VERSION ""

NS_ :

BS_:

BU_: APIM_CISM APIM ESPM DSP FCIMB RACM_RCIM HUD_ADV WCM TRM_ITRM ACM GWM _delete IPC GENERIC TSTR

BO_ 549 IPC_Infotainment: 8 IPC
 SG_ BattTracLoThres_D_Rq2 : 52|3@0+ (1,0) [0|7] "SED"  GWM
 SG_ NavIod_D_Rq : 55|3@0+ (1,0) [0|7] "SED"  GWM,APIM_CISM
 SG_ StrtInGearOk_D_Stat : 17|2@0+ (1,0) [0|3] "SED"  GWM
 SG_ WwaActv_B_Stat : 46|1@0+ (1,0) [0|1] "SED"  APIM,APIM_CISM,GWM,ACM
 SG_ Veh_V2_Dsply : 39|9@0+ (1,0) [0|511] "unitless"  APIM,APIM_CISM,GWM,HUD_ADV
 SG_ IPC_MyKeyVolLimit_St : 9|2@0+ (1,0) [0|3] "SED"  APIM,APIM_CISM,GWM,DSP,ACM
 SG_ HudVertSzMnuOn_B_Rq : 21|1@0+ (1,0) [0|1] "SED"  GWM,HUD_ADV
 SG_ HudVertMnuOn_B_Rq : 11|1@0+ (1,0) [0|1] "SED"  GWM,HUD_ADV
 SG_ HudRotatMnuOn_B_Rq : 22|1@0+ (1,0) [0|1] "SED"  GWM,HUD_ADV
 SG_ HudCntntMnuOn_B_Rq : 20|1@0+ (1,0) [0|1] "SED"  GWM,HUD_ADV
 SG_ HudBrightMnuOn_B_Rq : 1|1@0+ (1,0) [0|1] "SED"  GWM,HUD_ADV
 SG_ HdcOn_B_Rq : 19|1@0+ (1,0) [0|1] "SED"  GWM
 SG_ IPC_Attn_Info_Audio : 4|3@0+ (1,0) [0|7] "SED"  APIM,APIM_CISM,GWM,DSP,ACM
 SG_ BeltminderAudioMute : 6|2@0+ (1,0) [0|3] "SED"  APIM,APIM_CISM,GWM,DSP,ACM
 SG_ Power_Up_Chime_Modules : 23|1@0+ (1,0) [0|1] "SED"  APIM_CISM,GWM,DSP,ACM
 SG_ Chime_Source : 15|2@0+ (1,0) [0|3] "SED"  APIM_CISM,GWM,DSP,ACM
 SG_ CCOI_PolicyClient_St2 : 45|4@0+ (1,0) [0|15] "SED"  GWM
 SG_ FactoryReset_Rq2 : 18|1@0+ (1,0) [0|1] "SED"  GWM
 SG_ IPC_New_Attn_Event : 0|1@0+ (1,0) [0|1] "SED"  APIM,APIM_CISM,GWM,DSP,ACM
 SG_ MetricActv_B_Dsply : 7|1@0+ (1,0) [0|1] "SED"  HUD_ADV,GWM,GENERIC

BO_ 765 Mc_Send_Signals_2: 8 IPC
 SG_ BalrSwtch_D_Stat : 57|2@0+ (1,0) [0|3] "SED"  GWM
 SG_ BalrMde_D_Rq : 59|2@0+ (1,0) [0|3] "SED"  GWM
 SG_ RstrnOnPsngr_D_RqMnu : 63|4@0+ (1,0) [0|15] "SED"  GWM
 SG_ WaitToStartLamp_D_Falt : 50|2@0+ (1,0) [0|3] "SED"  GWM
 SG_ EsaOn_B_Rq : 15|1@0+ (1,0) [0|1] "SED"  GWM
 SG_ BttOn_B_Rq : 26|1@0+ (1,0) [0|1] "SED"  GWM
 SG_ Btt_L_Actl : 39|7@0+ (0.1,0) [0|12.5] "meter"  GWM
 SG_ RearDiffLck_D_RqArb : 25|2@0+ (1,0) [0|3] "SED"  GWM
 SG_ AwdMde_D_RqArb : 47|3@0+ (1,0) [0|7] "SED"  GWM
 SG_ SelDrvMdeTxtReset_B_Rq : 40|1@0+ (1,0) [0|1] "SED"  GWM
 SG_ AutoTowAllw_D_RqMnu : 52|2@0+ (1,0) [0|3] "SED"  GWM
 SG_ DrvInputRequired_B_Rq : 32|1@0+ (1,0) [0|1] "SED"  GWM
 SG_ SelDrvMdeDsply_B_Avail : 41|1@0+ (1,0) [0|1] "SED"  GWM
 SG_ EngExhMdeQuiet_D_Rq : 17|2@0+ (1,0) [0|3] "SED"  GWM
 SG_ AirSusp_D_RqDrv : 31|2@0+ (1,0) [0|3] "SED"  GWM
 SG_ Mc_VehUntTrpCoUsrSel_St : 23|1@0+ (1,0) [0|1] "SED"  APIM,APIM_CISM,HUD_ADV,GWM
 SG_ Mc_VehUnitTempUsrSel_St : 22|1@0+ (1,0) [0|1] "SED"  APIM,APIM_CISM,HUD_ADV,RACM_RCIM,GWM
 SG_ Mc_VehDayNightUsrSel_St : 14|3@0+ (1,0) [0|7] "SED"  APIM,APIM_CISM,GWM,ACM
 SG_ Mc_VehTimeFrmtUsrSel_St : 1|2@0+ (1,0) [0|3] "SED"  APIM,APIM_CISM,GWM,HUD_ADV,RACM_RCIM
 SG_ Mc_VehThemeUsrSel_St : 11|4@0+ (1,0) [0|15] "SED"  APIM,APIM_CISM,GWM,GENERIC
 SG_ Mc_VehLangUsrSel_St : 7|6@0+ (1,0) [0|63] "SED"  APIM,APIM_CISM,HUD_ADV,ACM,GWM
 SG_ AwdRnge_D_ActlIpc : 29|3@0+ (1,0) [0|7] "SED"  GWM
 SG_ AwdDrvMde_D_Rq : 44|3@0+ (1,0) [0|7] "SED"  GWM
 SG_ EngExhMdeQuiet_D2_Rq : 55|3@0+ (1,0) [0|7] "SED"  GWM
 SG_ BrkLineLck_D_Rq : 19|2@0+ (1,0) [0|3] "SED"  GWM
 SG_ EdmSailMde_B_RqDrv : 48|1@0+ (1,0) [0|1] "SED"  GWM
 SG_ Running_Board_Cmd : 21|2@0+ (1,0) [0|3] "SED"  GWM

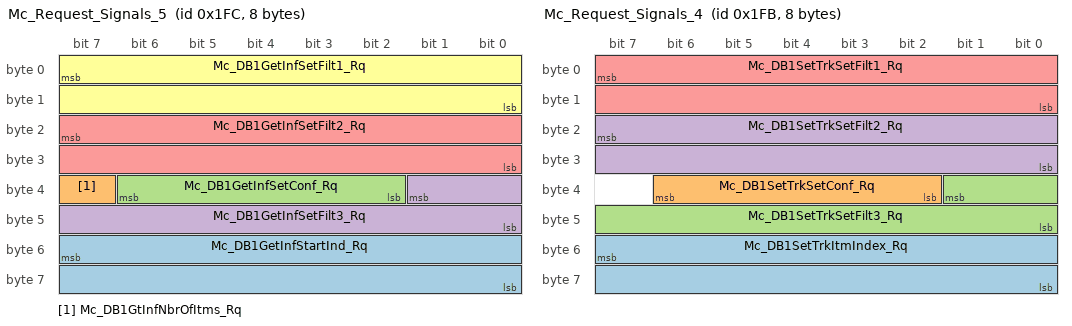
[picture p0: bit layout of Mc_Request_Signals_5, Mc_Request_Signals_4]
BO_ 508 Mc_Request_Signals_5: 8 IPC
 SG_ Mc_DB1GetInfStartInd_Rq : 55|16@0+ (1,0) [0|65535] "unitless"  APIM_CISM,ACM,GWM
 SG_ Mc_DB1GtInfNbrOfItms_Rq : 39|1@0+ (1,0) [0|1] "SED"  APIM_CISM,ACM,GWM
 SG_ Mc_DB1GetInfSetConf_Rq : 38|5@0+ (1,0) [0|31] "SED"  APIM_CISM,ACM,GWM
 SG_ Mc_DB1GetInfSetFilt3_Rq : 33|10@0+ (1,0) [0|1023] "unitless"  APIM_CISM,ACM,GWM
 SG_ Mc_DB1GetInfSetFilt2_Rq : 23|16@0+ (1,0) [0|65535] "unitless"  APIM_CISM,ACM,GWM
 SG_ Mc_DB1GetInfSetFilt1_Rq : 7|16@0+ (1,0) [0|65535] "unitless"  APIM_CISM,ACM,GWM

BO_ 507 Mc_Request_Signals_4: 8 IPC
 SG_ Mc_DB1SetTrkItmIndex_Rq : 55|16@0+ (1,0) [0|65535] "unitless"  APIM_CISM,ACM,GWM
 SG_ Mc_DB1SetTrkSetConf_Rq : 38|5@0+ (1,0) [0|31] "SED"  APIM_CISM,ACM,GWM
 SG_ Mc_DB1SetTrkSetFilt3_Rq : 33|10@0+ (1,0) [0|1023] "unitless"  APIM_CISM,ACM,GWM
 SG_ Mc_DB1SetTrkSetFilt2_Rq : 23|16@0+ (1,0) [0|65535] "unitless"  APIM_CISM,ACM,GWM
 SG_ Mc_DB1SetTrkSetFilt1_Rq : 7|16@0+ (1,0) [0|65535] "unitless"  APIM_CISM,ACM,GWM

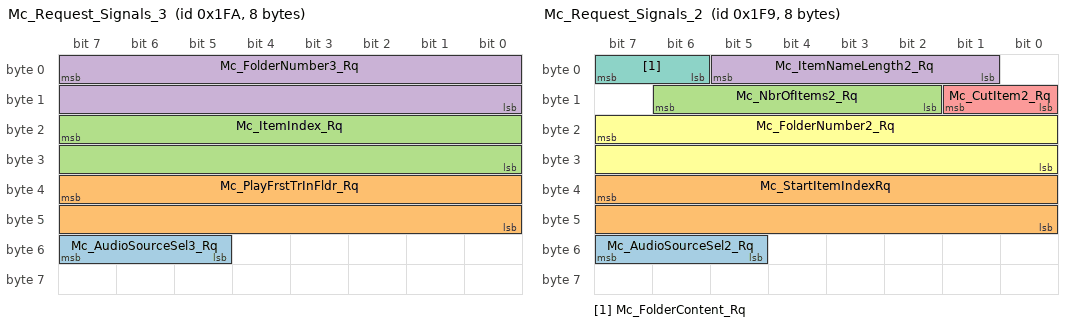
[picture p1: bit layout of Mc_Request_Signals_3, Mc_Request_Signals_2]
BO_ 506 Mc_Request_Signals_3: 8 IPC
 SG_ Mc_AudioSourceSel3_Rq : 55|3@0+ (1,0) [0|7] "SED"  APIM_CISM,ACM,GWM
 SG_ Mc_PlayFrstTrInFldr_Rq : 39|16@0+ (1,0) [0|65535] "unitless"  APIM_CISM,ACM,GWM
 SG_ Mc_ItemIndex_Rq : 23|16@0+ (1,0) [0|65535] "unitless"  APIM_CISM,ACM,GWM
 SG_ Mc_FolderNumber3_Rq : 7|16@0+ (1,0) [0|65535] "unitless"  APIM_CISM,ACM,GWM

BO_ 505 Mc_Request_Signals_2: 8 IPC
 SG_ Mc_AudioSourceSel2_Rq : 55|3@0+ (1,0) [0|7] "SED"  APIM_CISM,ACM,GWM
 SG_ Mc_StartItemIndexRq : 39|16@0+ (1,0) [0|65535] "unitless"  APIM_CISM,ACM,GWM
 SG_ Mc_NbrOfItems2_Rq : 14|5@0+ (1,0) [0|20] "SED"  APIM_CISM,ACM,GWM
 SG_ Mc_ItemNameLength2_Rq : 5|5@0+ (1,0) [0|20] "SED"  APIM_CISM,ACM,GWM
 SG_ Mc_CutItem2_Rq : 9|2@0+ (1,0) [0|3] "SED"  APIM_CISM,ACM,GWM
 SG_ Mc_FolderNumber2_Rq : 23|16@0+ (1,0) [0|65535] "unitless"  APIM_CISM,ACM,GWM
 SG_ Mc_FolderContent_Rq : 7|2@0+ (1,0) [0|3] "SED"  APIM_CISM,ACM,GWM

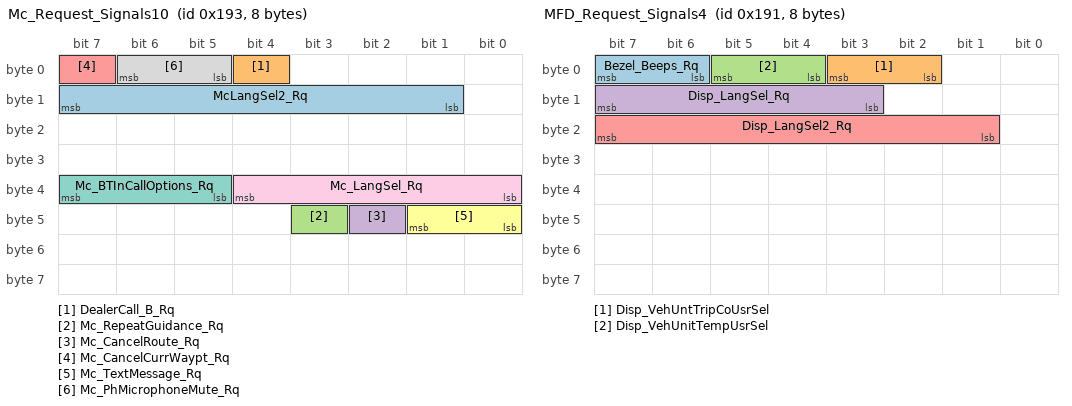
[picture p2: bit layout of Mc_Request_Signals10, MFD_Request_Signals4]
BO_ 403 Mc_Request_Signals10: 8 IPC
 SG_ McLangSel2_Rq : 15|7@0+ (1,0) [0|7] "SED"  APIM,APIM_CISM,GWM
 SG_ DealerCall_B_Rq : 4|1@0+ (1,0) [0|1] "SED"  APIM,APIM_CISM,GWM
 SG_ Mc_RepeatGuidance_Rq : 43|1@0+ (1,0) [0|1] "SED"  APIM,APIM_CISM,GWM
 SG_ Mc_CancelRoute_Rq : 42|1@0+ (1,0) [0|1] "SED"  APIM,APIM_CISM,GWM
 SG_ Mc_CancelCurrWaypt_Rq : 7|1@0+ (1,0) [0|1] "SED"  APIM,APIM_CISM,GWM
 SG_ Mc_TextMessage_Rq : 41|2@0+ (1,0) [0|3] "SED"  APIM,APIM_CISM,GWM
 SG_ Mc_BTInCallOptions_Rq : 39|3@0+ (1,0) [0|7] "SED"  APIM,APIM_CISM,GWM
 SG_ Mc_PhMicrophoneMute_Rq : 6|2@0+ (1,0) [0|3] "SED"  APIM,APIM_CISM,GWM
 SG_ Mc_LangSel_Rq : 36|5@0+ (1,0) [0|31] "SED"  APIM,APIM_CISM,GWM

BO_ 401 MFD_Request_Signals4: 8 APIM
 SG_ Bezel_Beeps_Rq : 7|2@0+ (1,0) [0|3] "SED"  FCIMB,GWM
 SG_ Disp_VehUntTripCoUsrSel : 3|2@0+ (1,0) [0|3] "SED"  GWM,IPC
 SG_ Disp_VehUnitTempUsrSel : 5|2@0+ (1,0) [0|3] "SED"  GWM,IPC
 SG_ Disp_LangSel_Rq : 15|5@0+ (1,0) [0|31] "SED"  GWM,IPC
 SG_ Disp_LangSel2_Rq : 23|7@0+ (1,0) [0|127] "SED"  IPC

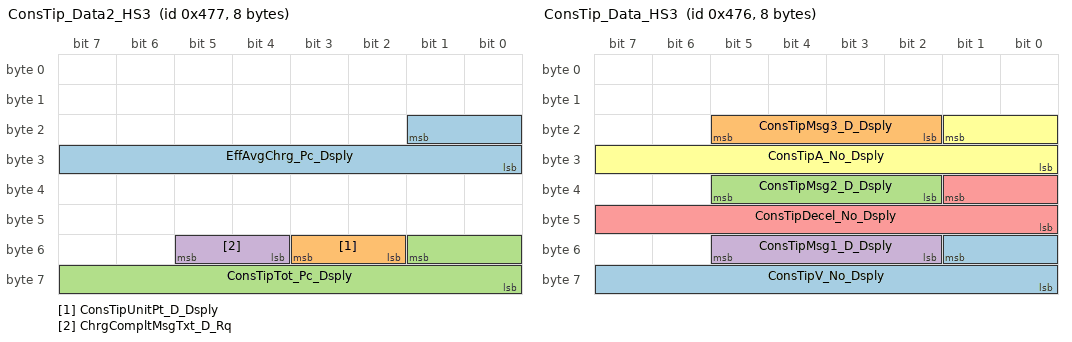
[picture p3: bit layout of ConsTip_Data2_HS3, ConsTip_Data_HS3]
BO_ 1143 ConsTip_Data2_HS3: 8 GWM
 SG_ EffAvgChrg_Pc_Dsply : 17|10@0+ (0.1,0) [0|102.3] "percent"  APIM_CISM,IPC
 SG_ ConsTipUnitPt_D_Dsply : 51|2@0+ (1,0) [0|3] "SED"  APIM,APIM_CISM,IPC
 SG_ ConsTipTot_Pc_Dsply : 49|10@0+ (0.1,0) [0|102.1] "percent"  IPC
 SG_ ChrgCompltMsgTxt_D_Rq : 53|2@0+ (1,0) [0|3] "SED"  APIM,APIM_CISM,IPC

BO_ 1142 ConsTip_Data_HS3: 8 GWM
 SG_ ConsTipV_No_Dsply : 49|10@0+ (0.1,0) [0|102.1] "percent"  APIM,APIM_CISM,IPC
 SG_ ConsTipMsg3_D_Dsply : 21|4@0+ (1,0) [0|15] "SED"  APIM,APIM_CISM,IPC
 SG_ ConsTipMsg2_D_Dsply : 37|4@0+ (1,0) [0|15] "SED"  APIM,APIM_CISM,IPC
 SG_ ConsTipMsg1_D_Dsply : 53|4@0+ (1,0) [0|15] "SED"  APIM,APIM_CISM,IPC
 SG_ ConsTipDecel_No_Dsply : 33|10@0+ (0.1,0) [0|102.1] "percent"  APIM,APIM_CISM,IPC
 SG_ ConsTipA_No_Dsply : 17|10@0+ (0.1,0) [0|102.1] "percent"  APIM,APIM_CISM,IPC

BO_ 973 Traffic_RecogitionData_HS3: 8 GWM
 SG_ PersCtaSplitView_D_Stat : 12|2@0+ (1,0) [0|3] "SED"  APIM,APIM_CISM
 SG_ LaSysOffStat_D_Dsply : 58|2@0+ (1,0) [0|3] "SED"  IPC
 SG_ TsrVl1RstrcMsgTxt2_D_Rq : 51|3@0+ (1,0) [0|7] "SED"  APIM_CISM,HUD_ADV,IPC
 SG_ TsrVl2RstrcMsgTxt2_D_Rq : 63|3@0+ (1,0) [0|7] "SED"  APIM_CISM,HUD_ADV,IPC
 SG_ TsrVl2PrmntMsgTxt_D_Rq : 60|2@0+ (1,0) [0|3] "SED"  APIM_CISM,HUD_ADV,IPC
 SG_ TsrVl1PrmntMsgTxt_D_Rq : 41|2@0+ (1,0) [0|3] "SED"  APIM_CISM,HUD_ADV,IPC
 SG_ TsrOvtkMsgTxt2_D_Rq : 55|4@0+ (1,0) [0|15] "SED"  APIM_CISM,HUD_ADV,IPC
 SG_ WwaWarn_B_Rq : 48|1@0+ (1,0) [0|1] "SED"  APIM_CISM,HUD_ADV,IPC
 SG_ RoadSignRgltry_D_Dsply : 19|2@0+ (1,0) [0|3] "SED"  IPC
 SG_ TsrVlUnitMsgTxt_D_Rq : 43|2@0+ (1,0) [0|3] "SED"  APIM,APIM_CISM,HUD_ADV,IPC
 SG_ TsrVLim2MsgTxt_D_Rq : 39|8@0+ (1,0) [0|255] "SED"  APIM_CISM,HUD_ADV,IPC
 SG_ TsrVLim1MsgTxt_D_Rq : 31|8@0+ (1,0) [0|255] "SED"  APIM_CISM,HUD_ADV,IPC
 SG_ TsrVl2StatMsgTxt_D_Rq : 47|2@0+ (1,0) [0|3] "SED"  APIM_CISM,HUD_ADV,IPC
 SG_ TsrVl2RstrcMsgTxt_D_Rq : 17|2@0+ (1,0) [0|3] "SED"  APIM_CISM,IPC
 SG_ TsrVl1StatMsgTxt_D_Rq : 21|2@0+ (1,0) [0|3] "SED"  APIM_CISM,HUD_ADV,IPC
 SG_ TsrVl1RstrcMsgTxt_D_Rq : 23|2@0+ (1,0) [0|3] "SED"  APIM_CISM,IPC
 SG_ TsrStatMsgTxt_D_Rq : 10|3@0+ (1,0) [0|7] "SED"  APIM_CISM,IPC
 SG_ TsrOvtkStatMsgTxt_D_Rq : 1|2@0+ (1,0) [0|3] "SED"  APIM_CISM,HUD_ADV,IPC
 SG_ TsrOvtkMsgTxt_D_Rq : 15|3@0+ (1,0) [0|7] "SED"  APIM_CISM,HUD_ADV,IPC
 SG_ TsrOswWarnMsgTxt_D_Rq : 3|2@0+ (1,0) [0|3] "SED"  APIM_CISM,HUD_ADV,IPC
 SG_ TsrMsgTxt_D_Rq : 7|4@0+ (1,0) [0|15] "SED"  APIM_CISM,IPC

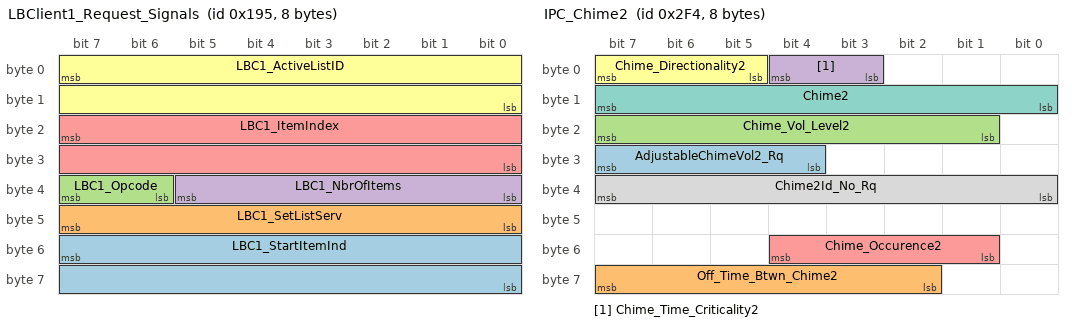
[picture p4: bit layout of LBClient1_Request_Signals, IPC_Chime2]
BO_ 405 LBClient1_Request_Signals: 8 IPC
 SG_ LBC1_StartItemInd : 55|16@0+ (1,0) [0|65535] "unitless"  APIM,APIM_CISM,GWM,ACM
 SG_ LBC1_SetListServ : 47|8@0+ (1,0) [0|255] "unitless"  APIM,APIM_CISM,GWM,ACM
 SG_ LBC1_Opcode : 39|2@0+ (1,0) [0|3] "SED"  APIM,APIM_CISM,GWM,ACM
 SG_ LBC1_NbrOfItems : 37|6@0+ (1,0) [0|63] "unitless"  APIM,APIM_CISM,GWM,ACM
 SG_ LBC1_ItemIndex : 23|16@0+ (1,0) [0|65535] "unitless"  APIM,APIM_CISM,GWM,ACM
 SG_ LBC1_ActiveListID : 7|16@0+ (1,0) [0|65535] "unitless"  APIM,APIM_CISM,GWM,ACM

BO_ 756 IPC_Chime2: 8 IPC
 SG_ AdjustableChimeVol2_Rq : 31|4@0+ (1,0) [0|15] "SED"  APIM_CISM,GWM,ACM,DSP
 SG_ Off_Time_Btwn_Chime2 : 63|6@0+ (1,0) [0|52] "unitless"  APIM_CISM,GWM,DSP,ACM
 SG_ Chime_Vol_Level2 : 23|7@0+ (1,0) [0|127] "unitless"  APIM_CISM,GWM,DSP,ACM
 SG_ Chime_Time_Criticality2 : 4|2@0+ (1,0) [0|3] "SED"  APIM_CISM,GWM,DSP,ACM
 SG_ Chime_Occurence2 : 52|4@0+ (1,0) [0|15] "SED"  APIM_CISM,GWM,DSP,ACM
 SG_ Chime_Directionality2 : 7|3@0+ (1,0) [0|7] "SED"  APIM_CISM,GWM,DSP,ACM
 SG_ Chime2 : 15|8@0+ (1,0) [0|255] "unitless"  APIM_CISM,GWM,DSP,ACM
 SG_ Chime2Id_No_Rq : 39|8@0+ (1,0) [0|255] "SED"  APIM_CISM,DSP,ACM

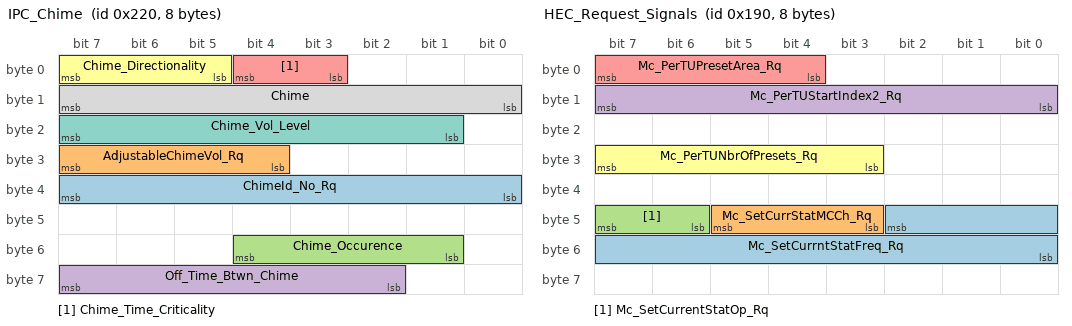
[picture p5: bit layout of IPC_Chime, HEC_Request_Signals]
BO_ 544 IPC_Chime: 8 IPC
 SG_ ChimeId_No_Rq : 39|8@0+ (1,0) [0|255] "SED"  APIM_CISM,GWM,ACM
 SG_ AdjustableChimeVol_Rq : 31|4@0+ (1,0) [0|15] "SED"  APIM_CISM,GWM,ACM,DSP
 SG_ Chime_Occurence : 52|4@0+ (1,0) [0|15] "SED"  APIM_CISM,GWM,DSP,ACM
 SG_ Off_Time_Btwn_Chime : 63|6@0+ (1,0) [0|52] "unitless"  APIM_CISM,GWM,DSP,ACM
 SG_ Chime_Time_Criticality : 4|2@0+ (1,0) [0|3] "SED"  APIM_CISM,GWM,DSP,ACM
 SG_ Chime_Directionality : 7|3@0+ (1,0) [0|7] "SED"  APIM_CISM,GWM,DSP,ACM
 SG_ Chime_Vol_Level : 23|7@0+ (1,0) [0|127] "unitless"  APIM_CISM,GWM,DSP,ACM
 SG_ Chime : 15|8@0+ (1,0) [0|255] "unitless"  APIM_CISM,GWM,DSP,ACM

BO_ 291 HEC_Response_Signals: 8 IPC
 SG_ LangUpdate_Rsp : 7|2@0+ (1,0) [0|3] "SED"  APIM,APIM_CISM,GWM

BO_ 400 HEC_Request_Signals: 8 IPC
 SG_ Mc_SetCurrntStatFreq_Rq : 42|11@0+ (1,0) [0|1557] "unitless"  GWM,APIM_CISM,ACM
 SG_ Mc_SetCurrStatMCCh_Rq : 45|3@0+ (1,0) [0|7] "SED"  GWM,APIM_CISM,ACM
 SG_ Mc_SetCurrentStatOp_Rq : 47|2@0+ (1,0) [0|3] "SED"  GWM,APIM_CISM,ACM
 SG_ Mc_PerTUStartIndex2_Rq : 15|8@0+ (1,0) [0|255] "unitless"  APIM,APIM_CISM,ACM,GWM
 SG_ Mc_PerTUPresetArea_Rq : 7|4@0+ (1,0) [0|15] "SED"  APIM,APIM_CISM,ACM,GWM
 SG_ Mc_PerTUNbrOfPresets_Rq : 31|5@0+ (1,0) [0|31] "SED"  APIM,APIM_CISM,ACM,GWM

BO_ 647 HEC_DispDimm: 8 IPC
 SG_ HEC_BTIncomingCall_Rq : 23|2@0+ (1,0) [0|3] "SED"  APIM,APIM_CISM
 SG_ HEC_BTEndTelService_Rq : 3|2@0+ (1,0) [0|3] "SED"  APIM,APIM_CISM

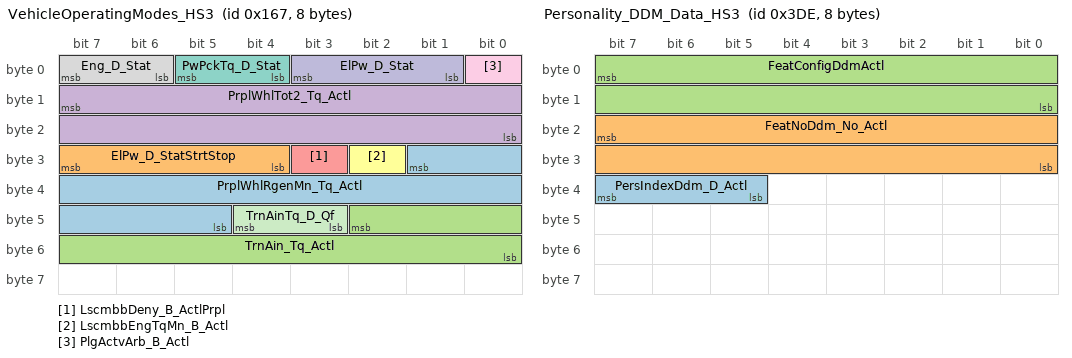
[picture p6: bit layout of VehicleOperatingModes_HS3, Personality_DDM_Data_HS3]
BO_ 359 VehicleOperatingModes_HS3: 8 GWM
 SG_ PrplWhlRgenMn_Tq_Actl : 25|13@0+ (4,-16380) [-16380|16380] "Nm"  GENERIC
 SG_ ElPw_D_StatStrtStop : 31|4@0+ (1,0) [0|15] "SED"  GENERIC
 SG_ TrnAin_Tq_Actl : 42|11@0+ (1,-500) [-500|1547] "Nm"  APIM,APIM_CISM,IPC,ACM
 SG_ PrplWhlTot2_Tq_Actl : 15|16@0+ (4,-131072) [-131072|131060] "Nm"  APIM,APIM_CISM,IPC
 SG_ LscmbbDeny_B_ActlPrpl : 27|1@0+ (1,0) [0|1] "SED"  GENERIC
 SG_ LscmbbEngTqMn_B_Actl : 26|1@0+ (1,0) [0|1] "SED"  GENERIC
 SG_ PwPckTq_D_Stat : 5|2@0+ (1,0) [0|3] "SED"  APIM,APIM_CISM,RACM_RCIM,TRM_ITRM,DSP,ACM,WCM,IPC
 SG_ Eng_D_Stat : 7|2@0+ (1,0) [0|3] "SED"  APIM,APIM_CISM,RACM_RCIM,TRM_ITRM,WCM,DSP,ACM
 SG_ PlgActvArb_B_Actl : 0|1@0+ (1,0) [0|1] "SED"  IPC
 SG_ ElPw_D_Stat : 3|3@0+ (1,0) [0|7] "SED"  APIM,APIM_CISM,RACM_RCIM,TRM_ITRM,DSP,ACM,IPC
 SG_ TrnAinTq_D_Qf : 44|2@0+ (1,0) [0|3] "SED"  APIM_CISM,ACM

BO_ 990 Personality_DDM_Data_HS3: 8 GWM
 SG_ PersIndexDdm_D_Actl : 39|3@0+ (1,0) [0|7] "SED"  APIM,APIM_CISM,IPC
 SG_ FeatNoDdm_No_Actl : 23|16@0+ (1,0) [0|65535] "Number"  APIM,APIM_CISM,IPC
 SG_ FeatConfigDdmActl : 7|16@0+ (1,0) [0|65535] "Undefined"  APIM,APIM_CISM,IPC

BO_ 989 Personality_HCM_Data_HS3: 8 GWM
 SG_ FeatNoHcm_No_Actl : 23|16@0+ (1,0) [0|65535] "Number"  APIM,APIM_CISM,IPC
 SG_ FeatConfigHcmActl : 7|16@0+ (1,0) [0|65535] "Undefined"  APIM,APIM_CISM,IPC

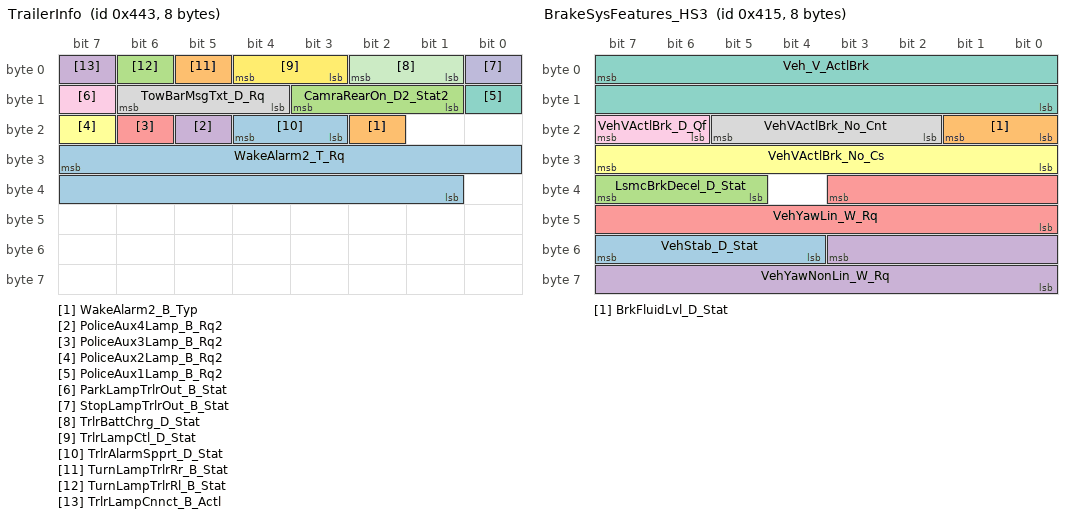
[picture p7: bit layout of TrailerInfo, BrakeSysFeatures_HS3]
BO_ 1091 TrailerInfo: 8 TRM_ITRM
 SG_ WakeAlarm2_T_Rq : 31|15@0+ (1,0) [0|32767] "minute"  GWM
 SG_ WakeAlarm2_B_Typ : 18|1@0+ (1,0) [0|1] "SED"  GWM
 SG_ CamraRearOn_D2_Stat2 : 11|3@0+ (1,0) [0|7] "SED"  APIM,APIM_CISM,GWM
 SG_ PoliceAux4Lamp_B_Rq2 : 21|1@0+ (1,0) [0|1] "SED"  IPC,GWM
 SG_ PoliceAux3Lamp_B_Rq2 : 22|1@0+ (1,0) [0|1] "SED"  IPC,GWM
 SG_ PoliceAux2Lamp_B_Rq2 : 23|1@0+ (1,0) [0|1] "SED"  IPC,GWM
 SG_ PoliceAux1Lamp_B_Rq2 : 8|1@0+ (1,0) [0|1] "SED"  IPC,GWM
 SG_ TowBarMsgTxt_D_Rq : 14|3@0+ (1,0) [0|7] "SED"  IPC,GWM
 SG_ ParkLampTrlrOut_B_Stat : 15|1@0+ (1,0) [0|1] "SED"  IPC,GWM
 SG_ StopLampTrlrOut_B_Stat : 0|1@0+ (1,0) [0|1] "SED"  IPC,GWM
 SG_ TrlrBattChrg_D_Stat : 2|2@0+ (1,0) [0|3] "SED"  IPC,GWM
 SG_ TrlrLampCtl_D_Stat : 4|2@0+ (1,0) [0|3] "SED"  IPC,GWM
 SG_ TrlrAlarmSpprt_D_Stat : 20|2@0+ (1,0) [0|3] "SED"  APIM,APIM_CISM,GWM
 SG_ TurnLampTrlrRr_B_Stat : 5|1@0+ (1,0) [0|1] "SED"  IPC,GWM
 SG_ TurnLampTrlrRl_B_Stat : 6|1@0+ (1,0) [0|1] "SED"  IPC,GWM
 SG_ TrlrLampCnnct_B_Actl : 7|1@0+ (1,0) [0|1] "SED"  APIM,APIM_CISM,IPC,GWM

BO_ 1045 BrakeSysFeatures_HS3: 8 GWM
 SG_ VehStab_D_Stat : 55|4@0+ (1,0) [0|15] "SED" Vector__XXX
 SG_ BrkFluidLvl_D_Stat : 17|2@0+ (1,0) [0|3] "SED" Vector__XXX
 SG_ LsmcBrkDecel_D_Stat : 39|3@0+ (1,0) [0|7] "SED" Vector__XXX
 SG_ VehYawNonLin_W_Rq : 51|12@0+ (0.03663,-75) [-75|74.92659] "deg/s" Vector__XXX
 SG_ VehYawLin_W_Rq : 35|12@0+ (0.03663,-75) [-75|74.92659] "deg/s" Vector__XXX
 SG_ VehVActlBrk_No_Cs : 31|8@0+ (1,0) [0|255] "unitless"  TRM_ITRM
 SG_ Veh_V_ActlBrk : 7|16@0+ (0.01,0) [0|655.35] "kph"  TRM_ITRM
 SG_ VehVActlBrk_No_Cnt : 21|4@0+ (1,0) [0|15] "unitless"  TRM_ITRM
 SG_ VehVActlBrk_D_Qf : 23|2@0+ (1,0) [0|3] "SED"  TRM_ITRM

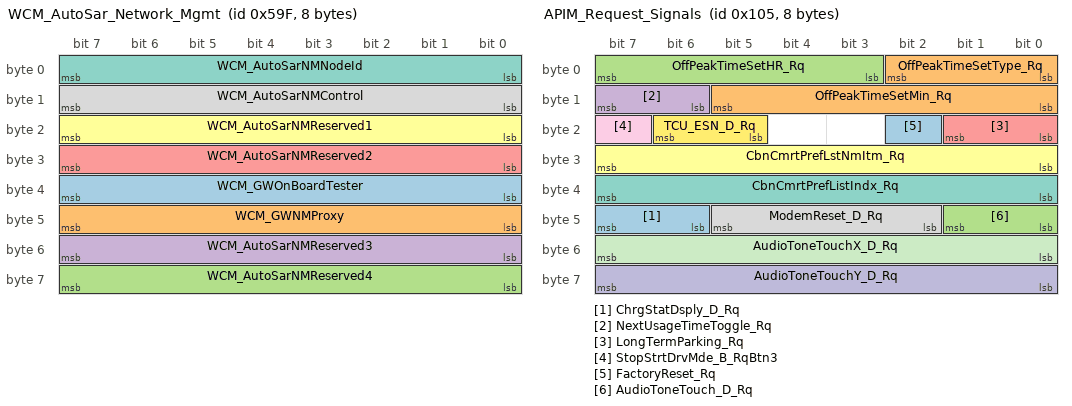
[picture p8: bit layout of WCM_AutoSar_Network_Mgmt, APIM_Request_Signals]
BO_ 1439 WCM_AutoSar_Network_Mgmt: 8 WCM
 SG_ WCM_GWOnBoardTester : 39|8@0+ (1,0) [0|255] "unitless"  IPC,HUD_ADV,GENERIC,ACM
 SG_ WCM_GWNMProxy : 47|8@0+ (1,0) [0|255] "unitless"  IPC,HUD_ADV,GENERIC,ACM
 SG_ WCM_AutoSarNMReserved4 : 63|8@0+ (1,0) [0|255] "unitless"  IPC,HUD_ADV,GENERIC,ACM
 SG_ WCM_AutoSarNMReserved3 : 55|8@0+ (1,0) [0|255] "unitless"  IPC,HUD_ADV,GENERIC,ACM
 SG_ WCM_AutoSarNMReserved2 : 31|8@0+ (1,0) [0|255] "unitless"  IPC,HUD_ADV,GENERIC,ACM
 SG_ WCM_AutoSarNMReserved1 : 23|8@0+ (1,0) [0|255] "unitless"  IPC,HUD_ADV,GENERIC,ACM
 SG_ WCM_AutoSarNMNodeId : 7|8@0+ (1,0) [0|255] "unitless"  IPC,HUD_ADV,GENERIC,ACM
 SG_ WCM_AutoSarNMControl : 15|8@0+ (1,0) [0|255] "unitless"  IPC,HUD_ADV,GENERIC,ACM

BO_ 261 APIM_Request_Signals: 8 ACM
 SG_ ChrgStatDsply_D_Rq : 47|2@0+ (1,0) [0|3] "SED"  GWM
 SG_ OffPeakTimeSetMin_Rq : 13|6@0+ (1,0) [0|63] "unitless"  GWM
 SG_ OffPeakTimeSetHR_Rq : 7|5@0+ (1,0) [0|31] "unitless"  GWM
 SG_ NextUsageTimeToggle_Rq : 15|2@0+ (1,0) [0|3] "SED"  GWM
 SG_ LongTermParking_Rq : 17|2@0+ (1,0) [0|3] "SED"  GWM
 SG_ CbnCmrtPrefLstNmItm_Rq : 31|8@0+ (1,0) [0|255] "unitless"  GWM
 SG_ CbnCmrtPrefListIndx_Rq : 39|8@0+ (1,0) [0|255] "unitless"  GWM
 SG_ ModemReset_D_Rq : 45|4@0+ (1,0) [0|15] "SED"  GWM
 SG_ StopStrtDrvMde_B_RqBtn3 : 23|1@0+ (1,0) [0|1] "SED"  GWM
 SG_ AudioToneTouchY_D_Rq : 63|8@0+ (1,0) [0|255] "SED"  DSP,GWM
 SG_ AudioToneTouchX_D_Rq : 55|8@0+ (1,0) [0|255] "SED"  DSP,GWM
 SG_ TCU_ESN_D_Rq : 22|2@0+ (1,0) [0|3] "SED"  GWM
 SG_ FactoryReset_Rq : 18|1@0+ (1,0) [0|1] "SED"  GWM
 SG_ OffPeakTimeSetType_Rq : 2|3@0+ (1,0) [0|7] "SED"  GWM
 SG_ AudioToneTouch_D_Rq : 41|2@0+ (1,0) [0|3] "SED"  DSP,GWM

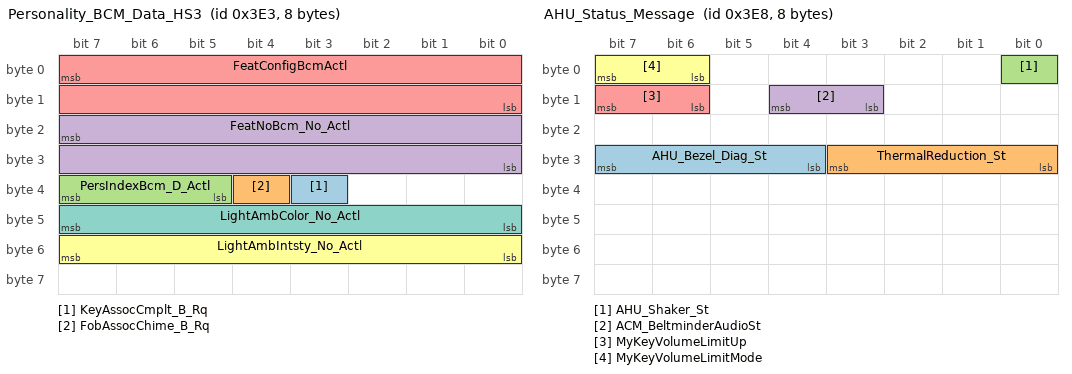
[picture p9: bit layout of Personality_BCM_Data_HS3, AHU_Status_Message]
BO_ 995 Personality_BCM_Data_HS3: 8 GWM
 SG_ KeyAssocCmplt_B_Rq : 35|1@0+ (1,0) [0|1] "SED"  IPC
 SG_ FobAssocChime_B_Rq : 36|1@0+ (1,0) [0|1] "SED"  IPC
 SG_ PersIndexBcm_D_Actl : 39|3@0+ (1,0) [0|7] "SED"  APIM,APIM_CISM,IPC
 SG_ FeatNoBcm_No_Actl : 23|16@0+ (1,0) [0|65535] "Number"  APIM,APIM_CISM,IPC
 SG_ FeatConfigBcmActl : 7|16@0+ (1,0) [0|65535] "Undefined"  APIM,APIM_CISM,IPC
 SG_ LightAmbIntsty_No_Actl : 55|8@0+ (1,0) [0|255] "unitless"  APIM,APIM_CISM
 SG_ LightAmbColor_No_Actl : 47|8@0+ (1,0) [0|255] "Discrete"  APIM,APIM_CISM

BO_ 753 Vehicle_Stat: 8 APIM
 SG_ RollCodeValet : 7|16@0+ (1,0) [0|65535] "unitless"  GWM

BO_ 1000 AHU_Status_Message: 8 ACM
 SG_ AHU_Bezel_Diag_St : 31|4@0+ (1,0) [0|15] "SED"  APIM
 SG_ ThermalReduction_St : 27|4@0+ (1,0) [0|15] "SED"  DSP
 SG_ AHU_Shaker_St : 0|1@0+ (1,0) [0|1] "SED"  APIM,GWM
 SG_ ACM_BeltminderAudioSt : 12|2@0+ (1,0) [0|3] "SED"  APIM,IPC
 SG_ MyKeyVolumeLimitUp : 15|2@0+ (1,0) [0|3] "SED"  APIM
 SG_ MyKeyVolumeLimitMode : 7|2@0+ (1,0) [0|3] "SED"  APIM

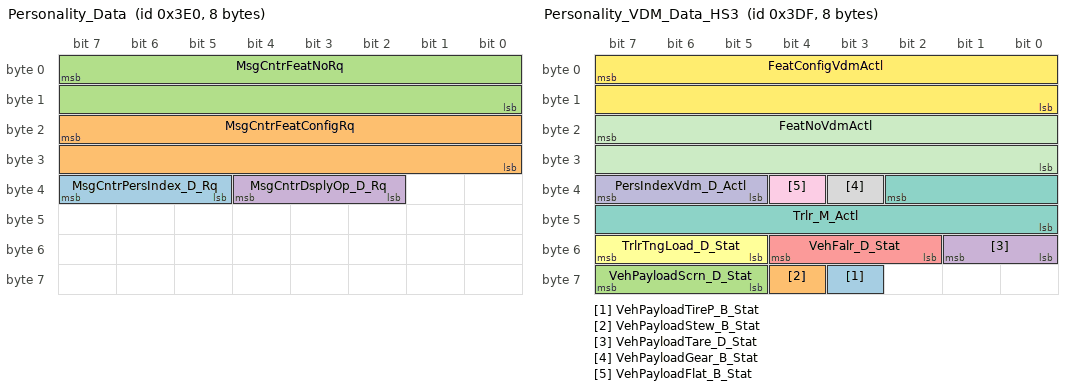
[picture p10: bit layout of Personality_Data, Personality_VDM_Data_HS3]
BO_ 992 Personality_Data: 8 IPC
 SG_ MsgCntrPersIndex_D_Rq : 39|3@0+ (1,0) [0|7] "SED"  HUD_ADV,GWM
 SG_ MsgCntrFeatConfigRq : 23|16@0+ (1,0) [0|65535] "unitless"  HUD_ADV,GWM
 SG_ MsgCntrFeatNoRq : 7|16@0+ (1,0) [0|65535] "Number"  HUD_ADV,GWM
 SG_ MsgCntrDsplyOp_D_Rq : 36|3@0+ (1,0) [0|7] "SED"  HUD_ADV,GWM

BO_ 991 Personality_VDM_Data_HS3: 8 GWM
 SG_ VehPayloadTireP_B_Stat : 59|1@0+ (1,0) [0|1] "SED"  APIM,APIM_CISM
 SG_ VehPayloadStew_B_Stat : 60|1@0+ (1,0) [0|1] "SED"  APIM,APIM_CISM
 SG_ VehPayloadScrn_D_Stat : 63|3@0+ (1,0) [0|7] "SED"  APIM,APIM_CISM
 SG_ VehPayloadTare_D_Stat : 49|2@0+ (1,0) [0|3] "SED"  APIM,APIM_CISM
 SG_ VehFalr_D_Stat : 52|3@0+ (1,0) [0|7] "SED"  APIM,APIM_CISM
 SG_ TrlrTngLoad_D_Stat : 55|3@0+ (1,0) [0|7] "SED" Vector__XXX
 SG_ Trlr_M_Actl : 34|11@0+ (10,0) [0|20450] "kilogram"  APIM,APIM_CISM
 SG_ VehPayloadGear_B_Stat : 35|1@0+ (1,0) [0|1] "SED"  APIM,APIM_CISM
 SG_ VehPayloadFlat_B_Stat : 36|1@0+ (1,0) [0|1] "SED"  APIM,APIM_CISM
 SG_ PersIndexVdm_D_Actl : 39|3@0+ (1,0) [0|7] "SED"  APIM,APIM_CISM,IPC
 SG_ FeatNoVdmActl : 23|16@0+ (1,0) [0|65535] "Number"  APIM,APIM_CISM,IPC
 SG_ FeatConfigVdmActl : 7|16@0+ (1,0) [0|65535] "Undefined"  APIM,APIM_CISM,IPC

BO_ 1004 Personality_BCM2_Data_HS3: 8 GWM
 SG_ TailLghtLoadMde_D_Stat : 60|3@0+ (1,0) [0|7] "SED"  APIM,APIM_CISM
 SG_ PersRecallSrc_D_Actl : 63|3@0+ (1,0) [0|7] "SED" Vector__XXX
 SG_ Pers4Key_D_Stat : 49|2@0+ (1,0) [0|3] "SED"  APIM,APIM_CISM
 SG_ Pers3Key_D_Stat : 41|2@0+ (1,0) [0|3] "SED"  APIM,APIM_CISM
 SG_ Pers2Key_D_Stat : 43|2@0+ (1,0) [0|3] "SED"  APIM,APIM_CISM
 SG_ Pers1Key_D_Stat : 12|2@0+ (1,0) [0|3] "SED"  APIM,APIM_CISM
 SG_ EmPrflKeyAssoc_D_Stat : 55|3@0+ (1,0) [0|7] "SED"  APIM,APIM_CISM
 SG_ VehKeyActv_D_Stat : 47|4@0+ (1,0) [0|15] "SED"  IPC
 SG_ PersSetupRestr_D_Actl : 21|2@0+ (1,0) [0|3] "SED"  APIM,APIM_CISM
 SG_ PersSetupAccessCtrl : 19|1@0+ (1,0) [0|1] "SED"  APIM,APIM_CISM
 SG_ PersSetup_No_Actl : 31|16@0+ (1,0) [0|65535] "Number"  APIM,APIM_CISM
 SG_ PersConflict_D_Actl : 22|1@0+ (1,0) [0|1] "SED"  APIM,APIM_CISM
 SG_ AssocConfirm_D_Actl : 15|3@0+ (1,0) [0|7] "SED"  APIM,APIM_CISM
 SG_ RecallEvent_No_Cnt : 7|8@0+ (1,0) [0|255] "Counts"  APIM,APIM_CISM,DSP,HUD_ADV,IPC,ACM
 SG_ PersNoPos_D_Actl : 18|3@0+ (1,0) [0|7] "SED"  APIM,APIM_CISM,IPC
 SG_ PersNo_D_Actl : 10|3@0+ (1,0) [0|7] "SED"  APIM,APIM_CISM,DSP,ACM,IPC
 SG_ EmPrflNo_D_Stat : 52|3@0+ (1,0) [0|7] "SED"  APIM,APIM_CISM

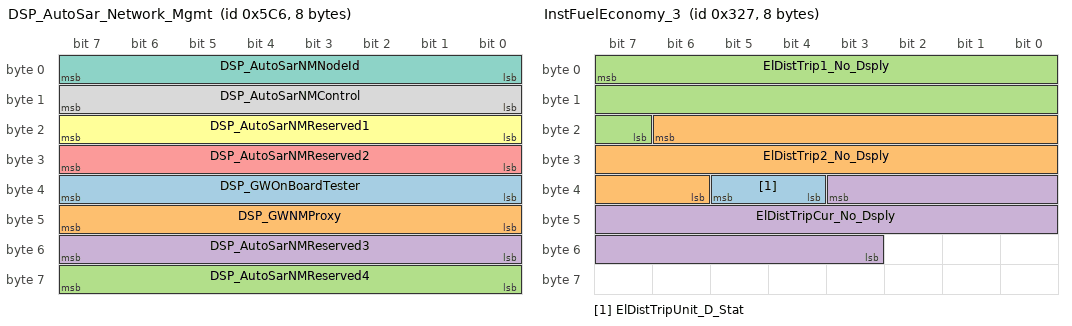
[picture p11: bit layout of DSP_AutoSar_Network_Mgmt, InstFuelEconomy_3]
BO_ 1478 DSP_AutoSar_Network_Mgmt: 8 DSP
 SG_ DSP_GWOnBoardTester : 39|8@0+ (1,0) [0|255] "unitless"  IPC,ACM,HUD_ADV
 SG_ DSP_GWNMProxy : 47|8@0+ (1,0) [0|255] "unitless"  IPC,ACM,HUD_ADV
 SG_ DSP_AutoSarNMReserved4 : 63|8@0+ (1,0) [0|255] "unitless"  IPC,ACM,HUD_ADV
 SG_ DSP_AutoSarNMReserved3 : 55|8@0+ (1,0) [0|255] "unitless"  IPC,ACM,HUD_ADV
 SG_ DSP_AutoSarNMReserved2 : 31|8@0+ (1,0) [0|255] "unitless"  IPC,ACM,HUD_ADV
 SG_ DSP_AutoSarNMReserved1 : 23|8@0+ (1,0) [0|255] "unitless"  IPC,ACM,HUD_ADV
 SG_ DSP_AutoSarNMNodeId : 7|8@0+ (1,0) [0|255] "unitless"  IPC,ACM,HUD_ADV
 SG_ DSP_AutoSarNMControl : 15|8@0+ (1,0) [0|255] "unitless"  IPC,ACM,HUD_ADV

BO_ 813 TimerDisplay_Data2: 8 IPC
 SG_ TimerTripCurnt_T_Dsply : 7|26@0+ (1,0) [0|67108863] "second"  APIM,APIM_CISM

BO_ 807 InstFuelEconomy_3: 8 IPC
 SG_ ElDistTripUnit_D_Stat : 37|2@0+ (1,0) [0|3] "SED"  APIM,APIM_CISM
 SG_ ElDistTrip2_No_Dsply : 22|17@0+ (0.1,0) [0|13107.1] "unitless"  APIM,APIM_CISM
 SG_ ElDistTrip1_No_Dsply : 7|17@0+ (0.1,0) [0|13107.1] "unitless"  APIM,APIM_CISM
 SG_ ElDistTripCur_No_Dsply : 35|17@0+ (0.1,0) [0|13107.1] "unitless"  APIM,APIM_CISM

BO_ 584 AUDIO_RDISP2_WORD_Rx: 8 HUD_ADV
 SG_ AUDIO_RDISP2_WORD_Rx : 7|64@0+ (1,0) [0|1.84467440737096E+019] "unitless"  APIM_CISM,ACM

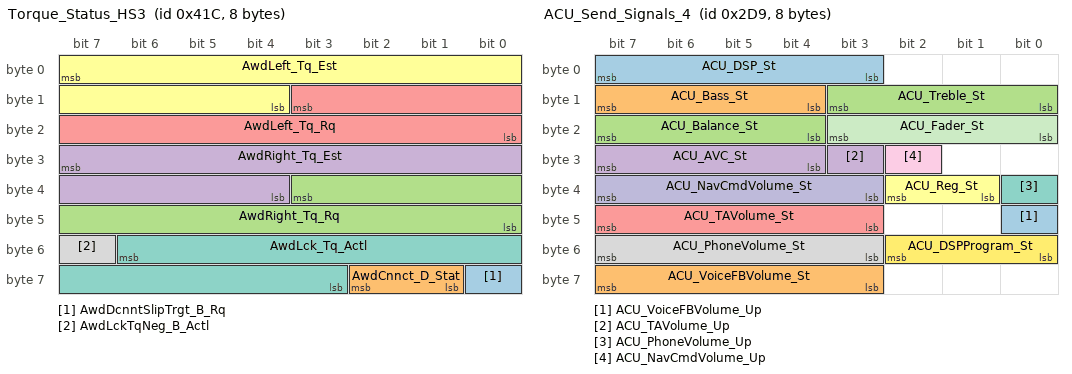
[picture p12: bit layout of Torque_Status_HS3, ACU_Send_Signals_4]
BO_ 1052 Torque_Status_HS3: 8 GWM
 SG_ AwdDcnntSlipTrgt_B_Rq : 56|1@0+ (1,0) [0|1] "SED" Vector__XXX
 SG_ AwdCnnct_D_Stat : 58|2@0+ (1,0) [0|3] "SED" Vector__XXX
 SG_ AwdRight_Tq_Rq : 35|12@0+ (1,0) [0|4093] "Nm" Vector__XXX
 SG_ AwdRight_Tq_Est : 31|12@0+ (1,0) [0|4093] "Nm" Vector__XXX
 SG_ AwdLeft_Tq_Rq : 11|12@0+ (1,0) [0|4093] "Nm" Vector__XXX
 SG_ AwdLeft_Tq_Est : 7|12@0+ (1,0) [0|4093] "Nm" Vector__XXX
 SG_ AwdLck_Tq_Actl : 54|12@0+ (1,0) [0|4093] "Nm"  IPC
 SG_ AwdLckTqNeg_B_Actl : 55|1@0+ (1,0) [0|1] "SED" Vector__XXX

BO_ 754 ACU_Send_Signals_14: 8 ACM
 SG_ ACU_ActChimeTypeDat_St : 5|14@0+ (1,0) [0|16383] "unitless"  DSP
 SG_ ACU_ActChimeType_St : 23|3@0+ (1,0) [0|7] "SED"  DSP

BO_ 729 ACU_Send_Signals_4: 8 APIM
 SG_ ACU_VoiceFBVolume_Up : 40|1@0+ (1,0) [0|1] "SED"  APIM,IPC,GWM
 SG_ ACU_VoiceFBVolume_St : 63|5@0+ (1,0) [0|30] "unitless"  APIM,WCM,IPC,GWM
 SG_ ACU_Treble_St : 11|4@0+ (1,-7) [-7|8] "unitless"  APIM,IPC,GWM
 SG_ ACU_TAVolume_Up : 27|1@0+ (1,0) [0|1] "SED"  APIM,IPC,GWM
 SG_ ACU_TAVolume_St : 47|5@0+ (1,0) [0|30] "SED"  APIM,WCM,IPC,GWM
 SG_ ACU_Reg_St : 34|2@0+ (1,0) [0|3] "SED"  APIM,GWM
 SG_ ACU_PhoneVolume_Up : 32|1@0+ (1,0) [0|1] "SED"  APIM,IPC,GWM
 SG_ ACU_PhoneVolume_St : 55|5@0+ (1,0) [0|30] "SED"  APIM,WCM,IPC,GWM
 SG_ ACU_NavCmdVolume_Up : 26|1@0+ (1,0) [0|1] "SED"  APIM,IPC,GWM
 SG_ ACU_NavCmdVolume_St : 39|5@0+ (1,0) [0|30] "SED"  APIM,WCM,IPC,GWM
 SG_ ACU_Fader_St : 19|4@0+ (1,-7) [-7|8] "unitless"  APIM,IPC,GWM
 SG_ ACU_DSPProgram_St : 50|3@0+ (1,0) [0|7] "SED"  APIM,GWM
 SG_ ACU_DSP_St : 7|5@0+ (1,0) [0|31] "SED"  APIM,GWM
 SG_ ACU_Bass_St : 15|4@0+ (1,-7) [-7|8] "unitless"  APIM
 SG_ ACU_Balance_St : 23|4@0+ (1,-7) [-7|8] "unitless"  APIM
 SG_ ACU_AVC_St : 31|4@0+ (1,0) [0|7] "unitless"  APIM

BO_ 727 ACU_Send_Signals_2: 8 ACM
 SG_ ACU_LoadEjectMode_St : 7|4@0+ (1,0) [0|15] "SED"  APIM,GWM
 SG_ ACU_LoadEjectDisc_St : 2|3@0+ (1,0) [0|7] "SED"  APIM,GWM

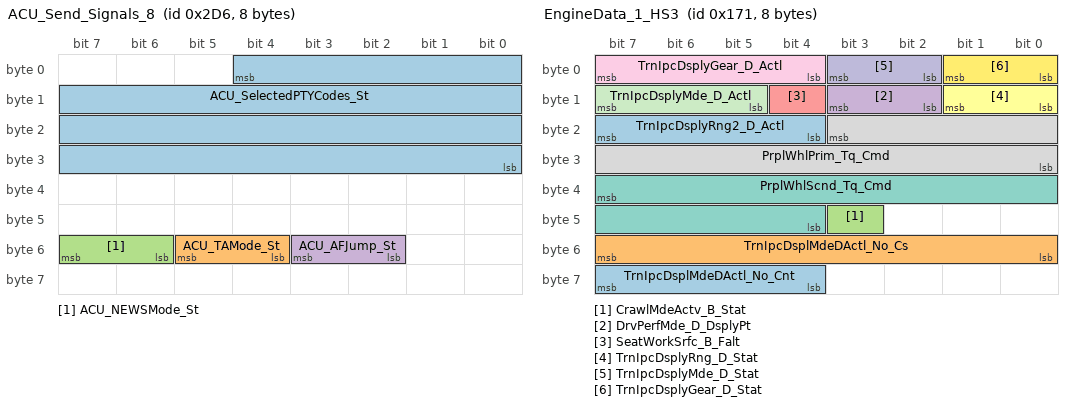
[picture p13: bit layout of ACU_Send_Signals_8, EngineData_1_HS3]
BO_ 726 ACU_Send_Signals_8: 8 APIM
 SG_ ACU_SelectedPTYCodes_St : 4|29@0+ (1,0) [0|536870911] "unitless"  APIM,GWM
 SG_ ACU_TAMode_St : 53|2@0+ (1,0) [0|3] "SED"  APIM,IPC,GWM
 SG_ ACU_NEWSMode_St : 55|2@0+ (1,0) [0|3] "SED"  APIM,IPC,GWM
 SG_ ACU_AFJump_St : 51|2@0+ (1,0) [0|3] "SED"  APIM,GWM

BO_ 369 EngineData_1_HS3: 8 GWM
 SG_ TrnIpcDsplMdeDActl_No_Cnt : 63|4@0+ (1,0) [0|15] "Unitless"  IPC
 SG_ TrnIpcDsplMdeDActl_No_Cs : 55|8@0+ (1,0) [0|255] "Unitless"  IPC
 SG_ CrawlMdeActv_B_Stat : 43|1@0+ (1,0) [0|1] "SED"  IPC
 SG_ DrvPerfMde_D_DsplyPt : 11|2@0+ (1,0) [0|3] "SED"  GENERIC
 SG_ SeatWorkSrfc_B_Falt : 12|1@0+ (1,0) [0|1] "SED"  IPC
 SG_ TrnIpcDsplyRng_D_Stat : 9|2@0+ (1,0) [0|3] "SED"  IPC
 SG_ PrplWhlScnd_Tq_Cmd : 39|12@0+ (8,-16380) [-16380|16380] "Nm"  GENERIC
 SG_ PrplWhlPrim_Tq_Cmd : 19|12@0+ (8,-16380) [-16380|16380] "Nm"  GENERIC
 SG_ TrnIpcDsplyGear_D_Actl : 7|4@0+ (1,0) [0|15] "SED"  APIM,APIM_CISM,HUD_ADV,IPC
 SG_ TrnIpcDsplyMde_D_Stat : 3|2@0+ (1,0) [0|3] "SED"  HUD_ADV,IPC
 SG_ TrnIpcDsplyMde_D_Actl : 15|3@0+ (1,0) [0|7] "SED"  APIM_CISM,HUD_ADV,IPC
 SG_ TrnIpcDsplyGear_D_Stat : 1|2@0+ (1,0) [0|3] "SED"  HUD_ADV,IPC
 SG_ TrnIpcDsplyRng2_D_Actl : 23|4@0+ (1,0) [0|15] "SED"  IPC

BO_ 1832 TesterPhysicalResIPC: 8 IPC
 SG_ TesterPhysicalResIPC : 7|64@0+ (1,0) [0|1.84467E+019] "unitless"  TSTR

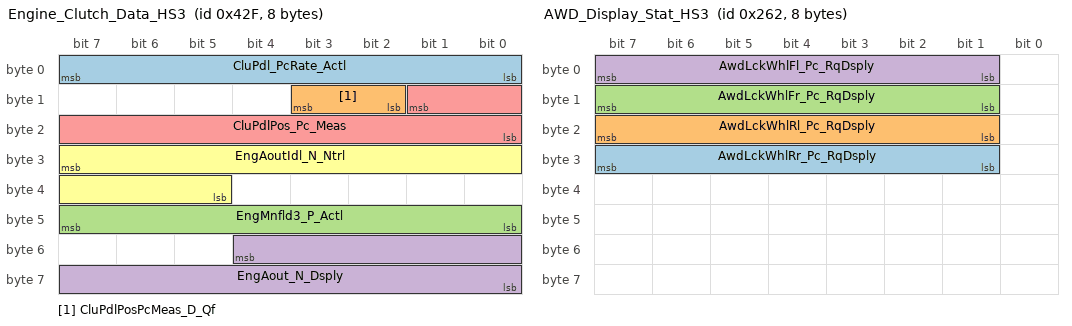
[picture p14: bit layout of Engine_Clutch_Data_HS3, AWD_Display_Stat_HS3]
BO_ 1071 Engine_Clutch_Data_HS3: 8 GWM
 SG_ CluPdl_PcRate_Actl : 7|8@0+ (0.04,-5) [-5|5.2] "%/ms"  IPC
 SG_ CluPdlPosPcMeas_D_Qf : 11|2@0+ (1,0) [0|3] "SED"  IPC
 SG_ EngMnfld3_P_Actl : 47|8@0+ (10,0) [0|2530] "milibar"  GENERIC
 SG_ EngAout_N_Dsply : 52|13@0+ (2,0) [0|16382] "rpm"  IPC
 SG_ CluPdlPos_Pc_Meas : 9|10@0+ (0.1,0) [0|102.3] "%"  IPC
 SG_ EngAoutIdl_N_Ntrl : 31|11@0+ (2,0) [0|4094] "rpm"  GENERIC

BO_ 848 RestraintsData: 8 IPC
 SG_ RILStat : 7|2@0+ (1,0) [0|3] "SED"  GWM

BO_ 610 AWD_Display_Stat_HS3: 8 GWM
 SG_ AwdLckWhlRr_Pc_RqDsply : 31|7@0+ (1,0) [0|127] "percent"  IPC
 SG_ AwdLckWhlRl_Pc_RqDsply : 23|7@0+ (1,0) [0|127] "percent"  IPC
 SG_ AwdLckWhlFr_Pc_RqDsply : 15|7@0+ (1,0) [0|127] "percent"  IPC
 SG_ AwdLckWhlFl_Pc_RqDsply : 7|7@0+ (1,0) [0|127] "percent"  IPC

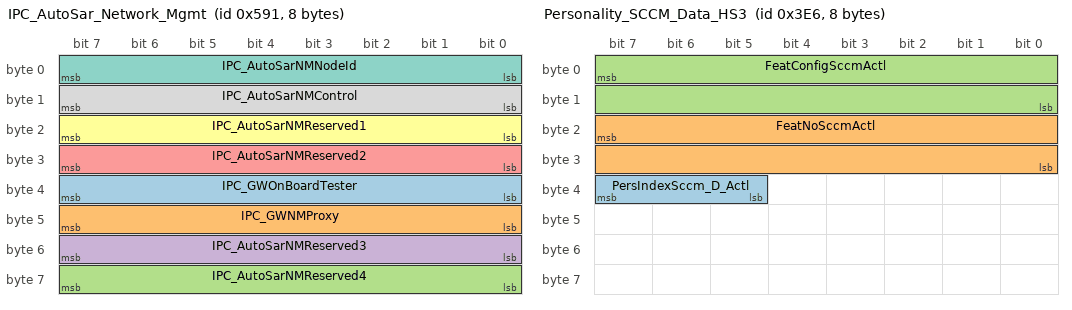
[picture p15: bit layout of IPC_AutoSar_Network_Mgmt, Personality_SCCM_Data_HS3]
BO_ 1425 IPC_AutoSar_Network_Mgmt: 8 IPC
 SG_ IPC_GWOnBoardTester : 39|8@0+ (1,0) [0|255] "unitless"  ACM,HUD_ADV,GENERIC,GWM
 SG_ IPC_GWNMProxy : 47|8@0+ (1,0) [0|255] "unitless"  ACM,HUD_ADV,GENERIC,GWM
 SG_ IPC_AutoSarNMReserved4 : 63|8@0+ (1,0) [0|255] "unitless"  ACM,HUD_ADV,GENERIC,GWM
 SG_ IPC_AutoSarNMReserved3 : 55|8@0+ (1,0) [0|255] "unitless"  ACM,HUD_ADV,GENERIC,GWM
 SG_ IPC_AutoSarNMReserved2 : 31|8@0+ (1,0) [0|255] "unitless"  ACM,HUD_ADV,GENERIC,GWM
 SG_ IPC_AutoSarNMReserved1 : 23|8@0+ (1,0) [0|255] "unitless"  ACM,HUD_ADV,GENERIC,GWM
 SG_ IPC_AutoSarNMNodeId : 7|8@0+ (1,0) [0|255] "unitless"  ACM,HUD_ADV,GENERIC,GWM
 SG_ IPC_AutoSarNMControl : 15|8@0+ (1,0) [0|255] "unitless"  ACM,HUD_ADV,GENERIC,GWM

BO_ 998 Personality_SCCM_Data_HS3: 8 GWM
 SG_ PersIndexSccm_D_Actl : 39|3@0+ (1,0) [0|7] "SED"  APIM,APIM_CISM,IPC
 SG_ FeatNoSccmActl : 23|16@0+ (1,0) [0|65535] "Number"  APIM,APIM_CISM,IPC
 SG_ FeatConfigSccmActl : 7|16@0+ (1,0) [0|65535] "Undefined"  APIM,APIM_CISM,IPC

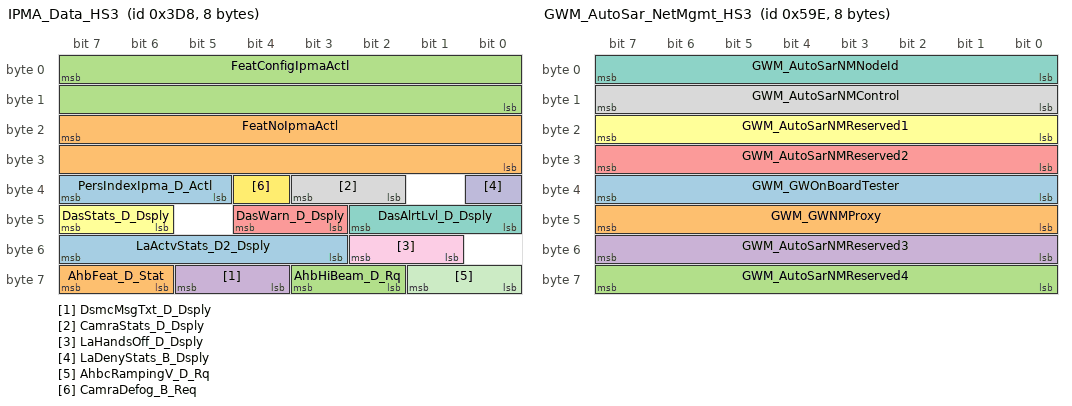
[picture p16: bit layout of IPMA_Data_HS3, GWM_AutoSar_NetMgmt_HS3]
BO_ 984 IPMA_Data_HS3: 8 GWM
 SG_ LaActvStats_D2_Dsply : 55|5@0+ (1,0) [0|31] "SED"  APIM,IPC,APIM_CISM
 SG_ AhbFeat_D_Stat : 63|2@0+ (1,0) [0|3] "SED"  IPC
 SG_ AhbHiBeam_D_Rq : 59|2@0+ (1,0) [0|3] "SED"  GENERIC
 SG_ DsmcMsgTxt_D_Dsply : 61|2@0+ (1,0) [0|3] "SED"  IPC
 SG_ DasWarn_D_Dsply : 44|2@0+ (1,0) [0|3] "SED"  IPC
 SG_ DasStats_D_Dsply : 47|2@0+ (1,0) [0|3] "SED"  IPC
 SG_ DasAlrtLvl_D_Dsply : 42|3@0+ (1,0) [0|7] "SED"  IPC
 SG_ CamraStats_D_Dsply : 35|2@0+ (1,0) [0|3] "SED"  IPC
 SG_ LaHandsOff_D_Dsply : 50|2@0+ (1,0) [0|3] "SED"  APIM,APIM_CISM,HUD_ADV,IPC
 SG_ LaDenyStats_B_Dsply : 32|1@0+ (1,0) [0|1] "SED"  IPC
 SG_ AhbcRampingV_D_Rq : 57|2@0+ (1,0) [0|3] "SED"  GENERIC
 SG_ CamraDefog_B_Req : 36|1@0+ (1,0) [0|1] "SED"  IPC
 SG_ PersIndexIpma_D_Actl : 39|3@0+ (1,0) [0|7] "SED"  APIM,APIM_CISM,HUD_ADV,IPC
 SG_ FeatNoIpmaActl : 23|16@0+ (1,0) [0|65535] "Number"  APIM,APIM_CISM,HUD_ADV,IPC
 SG_ FeatConfigIpmaActl : 7|16@0+ (1,0) [0|65535] "Undefined"  APIM,APIM_CISM,HUD_ADV,IPC

BO_ 1072 Cluster_Info1: 8 IPC
 SG_ PtDrvMde_D_Rq : 61|4@0+ (1,0) [0|15] "SED"  GWM
 SG_ DrvSlipCtlMde_D_Rq : 33|2@0+ (1,0) [0|3] "SED"  GWM
 SG_ EngIdlShutDown_B_RqDrv : 3|1@0+ (1,0) [0|1] "SED"  GWM
 SG_ DrvPerfMde_D_Rq : 49|2@0+ (1,0) [0|3] "SED"  GWM
 SG_ HsaMde_D_Rq : 54|2@0+ (1,0) [0|3] "SED"  GWM
 SG_ StopStrtDrvMde_D_RqMnu : 47|2@0+ (1,0) [0|3] "SED"  GWM
 SG_ NtrlTowMdeEnbl_B_RqDrv : 1|1@0+ (1,0) [0|1] "SED"  GWM
 SG_ LscmbbStat_B_Actl : 2|1@0+ (1,0) [0|1] "SED"  GWM
 SG_ BulbChkActv_B_Stat : 55|1@0+ (1,0) [0|1] "SED"  GWM
 SG_ ParkDetect_Stat : 52|1@0+ (1,0) [0|1] "SED"  HUD_ADV,GWM
 SG_ ReducedGuard_D_Rq : 51|2@0+ (1,0) [0|3] "SED"  GWM
 SG_ FrostWarn_D_Stat : 45|2@0+ (1,0) [0|3] "SED"  GWM
 SG_ TrlrBrkMde_D_Rq : 57|1@0+ (1,0) [0|1] "SED"  TRM_ITRM,GWM
 SG_ TRLR_SWAY_CONFIG_CMD : 56|1@0+ (1,0) [0|1] "SED"  GWM
 SG_ TRAILER_BRAKE_CONFIG : 37|1@0+ (1,0) [0|1] "SED"  TRM_ITRM,GWM
 SG_ Power_Liftgate_Mode_Cmd : 39|1@0+ (1,0) [0|1] "SED"  GWM
 SG_ AccEnbl_B_RqDrv : 35|1@0+ (1,0) [0|1] "SED"  HUD_ADV,GWM
 SG_ HaDsplyCpblty_B_Stat : 42|1@0+ (1,0) [0|1] "SED"  GWM
 SG_ OdometerMasterValue : 15|24@0+ (1,0) [0|16777214] "km"  APIM,APIM_CISM,GWM
 SG_ EngOilLife_B_RqReset : 43|1@0+ (1,0) [0|1] "SED"  GWM
 SG_ MetricActvTe_B_Actl : 38|1@0+ (1,0) [0|1] "SED"  GWM
 SG_ AccDeny_B_RqIpc : 7|1@0+ (1,0) [0|1] "SED"  HUD_ADV,GWM
 SG_ ePRNDL_MODE : 0|1@0+ (1,0) [0|1] "SED"  GWM
 SG_ PrkLckCtlEnbl_D_RqIpc : 63|2@0+ (1,0) [0|3] "SED"  GWM
 SG_ DrvSlipCtlMde_B_Rq2 : 34|1@0+ (1,0) [0|1] "SED"  GWM
 SG_ Fda_B_Stat : 36|1@0+ (1,0) [0|1] "SED"  GWM
 SG_ MetricActv_B_Actl : 6|1@0+ (1,0) [0|1] "SED"  APIM,APIM_CISM,HUD_ADV,GWM
 SG_ KeyTypeChngMykey_D_Rq : 41|2@0+ (1,0) [0|3] "SED"  GWM
 SG_ ManRgen_D_Rq : 5|2@0+ (1,0) [0|3] "SED"  GWM

BO_ 395 HeadUpDisplayReq: 8 IPC
 SG_ SelDrvMdeCnfm_D_Stat : 35|2@0+ (1,0) [0|3] "SED"  GWM
 SG_ HudShifPoint_N_Rq : 29|6@0+ (100,2000) [2000|8300] "rpm"  GWM
 SG_ HudMde_D_Rq : 38|3@0+ (1,0) [0|7] "SED"  GWM
 SG_ HudLedMde_D_Rq : 31|2@0+ (1,0) [0|3] "SED"  GWM
 SG_ HudLedIntns_Pc_Rq : 22|7@0+ (1,0) [0|127] "percent"  GWM
 SG_ HudLed9On_B_Rq : 15|1@0+ (1,0) [0|1] "SED"  GWM
 SG_ HudLed8On_B_Rq : 0|1@0+ (1,0) [0|1] "SED"  GWM
 SG_ HudLed7On_B_Rq : 1|1@0+ (1,0) [0|1] "SED"  GWM
 SG_ HudLed6On_B_Rq : 2|1@0+ (1,0) [0|1] "SED"  GWM
 SG_ HudLed5On_B_Rq : 3|1@0+ (1,0) [0|1] "SED"  GWM
 SG_ HudLed4On_B_Rq : 4|1@0+ (1,0) [0|1] "SED"  GWM
 SG_ HudLed3On_B_Rq : 5|1@0+ (1,0) [0|1] "SED"  GWM
 SG_ HudLed2On_B_Rq : 6|1@0+ (1,0) [0|1] "SED"  GWM
 SG_ HudLed1On_B_Rq : 7|1@0+ (1,0) [0|1] "SED"  GWM
 SG_ HudLed18On_B_Rq : 39|1@0+ (1,0) [0|1] "SED"  GWM
 SG_ HudLed17On_B_Rq : 23|1@0+ (1,0) [0|1] "SED"  GWM
 SG_ HudLed16On_B_Rq : 8|1@0+ (1,0) [0|1] "SED"  GWM
 SG_ HudLed15On_B_Rq : 9|1@0+ (1,0) [0|1] "SED"  GWM
 SG_ HudLed14On_B_Rq : 10|1@0+ (1,0) [0|1] "SED"  GWM
 SG_ HudLed13On_B_Rq : 11|1@0+ (1,0) [0|1] "SED"  GWM
 SG_ HudLed12On_B_Rq : 12|1@0+ (1,0) [0|1] "SED"  GWM
 SG_ HudLed11On_B_Rq : 13|1@0+ (1,0) [0|1] "SED"  GWM
 SG_ HudLed10On_B_Rq : 14|1@0+ (1,0) [0|1] "SED"  GWM

BO_ 1438 GWM_AutoSar_NetMgmt_HS3: 8 GWM
 SG_ GWM_GWOnBoardTester : 39|8@0+ (1,0) [0|255] "unitless"  APIM,APIM_CISM,DSP,TRM_ITRM,RACM_RCIM,WCM,IPC,ACM
 SG_ GWM_GWNMProxy : 47|8@0+ (1,0) [0|255] "unitless"  APIM,APIM_CISM,DSP,TRM_ITRM,RACM_RCIM,WCM,IPC,ACM
 SG_ GWM_AutoSarNMReserved4 : 63|8@0+ (1,0) [0|255] "unitless"  APIM,APIM_CISM,DSP,TRM_ITRM,RACM_RCIM,WCM,IPC,ACM
 SG_ GWM_AutoSarNMReserved3 : 55|8@0+ (1,0) [0|255] "unitless"  APIM,APIM_CISM,DSP,TRM_ITRM,RACM_RCIM,WCM,IPC,ACM
 SG_ GWM_AutoSarNMReserved2 : 31|8@0+ (1,0) [0|255] "unitless"  APIM,APIM_CISM,DSP,TRM_ITRM,RACM_RCIM,WCM,IPC,ACM
 SG_ GWM_AutoSarNMReserved1 : 23|8@0+ (1,0) [0|255] "unitless"  APIM,APIM_CISM,DSP,TRM_ITRM,RACM_RCIM,WCM,IPC,ACM
 SG_ GWM_AutoSarNMNodeId : 7|8@0+ (1,0) [0|255] "unitless"  APIM,APIM_CISM,DSP,TRM_ITRM,RACM_RCIM,WCM,IPC,ACM
 SG_ GWM_AutoSarNMControl : 15|8@0+ (1,0) [0|255] "unitless"  APIM,APIM_CISM,DSP,TRM_ITRM,RACM_RCIM,WCM,IPC,ACM

BO_ 76 RCMStatusMessage2_HS3: 8 GWM
 SG_ AirbagDrv_D_Actv : 63|2@0+ (1,0) [0|3] "SED" Vector__XXX
 SG_ RstrnImpact_No_Cs : 55|8@0+ (1,0) [0|255] "unitless" Vector__XXX
 SG_ RstrnPsngrOn_D_Stat : 39|4@0+ (1,0) [0|15] "SED"  APIM_CISM,IPC
 SG_ FirstRowBuckle_No_Cs : 47|8@0+ (1,0) [0|255] "unitless"  GENERIC
 SG_ RCMStatusMsg2_No_Cnt : 35|4@0+ (1,0) [0|15] "unitless"  GENERIC
 SG_ PsngrFmidDetct_D_Actl : 26|2@0+ (1,0) [0|3] "SED"  APIM,APIM_CISM,IPC
 SG_ FirstRowBuckleMid : 28|2@0+ (1,0) [0|3] "SED"  APIM,APIM_CISM,IPC
 SG_ ThirdRowBucklePsngr : 17|2@0+ (1,0) [0|3] "SED"  APIM,APIM_CISM,IPC
 SG_ ThirdRowBuckleMid : 19|2@0+ (1,0) [0|3] "SED"  APIM,APIM_CISM,IPC
 SG_ ThirdRowBuckleDriver : 21|2@0+ (1,0) [0|3] "SED"  APIM,APIM_CISM,IPC
 SG_ SecondRowBucklePsngr : 23|2@0+ (1,0) [0|3] "SED"  APIM,APIM_CISM,IPC
 SG_ SecondRowBuckleMid : 9|2@0+ (1,0) [0|3] "SED"  APIM,APIM_CISM,IPC
 SG_ SecondRowBuckleDriver : 11|2@0+ (1,0) [0|3] "SED"  APIM,APIM_CISM,IPC
 SG_ FirstRowBuckleDriver : 15|2@0+ (1,0) [0|3] "SED"  APIM,APIM_CISM,IPC
 SG_ RILReq : 7|2@0+ (1,0) [0|3] "SED"  APIM_CISM,IPC
 SG_ FirstRowBucklePsngr : 13|2@0+ (1,0) [0|3] "SED"  APIM,APIM_CISM,IPC
 SG_ RstrnImpactEvntStatus : 3|3@0+ (1,0) [0|7] "SED"  APIM,APIM_CISM,HUD_ADV
 SG_ PsngrFrntDetct_D_Actl : 5|2@0+ (1,0) [0|3] "SED"  APIM,APIM_CISM,IPC
 SG_ PassRstrnInd_Req : 31|2@0+ (1,0) [0|3] "SED"  FCIMB,GENERIC
 SG_ EDRTriggerEvntSync : 29|1@0+ (1,0) [0|1] "SED"  APIM,APIM_CISM,IPC

BO_ 1034 GGCC_Config_Mgmt_ID_1_HS3: 8 GWM
 SG_ VehicleGGCCData : 7|64@0+ (1,0) [0|1.84467E+019] "mixed"  APIM,APIM_CISM,TRM_ITRM,HUD_ADV,ACM,IPC

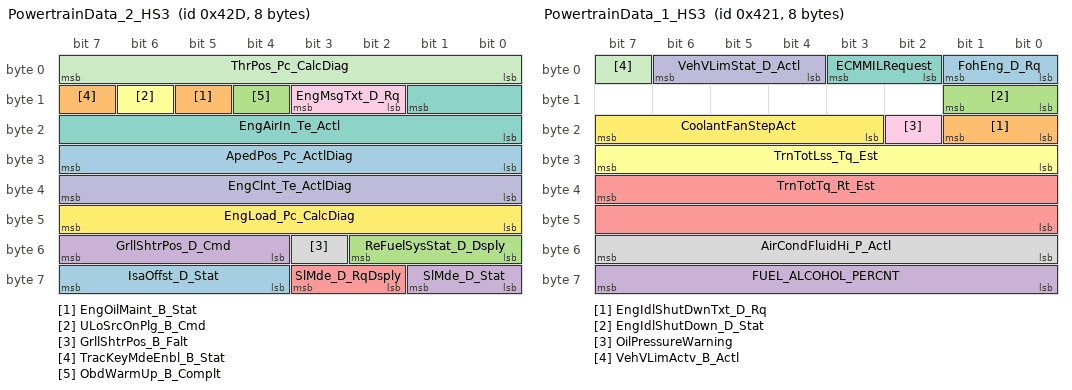
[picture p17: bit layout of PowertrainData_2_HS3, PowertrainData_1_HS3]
BO_ 1069 PowertrainData_2_HS3: 8 GWM
 SG_ IsaOffst_D_Stat : 63|4@0+ (1,0) [0|15] "SED"  IPC
 SG_ EngOilMaint_B_Stat : 13|1@0+ (1,0) [0|1] "SED"  GENERIC
 SG_ ReFuelSysStat_D_Dsply : 50|3@0+ (1,0) [0|7] "SED"  APIM_CISM,IPC
 SG_ SlMde_D_Stat : 57|2@0+ (1,0) [0|3] "SED"  HUD_ADV,IPC
 SG_ SlMde_D_RqDsply : 59|2@0+ (1,0) [0|3] "SED"  APIM,APIM_CISM,HUD_ADV,IPC
 SG_ ULoSrcOnPlg_B_Cmd : 14|1@0+ (1,0) [0|1] "SED"  IPC
 SG_ EngAirIn_Te_Actl : 9|10@0+ (0.25,-128) [-128|127.25] "degC"  IPC
 SG_ GrllShtrPos_B_Falt : 51|1@0+ (1,0) [0|1] "SED"  IPC
 SG_ EngMsgTxt_D_Rq : 11|2@0+ (1,0) [0|3] "SED"  IPC
 SG_ EngClnt_Te_ActlDiag : 39|8@0+ (1,-40) [-40|215] "degC"  IPC
 SG_ ThrPos_Pc_CalcDiag : 7|8@0+ (0.392157,0) [0|100.000035] "%"  IPC
 SG_ EngLoad_Pc_CalcDiag : 47|8@0+ (0.392157,0) [0|100.000035] "%"  IPC
 SG_ ApedPos_Pc_ActlDiag : 31|8@0+ (0.392157,0) [0|100.000035] "%"  IPC
 SG_ TracKeyMdeEnbl_B_Stat : 15|1@0+ (1,0) [0|1] "SED"  IPC
 SG_ ObdWarmUp_B_Complt : 12|1@0+ (1,0) [0|1] "SED" Vector__XXX
 SG_ GrllShtrPos_D_Cmd : 55|4@0+ (1,0) [0|15] "SED"  IPC

BO_ 1057 PowertrainData_1_HS3: 8 GWM
 SG_ FohEng_D_Rq : 1|2@0+ (1,0) [0|3] "SED"  IPC
 SG_ EngIdlShutDwnTxt_D_Rq : 17|2@0+ (1,0) [0|3] "SED"  IPC
 SG_ EngIdlShutDown_D_Stat : 9|2@0+ (1,0) [0|3] "SED"  IPC
 SG_ FUEL_ALCOHOL_PERCNT : 63|8@0+ (0.393700787,0) [0|99.999899898] "percent"  IPC
 SG_ TrnTotTq_Rt_Est : 39|16@0+ (0.001,0) [0|65.533] "unitless"  IPC
 SG_ TrnTotLss_Tq_Est : 31|8@0+ (0.5,0) [0|126.5] "Nm"  IPC
 SG_ ECMMILRequest : 3|2@0+ (1,0) [0|3] "SED"  IPC
 SG_ AirCondFluidHi_P_Actl : 55|8@0+ (0.125,0) [0|31.625] "bar"  IPC
 SG_ OilPressureWarning : 18|1@0+ (1,0) [0|1] "SED"  IPC
 SG_ VehVLimStat_D_Actl : 6|3@0+ (1,0) [0|7] "SED"  IPC
 SG_ VehVLimActv_B_Actl : 7|1@0+ (1,0) [0|1] "SED"  IPC
 SG_ CoolantFanStepAct : 23|5@0+ (1,0) [0|31] "Steps"  IPC

BO_TX_BU_ 401 : APIM_CISM,APIM;
BO_TX_BU_ 261 : APIM,APIM_CISM,ACM;
BO_TX_BU_ 753 : APIM_CISM,APIM;
BO_TX_BU_ 1000 : APIM_CISM,APIM,ACM;
BO_TX_BU_ 754 : APIM_CISM,ACM;
BO_TX_BU_ 729 : APIM_CISM,ACM,APIM;
BO_TX_BU_ 726 : APIM_CISM,ACM,APIM;
CM_ BO_ 549 "Method IPC _Infotainment";
CM_ SG_ 549 BeltminderAudioMute "Object.MyKey.BeltMinderAudioMute.St";
CM_ SG_ 549 Power_Up_Chime_Modules "Object.AlertMethod.IPC _Infotainment";
CM_ SG_ 549 Chime_Source "Object.AlertMethod.IPC_infotainment";
CM_ SG_ 765 Mc_VehUntTrpCoUsrSel_St "Object.VehicleSettings.Disp_Miles_Kilometers.Rq";
CM_ SG_ 765 Mc_VehUnitTempUsrSel_St "Object.VehicleSettings.Disp_Temperature.Rq";
CM_ SG_ 765 Mc_VehDayNightUsrSel_St "Object.BodyInterface.Settings.VehicleDayNightUserSelection
Object.BodyInterface.Status.AMDayNightSensitivity";
CM_ SG_ 765 Mc_VehTimeFrmtUsrSel_St "Object.BodyInterface.Settings.VehicleTimeFormatUserSelection";
CM_ SG_ 765 Mc_VehThemeUsrSel_St "Object.BodyInterface.Settings.VehicleThemeUserSelection";
CM_ SG_ 765 Mc_VehLangUsrSel_St "Object.BodyInterface.Settings.VehicleLanguageUserSelection
Object Vehicle Settings.Disp_LangSel
";
CM_ SG_ 508 Mc_DB1GetInfStartInd_Rq "Object Media Player iPod.GetMDBInfo.MDBStartItemInd
";
CM_ SG_ 508 Mc_DB1GtInfNbrOfItms_Rq "Object Media Player iPod.GetMDBInfo.MDBNbrOfItems
";
CM_ SG_ 508 Mc_DB1GetInfSetConf_Rq "Object Media Player iPod.GetMDBInfo.MDBSetFilterConf
";
CM_ SG_ 508 Mc_DB1GetInfSetFilt3_Rq "Object Media Player iPod.GetMDBInfo.MDBSetFilter3
";
CM_ SG_ 508 Mc_DB1GetInfSetFilt2_Rq "Object Media Player iPod.GetMDBInfo.MDBSetFilter2
";
CM_ SG_ 508 Mc_DB1GetInfSetFilt1_Rq "Object Media Player iPod.GetMDBInfo.MDBSetFilter1 ";
CM_ SG_ 507 Mc_DB1SetTrkItmIndex_Rq "Object Media Player iPod.MDBSetTrack.MDBItemIndex
";
CM_ SG_ 507 Mc_DB1SetTrkSetConf_Rq "Object Media Player iPod.MDBSetTrack.MDBSetFilterConf";
CM_ SG_ 507 Mc_DB1SetTrkSetFilt3_Rq "Object Media Player iPod.MDBSetTrack.MDBSetFilter3";
CM_ SG_ 507 Mc_DB1SetTrkSetFilt2_Rq "Object Media Player iPod.MDBSetTrack.MDBSetFilter2";
CM_ SG_ 507 Mc_DB1SetTrkSetFilt1_Rq "Object Media Player iPod.MDBSetTrack.MDBSetFilter1";
CM_ SG_ 506 Mc_AudioSourceSel3_Rq "Object Media Player BTAudio.GetDetailedMPInfo.AudioSource
Object Media Player BTAudio.PlayFirstTrackInFolder.AudioSource
Object Media Player USB.GetDetailedMPInfo.AudioSource
Object Media Player USB.PlayFirstTrackInFolder.AudioSource";
CM_ SG_ 506 Mc_PlayFrstTrInFldr_Rq "Object Media Player BTAudio.PlayFirstTrackInFolder.FolderNumber
Object Media Player USB.PlayFirstTrackinFolder.FolderNumber

$FFFF: Inactive";
CM_ SG_ 506 Mc_ItemIndex_Rq "Object Media Player BTAudio.GetDetailedMPInfo.ItemIndex
Object Media Player USB.GetDetailedMPInfo.ItemIndex";
CM_ SG_ 506 Mc_FolderNumber3_Rq "Object Media Player BTAudio.GetDetailedMPInfo.FolderNumber
Object Media Player USB.GetDetailedMPInfo.FolderNumber";
CM_ SG_ 505 Mc_AudioSourceSel2_Rq "Object Media Player BTAudio.GetMPInfo.AudioSouce
Object Media Player USB.GetMPInfo.AudioSouce
Object Media Player SDCard.GetMPInfo.AudioSouce";
CM_ SG_ 505 Mc_StartItemIndexRq "Object Media Player BTAudio.GetMPInfo.StartingItemIndex
Object Media Player USB.GetMPInfo.StartingItemIndex
Object Media Player SDCard.GetMPInfo.StartingItemIndex

$FFFF: Inactive";
CM_ SG_ 505 Mc_NbrOfItems2_Rq "Object Media Player BTAudio.GetMPInfo.NbrOfItems
Object Media Player USB.GetMPInfo.NbrOfItems
Object Media Player SDCard.GetMPInfo.NbrOfItems";
CM_ SG_ 505 Mc_ItemNameLength2_Rq "Object Media Player BTAudio.GetMPInfo.ItemNameLength
Object Media Player USB.GetMPInfo.ItemNameLength
Object Media Player SDCard.GetMPInfo.ItemNameLength";
CM_ SG_ 505 Mc_CutItem2_Rq "Object Media Player BTAudio.GetMPInfo.CutItemName
Object Media Player USB.GetMPInfo.CutItemName
Object Media Player SDCard.GetMPInfo.CutItemName";
CM_ SG_ 505 Mc_FolderNumber2_Rq "Object Media Player BTAudio.GetMPInfo.FolderNumber 
Object Media Player USB.GetMPInfo.FolderNumber
Object Media Player SDCard.GetMPInfo.FolderNumber

$FFFF: Inactive";
CM_ SG_ 505 Mc_FolderContent_Rq "Object Media Player USB.GetMPInfo.FolderContent
Object Media Player SDCard.GetMPInfo.FolderContent

Note: Value table entries were truncated from:
$0: RequestContentFromParameterFolderNumber
$1: RequestContentFromParentFolderOfParameterFolderNumber";
CM_ SG_ 403 Mc_RepeatGuidance_Rq "Object.NavigationRepeater.Guidance_Repeat.Rq.RepeatGuidance";
CM_ SG_ 403 Mc_CancelRoute_Rq "Object.NavigationRepater.CancelRoute.Rq.CancelRoute";
CM_ SG_ 403 Mc_CancelCurrWaypt_Rq "Object.NavigationRepeater.CancelCurrentWayPoint.Rq.Cancelwaypoint";
CM_ SG_ 403 Mc_TextMessage_Rq "Object. BTPhoneClient.TextMessage.Rq";
CM_ SG_ 403 Mc_BTInCallOptions_Rq "Object.BTPhoneClient.BTInCallOptions.Rq.SingleParam";
CM_ SG_ 403 Mc_PhMicrophoneMute_Rq "Object Blueetoth Phone.PhMicrophoneMute";
CM_ SG_ 403 Mc_LangSel_Rq "Object.VehicleSettings.Disp_LangSel.Rq.Language";
CM_ BO_ 401 "APIM Tx";
CM_ SG_ 401 Bezel_Beeps_Rq "Vehicle Settings";
CM_ SG_ 401 Disp_VehUntTripCoUsrSel "Obect.VehicleSettings.Disp_Miles_Kilometers.Rq.Mode";
CM_ SG_ 401 Disp_VehUnitTempUsrSel "Obect.VehicleSettings.Disp_Temperature.Rq.Mode";
CM_ SG_ 401 Disp_LangSel_Rq "Object.VehicleSettings.Disp_LangSel.Rq.Language";
CM_ SG_ 401 Disp_LangSel2_Rq "Reference GSDB for encoding: 009522/B;2-ZZ_LangSel";
CM_ SG_ 405 LBC1_StartItemInd "Object. ListBrowser.ItemInf.Rq.StartItemInd
0x0000:Inactive
0x0001:1
0xFFFE:65634
0xFFFF:Reserved";
CM_ SG_ 405 LBC1_SetListServ "Object. ListBrowser.ItemInf.Rq.SetListServ
0x00:Inactive
0x01:ServerID_1
0xFF:ALL";
CM_ SG_ 405 LBC1_Opcode "Object. ListBrowser.ItemInf.Rq.Opcode";
CM_ SG_ 405 LBC1_NbrOfItems "Object. ListBrowser.ItemInf.Rq.NbrOfItems
0x00:Inactive
0x01:1Item
0x3F:63Items";
CM_ SG_ 405 LBC1_ItemIndex "Object. ListBrowser.ItemInf.Rq.ItemIndex
0x0000:BrowseActiveListID
0x0001:EntryIndex_1
0xFFFF:ParentOfActiveListID";
CM_ SG_ 405 LBC1_ActiveListID "Object. ListBrowser.ItemInf.Rq.ActiveListID
0x0000:Root
0xFFFF:Reserved";
CM_ BO_ 756 "IPC_Chime2";
CM_ SG_ 756 Off_Time_Btwn_Chime2 "Object.AlertMethod.IPC_Chime
0x0 Inactive
0x1 Continuously (repeat continuously) 
0x2 5 msec
0x3 10 msec
0x4 15 msec
0x5 20 msec
0x6 40 msec
0x7 60 msec (increment is 20 msec steps until 800 msec)
cont....Refer SPSS for rest of encodings";
CM_ SG_ 756 Chime_Vol_Level2 "Object.AlertMethod. IPC_Chime
0x0 Inactive (no change to stored chime volume - 100% of stored chime volume)
0x1 99% (of stored chime volume)
....
0x63 1% (of stored chime volume)
0x64 Reserved";
CM_ SG_ 756 Chime_Time_Criticality2 "Object.AlertMethod. IPC_Chime";
CM_ SG_ 756 Chime_Occurence2 "Object.AlertMethod. IPC_Chime";
CM_ SG_ 756 Chime_Directionality2 "Object.AlertMethod. IPC_Chime";
CM_ SG_ 756 Chime2 "Object.AlertMethod. IPC_Chime
0x0 No_Chime  (note: if >No Chime< is selected then ignore other signals in this message)
0x1 Chime_1
0x2 Chime_2
0x3 Chime_3
cont.
0x3F Chime_63

";
CM_ BO_ 544 "Method IPC_Chime";
CM_ SG_ 544 Chime_Occurence "Object.AlertMethod. IPC_Chime";
CM_ SG_ 544 Off_Time_Btwn_Chime "Object.AlertMethod.IPC_Chime
0x0 Inactive
0x1 Continuously (repeat continuously) 
0x2 5 msec
0x3 10 msec
0x4 15 msec
0x5 20 msec
0x6 40 msec
0x7 60 msec (increment is 20 msec steps until 800 msec)
cont....Refer SPSS for rest of the encodings.
";
CM_ SG_ 544 Chime_Time_Criticality "Object.AlertMethod. IPC_Chime";
CM_ SG_ 544 Chime_Directionality "Object.AlertMethod. IPC_Chime";
CM_ SG_ 544 Chime_Vol_Level "Object.AlertMethod. IPC_Chime
0x0 Inactive (no change to stored chime volume - 100% of stored chime volume)
0x1 99% (of stored chime volume)
....
0x63 1% (of stored chime volume)
0x64 Reserved";
CM_ SG_ 544 Chime "Object.AlertMethod. IPC_Chime
0x0 No_Chime  (note: if >No Chime< is selected then ignore other signals in this message)
0x1 Chime_1
0x2 Chime_2
0x3 Chime_3
cont.
0x3F Chime_63
";
CM_ SG_ 291 LangUpdate_Rsp "Object. LanguageUpdate.Rsp";
CM_ SG_ 400 Mc_SetCurrntStatFreq_Rq "Object Tuner.SetCurrentStat.Request.Frequency

AM: Freq = 153+ Offset kHz.
Offset 0..1557

FM: Freq = 76+ Offset*0.05 MHz. Offset 0..640
Selected tuned band determine frequency (kHz or MHz).";
CM_ SG_ 400 Mc_SetCurrStatMCCh_Rq "Object Tuner.SetCurrentStation.MCChannel";
CM_ SG_ 400 Mc_SetCurrentStatOp_Rq "Object Tuner.SetCurrentStat.Request.Operation";
CM_ SG_ 400 Mc_PerTUStartIndex2_Rq "Object Personalization. DAB.GetTUPresetInfo.StartIndex2

$1-$FF: Preset 1 to 255";
CM_ SG_ 400 Mc_PerTUPresetArea_Rq "Object Personalization.DAB.GetTUPresetInfo.PresetArea

$5: Get AMAST (MW) Preset Data
$6: Get AM (LW) Preset Data";
CM_ SG_ 400 Mc_PerTUNbrOfPresets_Rq "Object Personalization. DAB.GetTUPresetInfo.NumberOfPresets

$1-$1E: Preset 1 to 30";
CM_ SG_ 647 HEC_BTIncomingCall_Rq "Object Bluetooth Phone.BTIncomingCall";
CM_ SG_ 647 HEC_BTEndTelService_Rq "Object Bluetooth Phone.BTEndTelService";
CM_ SG_ 359 TrnAin_Tq_Actl "Signal not transmitted on HEV variances.";
CM_ SG_ 359 PlgActvArb_B_Actl "Only supported on PHEV programs.  PlgActvArb_B_Actl HPCM will Tx on Powersplit PHEV’s,  On MHT PHEVs the PCM_HEV will Tx and HPCM will Rx. 
";
CM_ SG_ 359 TrnAinTq_D_Qf "Signal not transmitted on HEV variances.";
CM_ SG_ 1091 PoliceAux4Lamp_B_Rq2 "Signal not transmitted on programs that do not have AWD.";
CM_ SG_ 1091 PoliceAux3Lamp_B_Rq2 "Signal not transmitted on programs that do not have AWD.";
CM_ SG_ 1091 PoliceAux2Lamp_B_Rq2 "Signal not transmitted on programs that do not have AWD.";
CM_ SG_ 1091 PoliceAux1Lamp_B_Rq2 "Signal not transmitted on programs that do not have AWD.";
CM_ SG_ 261 OffPeakTimeSetType_Rq "Object:OffPeakTimeSet_Rq";
CM_ BO_ 753 "APIM Tx";
CM_ SG_ 1000 AHU_Bezel_Diag_St "Object:BezelDiagnostics.AHU_Bezel_Diag.St";
CM_ SG_ 1000 AHU_Shaker_St "Object:AudioSettings.AHU_Shaker ";
CM_ SG_ 1000 ACM_BeltminderAudioSt "Method: BeltminderAudioIsMuted";
CM_ SG_ 1000 MyKeyVolumeLimitUp "Method MykeyvolumeIsLimited:VolumeUpdate";
CM_ SG_ 1000 MyKeyVolumeLimitMode "Method MykeyvolumeIsLimited: Mode";
CM_ SG_ 584 AUDIO_RDISP2_WORD_Rx "MM ISO 15765-2 Message Catalogue RDISP2 - AUDIO";
CM_ SG_ 754 ACU_ActChimeTypeDat_St "Object BodyInterface.StdChimeIF.ActiveChime.TypeData.St

0x00: NoChime

ChimeType==Sine: 
Range: 0x01-0x3FF (1Hz - 16383Hz)

ChimeType==Sample: 
Range: 0x01-0x40  (Sample 1 - Sample 63)
Range: 0x41-0x3FFF (Reserved)";
CM_ SG_ 754 ACU_ActChimeType_St "Object BodyInterface.StdChimeIF.ActiveChime.Type.St";
CM_ SG_ 729 ACU_VoiceFBVolume_Up "Object Audio.VoiceFBVolume_UP
Object.AHU_VR_Vol_Updated
Indicate user value recalls if the value is set to lower/upper border ";
CM_ SG_ 729 ACU_VoiceFBVolume_St "Object Audio.VoiceFBVolume
Method AHU_VR_Vol_Level_St()

Refer method table in SPSS for details
0x0 No Volume
0x1 Vol_Step1
0x2 Vol_Step2
0x3 Vol_Step3
Cont.
0x1E Vol_Step30";
CM_ SG_ 729 ACU_Treble_St "Object Audio.Treble

Treble.St



Level -7..0..7


Method: AHU_Treble";
CM_ SG_ 729 ACU_TAVolume_Up "Object Audio.TAVolume_UP
Indicate user value recalls if the value is set to lower/upper border 
Method AHU_TA_Vol_Updated ";
CM_ SG_ 729 ACU_TAVolume_St "Object Audio.TAVolume
Method AHU_TA_Vol_Level.St 

Refer method table in SPSS for details
0x0 No Volume
0x1 Vol_Step1
0x2 Vol_Step2
0x3 Vol_Step3
Cont.
0x1E Vol_Step30";
CM_ SG_ 729 ACU_Reg_St "Object Tuner.REG";
CM_ SG_ 729 ACU_PhoneVolume_Up "Object Audio.PhoneVolume_UP

Object.VolumeControl.AHU_Phone_Vol_Updated";
CM_ SG_ 729 ACU_PhoneVolume_St "Object Audio.PhoneVolume
AHU_Phone_Vol_Level.St
0x0 No Volume
0x1 Vol_Step1
0x2 Vol_Step2
0x3 Vol_Step3
Cont.
0x1E Vol_Step30";
CM_ SG_ 729 ACU_NavCmdVolume_Up "Object Audio.NavCmdVolume_UP. AHU_Prompt_Vol_Updated. ";
CM_ SG_ 729 ACU_NavCmdVolume_St "Object Audio.NavCmdVolume. AHU_Prompt_Vol_Level.St()

Refer method table in SPSS for details
0x0 No Volume
0x1 Vol_Step1
0x2 Vol_Step2
0x3 Vol_Step3
Cont.
0x1E Vol_Step30";
CM_ SG_ 729 ACU_Fader_St "Object Audio.Fader



Fade.St

Level -7..0..7


Method: AHU_Fade";
CM_ SG_ 729 ACU_DSPProgram_St "Object Audio.DSPProgram
";
CM_ SG_ 729 ACU_DSP_St "Object. Audio.DSP
Object: AudioSettings.AHU_Occupancy_Mode.St";
CM_ SG_ 729 ACU_Bass_St "Object Audio.Bass



Bass.St

Level -7..0..7


Method: AHU_Bass";
CM_ SG_ 729 ACU_Balance_St "Object Audio.Balance

Balance.St



Level -7..0..7


Method: AHU_Balance";
CM_ SG_ 729 ACU_AVC_St "Object Audio.AVC
Off, Level 1 .. Level 7

Method: AHU_Speed_Comp_Vol.St";
CM_ SG_ 727 ACU_LoadEjectMode_St "Object Indash CD Changer.LoadEject(Action)";
CM_ SG_ 727 ACU_LoadEjectDisc_St "Object Indash CD Changer.LoadEject(Disc Number)";
CM_ SG_ 726 ACU_SelectedPTYCodes_St "Object Tuner.SelectedPTYCodes

Bit 0: 0: invalid, 1: valid
Bit 1: 0: PTY code 2 not selected; 1: PTY code 2 selected
...
Bit 28: 0: PTY code 29 not selected; 1: PTY code 29 selected";
CM_ SG_ 726 ACU_TAMode_St "Object Tuner.TAMode";
CM_ SG_ 726 ACU_NEWSMode_St "Object Tuner.NEWSMode";
CM_ SG_ 726 ACU_AFJump_St "Object Tuner.AFJump.St";
CM_ SG_ 369 TrnIpcDsplMdeDActl_No_Cnt "Applies to Drag Mode on S550 Only.";
CM_ SG_ 369 TrnIpcDsplMdeDActl_No_Cs "Applies to Drag Mode on S550 Only.";
CM_ SG_ 1071 CluPdl_PcRate_Actl "Signal not transmitted on HEV variants.";
CM_ SG_ 1071 CluPdlPosPcMeas_D_Qf "Signal not transmitted on HEV variants.";
CM_ SG_ 1071 CluPdlPos_Pc_Meas "Signal not transmitted on HEV variants.";
CM_ SG_ 1071 EngAoutIdl_N_Ntrl "Signal not transmitted on HEV variants and diesel.";
CM_ SG_ 1072 MetricActv_B_Actl "0 =Inactive(English), 1=Active(Metric)";
CM_ SG_ 1034 VehicleGGCCData "RCMGenSigTimeout=6000";
CM_ SG_ 1069 SlMde_D_Stat "IPC and HUD_ADV Receve from HS3 FGW 0x42D, not HS3 0x38A, MSG DCR 506.";
CM_ SG_ 1069 SlMde_D_RqDsply "IPC and HUD_ADV Receve from HS3 FGW 0x42D, not HS3 0x38A, MSG DCR 506.";
CM_ SG_ 1069 EngMsgTxt_D_Rq "Signal not transmitted on diesel variants.";
CM_ SG_ 1069 EngClnt_Te_ActlDiag "Signal not transmitted on gas variants.";
CM_ SG_ 1069 EngLoad_Pc_CalcDiag "Signal not transmitted on gas variants.";
CM_ SG_ 1069 ApedPos_Pc_ActlDiag "Signal not transmitted on gas variants.";
CM_ SG_ 1069 ObdWarmUp_B_Complt "Signal not transmitted on gas and diesel variants.";
CM_ SG_ 1057 FohEng_D_Rq "Signal not transmitted on vehicles that do not have the fuel operated heater feature.";
CM_ SG_ 1057 EngIdlShutDown_D_Stat "Signal not transmitted on diesel variants.";
CM_ SG_ 1057 FUEL_ALCOHOL_PERCNT "signal not transmitted on diesel and HEV variants.";
CM_ SG_ 1057 TrnTotTq_Rt_Est "Signal not transmitted on gas and HEV variants.";
CM_ SG_ 1057 TrnTotLss_Tq_Est "Signal not transmitted on gas and HEV variants.";
CM_ SG_ 1057 VehVLimStat_D_Actl "Signal not transmitted on gas and HEV variants.";
CM_ SG_ 1057 VehVLimActv_B_Actl "Signal not transmitted on gas and HEV variants.";
BA_DEF_ BO_  "FrameRouting" STRING ;
BA_DEF_ BO_  "NetworkInitialization" ENUM  "No","Yes";
BA_DEF_ BO_  "GenMsgStartDelayTime" INT 0 10000;
BA_DEF_ BO_  "GenMsgNrOfRepetition" INT 0 100;
BA_DEF_ BO_  "GenMsgDelayTime" INT 0 1000;
BA_DEF_ BO_  "GenMsgCycleTime" INT 0 100000;
BA_DEF_ BO_  "GenMsgSendType" ENUM  "FixedPeriodic","Event","EnabledPeriodic","NotUsed","NotUsed","EventPeriodic","NotUsed","NotUsed","NoMsgSendType";
BA_DEF_ SG_  "U_V710_MY2023_Tx" ENUM  "No","Yes";
BA_DEF_ SG_  "U_P708_MY2023_Tx" ENUM  "No","Yes";
BA_DEF_ SG_  "U_V713AV_MY2022_Tx" ENUM  "No","Yes";
BA_DEF_ SG_  "U_V713N_MY2022_Tx" ENUM  "No","Yes";
BA_DEF_ SG_  "ECGUsedTxSignal" ENUM  "No","Yes";
BA_DEF_ SG_  "U_V710_MY2023_Rx" ENUM  "No","Yes";
BA_DEF_ SG_  "U_P708_MY2023_Rx" ENUM  "No","Yes";
BA_DEF_ SG_  "U_V713AV_MY2022_Rx" ENUM  "No","Yes";
BA_DEF_ SG_  "U_V713N_MY2022_Rx" ENUM  "No","Yes";
BA_DEF_ SG_  "ECGUsedRxSignal" ENUM  "No","Yes";
BA_DEF_ SG_  "UsedOnPgmDBC" ENUM  "No","Yes";
BA_DEF_ SG_  "ContentDependant" ENUM  "No","Yes";
BA_DEF_ SG_  "GenSigStartValue" HEX 0 268435455;
BA_DEF_ SG_  "MetaData" ENUM  "No","Yes";
BA_DEF_ SG_  "WakeupSignal" ENUM  "No","Yes";
BA_DEF_ SG_  "GenSigInactiveValue" INT 0 100000;
BA_DEF_ SG_  "GenSigSendType" ENUM  "Cyclic","OnWrite","vector_leerstring","OnChange","vector_leerstring","IfActive","vector_leerstring","NoSigSendType";
BA_DEF_ BO_  "TpTxIndex" INT 0 536870911;
BA_DEF_ BO_  "OvtpPushApplication" ENUM  "FALSE","TRUE";
BA_DEF_ BO_  "SCP_FreshnessValueLength" INT 0 512;
BA_DEF_ BO_  "SCP_DataId" INT 0 17663;
BA_DEF_ BO_  "SCP_FreshnessValueTxLength" INT 0 512;
BA_DEF_ BO_  "SCP_AuthInfoTxLength" INT 0 512;
BA_DEF_ BO_  "SC_Message" ENUM  "No","Yes";
BA_DEF_ BO_  "GenMsgRoutingTimeoutTime" INT 0 5000;
BA_DEF_ BO_  "MessageGateway" ENUM  "No","Yes";
BA_DEF_ BO_  "NmAsrMessage" ENUM  "No","Yes";
BA_DEF_ BO_  "DiagState" ENUM  "No","Yes";
BA_DEF_ BO_  "DiagRequest" ENUM  "No","Yes";
BA_DEF_ BO_  "DiagResponse" ENUM  "No","Yes";
BA_DEF_ BO_  "GenMsgILSupport" ENUM  "No","Yes";
BA_DEF_DEF_  "FrameRouting" "";
BA_DEF_DEF_  "NetworkInitialization" "Yes";
BA_DEF_DEF_  "GenMsgStartDelayTime" 0;
BA_DEF_DEF_  "GenMsgNrOfRepetition" 1;
BA_DEF_DEF_  "GenMsgDelayTime" 20;
BA_DEF_DEF_  "GenMsgCycleTime" 0;
BA_DEF_DEF_  "GenMsgSendType" "NoMsgSendType";
BA_DEF_DEF_  "U_V710_MY2023_Tx" "No";
BA_DEF_DEF_  "U_P708_MY2023_Tx" "No";
BA_DEF_DEF_  "U_V713AV_MY2022_Tx" "No";
BA_DEF_DEF_  "U_V713N_MY2022_Tx" "No";
BA_DEF_DEF_  "ECGUsedTxSignal" "No";
BA_DEF_DEF_  "U_V710_MY2023_Rx" "No";
BA_DEF_DEF_  "U_P708_MY2023_Rx" "No";
BA_DEF_DEF_  "U_V713AV_MY2022_Rx" "No";
BA_DEF_DEF_  "U_V713N_MY2022_Rx" "No";
BA_DEF_DEF_  "ECGUsedRxSignal" "No";
BA_DEF_DEF_  "UsedOnPgmDBC" "Yes";
BA_DEF_DEF_  "ContentDependant" "No";
BA_DEF_DEF_  "GenSigStartValue" 0;
BA_DEF_DEF_  "MetaData" "No";
BA_DEF_DEF_  "WakeupSignal" "No";
BA_DEF_DEF_  "GenSigInactiveValue" 0;
BA_DEF_DEF_  "GenSigSendType" "NoSigSendType";
BA_DEF_DEF_  "TpTxIndex" 0;
BA_DEF_DEF_  "OvtpPushApplication" "FALSE";
BA_DEF_DEF_  "SCP_FreshnessValueLength" 64;
BA_DEF_DEF_  "SCP_DataId" 0;
BA_DEF_DEF_  "SCP_FreshnessValueTxLength" 11;
BA_DEF_DEF_  "SCP_AuthInfoTxLength" 53;
BA_DEF_DEF_  "SC_Message" "No";
BA_DEF_DEF_  "GenMsgRoutingTimeoutTime" 0;
BA_DEF_DEF_  "MessageGateway" "No";
BA_DEF_DEF_  "NmAsrMessage" "No";
BA_DEF_DEF_  "DiagState" "No";
BA_DEF_DEF_  "DiagRequest" "No";
BA_DEF_DEF_  "DiagResponse" "No";
BA_DEF_DEF_  "GenMsgILSupport" "Yes";
BA_ "GenMsgCycleTime" BO_ 549 1000;
BA_ "GenMsgSendType" BO_ 549 5;
BA_ "GenMsgCycleTime" BO_ 765 1000;
BA_ "GenMsgSendType" BO_ 765 5;
BA_ "NetworkInitialization" BO_ 508 0;
BA_ "GenMsgSendType" BO_ 508 1;
BA_ "NetworkInitialization" BO_ 507 0;
BA_ "GenMsgSendType" BO_ 507 1;
BA_ "NetworkInitialization" BO_ 506 0;
BA_ "GenMsgSendType" BO_ 506 1;
BA_ "NetworkInitialization" BO_ 505 0;
BA_ "GenMsgSendType" BO_ 505 1;
BA_ "NetworkInitialization" BO_ 403 0;
BA_ "GenMsgSendType" BO_ 403 1;
BA_ "GenMsgSendType" BO_ 401 1;
BA_ "FrameRouting" BO_ 1143 "FD1_CAN,0x477;";
BA_ "FrameRouting" BO_ 1142 "FD1_CAN,0x476;";
BA_ "FrameRouting" BO_ 973 "FD1_CAN,0x3CD;FD3_CAN,0x3CD";
BA_ "NetworkInitialization" BO_ 405 0;
BA_ "GenMsgSendType" BO_ 405 1;
BA_ "GenMsgCycleTime" BO_ 756 1000;
BA_ "GenMsgSendType" BO_ 756 5;
BA_ "GenMsgCycleTime" BO_ 544 1000;
BA_ "GenMsgSendType" BO_ 544 5;
BA_ "NetworkInitialization" BO_ 291 0;
BA_ "GenMsgSendType" BO_ 291 1;
BA_ "NetworkInitialization" BO_ 400 0;
BA_ "GenMsgSendType" BO_ 400 1;
BA_ "GenMsgCycleTime" BO_ 647 200;
BA_ "GenMsgSendType" BO_ 647 5;
BA_ "FrameRouting" BO_ 359 "FD1_CAN,0x167;";
BA_ "GenMsgDelayTime" BO_ 359 0;
BA_ "FrameRouting" BO_ 990 "FD3_CAN,0x3DE;";
BA_ "FrameRouting" BO_ 989 "FD1_CAN,0x3DD;FD3_CAN,0x3DD";
BA_ "GenMsgCycleTime" BO_ 1091 1000;
BA_ "GenMsgSendType" BO_ 1091 5;
BA_ "FrameRouting" BO_ 1045 "FD1_CAN,0x415;";
BA_ "NetworkInitialization" BO_ 1439 0;
BA_ "GenMsgCycleTime" BO_ 1439 1000;
BA_ "GenMsgSendType" BO_ 1439 0;
BA_ "NmAsrMessage" BO_ 1439 1;
BA_ "GenMsgILSupport" BO_ 1439 0;
BA_ "GenMsgSendType" BO_ 261 1;
BA_ "FrameRouting" BO_ 995 "FD1_CAN,0x3E3;";
BA_ "GenMsgCycleTime" BO_ 753 1000;
BA_ "GenMsgSendType" BO_ 753 5;
BA_ "GenMsgCycleTime" BO_ 1000 1000;
BA_ "GenMsgSendType" BO_ 1000 5;
BA_ "GenMsgCycleTime" BO_ 992 1000;
BA_ "GenMsgSendType" BO_ 992 5;
BA_ "FrameRouting" BO_ 991 "FD1_CAN,0x3DF;HS2_CAN,0x3DF";
BA_ "FrameRouting" BO_ 1004 "FD1_CAN,0x3EB;";
BA_ "NetworkInitialization" BO_ 1478 0;
BA_ "GenMsgCycleTime" BO_ 1478 1000;
BA_ "GenMsgSendType" BO_ 1478 0;
BA_ "NmAsrMessage" BO_ 1478 1;
BA_ "GenMsgILSupport" BO_ 1478 0;
BA_ "GenMsgCycleTime" BO_ 813 1000;
BA_ "GenMsgSendType" BO_ 813 5;
BA_ "GenMsgCycleTime" BO_ 807 1000;
BA_ "GenMsgSendType" BO_ 807 5;
BA_ "TpTxIndex" BO_ 584 41;
BA_ "FrameRouting" BO_ 1052 "FD1_CAN,0x41C;";
BA_ "GenMsgCycleTime" BO_ 754 1000;
BA_ "GenMsgSendType" BO_ 754 5;
BA_ "GenMsgCycleTime" BO_ 729 1000;
BA_ "GenMsgSendType" BO_ 729 5;
BA_ "GenMsgCycleTime" BO_ 727 1000;
BA_ "GenMsgSendType" BO_ 727 5;
BA_ "GenMsgCycleTime" BO_ 726 1000;
BA_ "GenMsgSendType" BO_ 726 5;
BA_ "FrameRouting" BO_ 369 "FD1_CAN,0x171;";
BA_ "GenMsgDelayTime" BO_ 369 15;
BA_ "NetworkInitialization" BO_ 1832 0;
BA_ "GenMsgDelayTime" BO_ 1832 0;
BA_ "GenMsgSendType" BO_ 1832 1;
BA_ "DiagResponse" BO_ 1832 1;
BA_ "GenMsgILSupport" BO_ 1832 0;
BA_ "GenMsgCycleTime" BO_ 1071 50;
BA_ "GenMsgSendType" BO_ 1071 0;
BA_ "GenMsgRoutingTimeoutTime" BO_ 1071 90;
BA_ "GenMsgCycleTime" BO_ 848 1000;
BA_ "GenMsgSendType" BO_ 848 0;
BA_ "FrameRouting" BO_ 610 "FD1_CAN,0x262;";
BA_ "NetworkInitialization" BO_ 1425 0;
BA_ "GenMsgCycleTime" BO_ 1425 1000;
BA_ "GenMsgSendType" BO_ 1425 0;
BA_ "NmAsrMessage" BO_ 1425 1;
BA_ "GenMsgILSupport" BO_ 1425 0;
BA_ "FrameRouting" BO_ 998 "FD3_CAN,0x3E6;";
BA_ "FrameRouting" BO_ 984 "FD1_CAN,0x3D8;FD3_CAN,0x3D8";
BA_ "GenMsgCycleTime" BO_ 1072 100;
BA_ "GenMsgSendType" BO_ 1072 5;
BA_ "GenMsgCycleTime" BO_ 395 1000;
BA_ "GenMsgSendType" BO_ 395 5;
BA_ "NetworkInitialization" BO_ 1438 0;
BA_ "GenMsgCycleTime" BO_ 1438 1000;
BA_ "GenMsgSendType" BO_ 1438 0;
BA_ "NmAsrMessage" BO_ 1438 1;
BA_ "GenMsgILSupport" BO_ 1438 0;
BA_ "FrameRouting" BO_ 76 "HS2_CAN,0x4C;";
BA_ "GenMsgDelayTime" BO_ 76 10;
BA_ "FrameRouting" BO_ 1034 "FD1_CAN,0x40A;";
BA_ "FrameRouting" BO_ 1069 "FD1_CAN,0x42D;";
BA_ "FrameRouting" BO_ 1057 "FD1_CAN,0x421;";
BA_ "U_V710_MY2023_Tx" SG_ 549 BattTracLoThres_D_Rq2 1;
BA_ "GenSigSendType" SG_ 549 BattTracLoThres_D_Rq2 3;
BA_ "U_P708_MY2023_Tx" SG_ 549 NavIod_D_Rq 1;
BA_ "GenSigSendType" SG_ 549 NavIod_D_Rq 3;
BA_ "U_P708_MY2023_Tx" SG_ 549 StrtInGearOk_D_Stat 1;
BA_ "GenSigSendType" SG_ 549 StrtInGearOk_D_Stat 3;
BA_ "U_V710_MY2023_Tx" SG_ 549 WwaActv_B_Stat 1;
BA_ "U_V713AV_MY2022_Tx" SG_ 549 WwaActv_B_Stat 1;
BA_ "U_V713N_MY2022_Tx" SG_ 549 WwaActv_B_Stat 1;
BA_ "U_V710_MY2023_Rx" SG_ 549 WwaActv_B_Stat 1;
BA_ "U_P708_MY2023_Rx" SG_ 549 WwaActv_B_Stat 1;
BA_ "U_V713AV_MY2022_Rx" SG_ 549 WwaActv_B_Stat 1;
BA_ "U_V713N_MY2022_Rx" SG_ 549 WwaActv_B_Stat 1;
BA_ "GenSigSendType" SG_ 549 WwaActv_B_Stat 3;
BA_ "U_V710_MY2023_Tx" SG_ 549 Veh_V2_Dsply 1;
BA_ "U_P708_MY2023_Tx" SG_ 549 Veh_V2_Dsply 1;
BA_ "U_V713AV_MY2022_Tx" SG_ 549 Veh_V2_Dsply 1;
BA_ "U_V713N_MY2022_Tx" SG_ 549 Veh_V2_Dsply 1;
BA_ "U_P708_MY2023_Rx" SG_ 549 Veh_V2_Dsply 1;
BA_ "GenSigSendType" SG_ 549 Veh_V2_Dsply 3;
BA_ "U_V710_MY2023_Tx" SG_ 549 IPC_MyKeyVolLimit_St 1;
BA_ "U_P708_MY2023_Tx" SG_ 549 IPC_MyKeyVolLimit_St 1;
BA_ "U_V713AV_MY2022_Tx" SG_ 549 IPC_MyKeyVolLimit_St 1;
BA_ "U_V713N_MY2022_Tx" SG_ 549 IPC_MyKeyVolLimit_St 1;
BA_ "U_V710_MY2023_Rx" SG_ 549 IPC_MyKeyVolLimit_St 1;
BA_ "U_P708_MY2023_Rx" SG_ 549 IPC_MyKeyVolLimit_St 1;
BA_ "U_V713AV_MY2022_Rx" SG_ 549 IPC_MyKeyVolLimit_St 1;
BA_ "U_V713N_MY2022_Rx" SG_ 549 IPC_MyKeyVolLimit_St 1;
BA_ "GenSigSendType" SG_ 549 IPC_MyKeyVolLimit_St 3;
BA_ "U_V710_MY2023_Tx" SG_ 549 HudVertSzMnuOn_B_Rq 1;
BA_ "U_V713AV_MY2022_Tx" SG_ 549 HudVertSzMnuOn_B_Rq 1;
BA_ "U_V713N_MY2022_Tx" SG_ 549 HudVertSzMnuOn_B_Rq 1;
BA_ "U_P708_MY2023_Rx" SG_ 549 HudVertSzMnuOn_B_Rq 1;
BA_ "GenSigSendType" SG_ 549 HudVertSzMnuOn_B_Rq 3;
BA_ "U_V710_MY2023_Tx" SG_ 549 HudVertMnuOn_B_Rq 1;
BA_ "U_V713AV_MY2022_Tx" SG_ 549 HudVertMnuOn_B_Rq 1;
BA_ "U_V713N_MY2022_Tx" SG_ 549 HudVertMnuOn_B_Rq 1;
BA_ "U_P708_MY2023_Rx" SG_ 549 HudVertMnuOn_B_Rq 1;
BA_ "GenSigSendType" SG_ 549 HudVertMnuOn_B_Rq 3;
BA_ "U_V713AV_MY2022_Tx" SG_ 549 HudRotatMnuOn_B_Rq 1;
BA_ "U_V713N_MY2022_Tx" SG_ 549 HudRotatMnuOn_B_Rq 1;
BA_ "U_P708_MY2023_Rx" SG_ 549 HudRotatMnuOn_B_Rq 1;
BA_ "GenSigSendType" SG_ 549 HudRotatMnuOn_B_Rq 3;
BA_ "U_V710_MY2023_Tx" SG_ 549 HudCntntMnuOn_B_Rq 1;
BA_ "U_V713AV_MY2022_Tx" SG_ 549 HudCntntMnuOn_B_Rq 1;
BA_ "U_V713N_MY2022_Tx" SG_ 549 HudCntntMnuOn_B_Rq 1;
BA_ "U_P708_MY2023_Rx" SG_ 549 HudCntntMnuOn_B_Rq 1;
BA_ "GenSigSendType" SG_ 549 HudCntntMnuOn_B_Rq 3;
BA_ "U_V710_MY2023_Tx" SG_ 549 HudBrightMnuOn_B_Rq 1;
BA_ "U_V713AV_MY2022_Tx" SG_ 549 HudBrightMnuOn_B_Rq 1;
BA_ "U_V713N_MY2022_Tx" SG_ 549 HudBrightMnuOn_B_Rq 1;
BA_ "U_P708_MY2023_Rx" SG_ 549 HudBrightMnuOn_B_Rq 1;
BA_ "GenSigSendType" SG_ 549 HudBrightMnuOn_B_Rq 3;
BA_ "U_P708_MY2023_Tx" SG_ 549 HdcOn_B_Rq 1;
BA_ "U_V713AV_MY2022_Tx" SG_ 549 HdcOn_B_Rq 1;
BA_ "U_V713N_MY2022_Tx" SG_ 549 HdcOn_B_Rq 1;
BA_ "GenSigSendType" SG_ 549 HdcOn_B_Rq 3;
BA_ "U_V710_MY2023_Tx" SG_ 549 IPC_Attn_Info_Audio 1;
BA_ "U_P708_MY2023_Tx" SG_ 549 IPC_Attn_Info_Audio 1;
BA_ "U_V713AV_MY2022_Tx" SG_ 549 IPC_Attn_Info_Audio 1;
BA_ "U_V713N_MY2022_Tx" SG_ 549 IPC_Attn_Info_Audio 1;
BA_ "U_V710_MY2023_Rx" SG_ 549 IPC_Attn_Info_Audio 1;
BA_ "U_P708_MY2023_Rx" SG_ 549 IPC_Attn_Info_Audio 1;
BA_ "U_V713AV_MY2022_Rx" SG_ 549 IPC_Attn_Info_Audio 1;
BA_ "U_V713N_MY2022_Rx" SG_ 549 IPC_Attn_Info_Audio 1;
BA_ "GenSigSendType" SG_ 549 IPC_Attn_Info_Audio 3;
BA_ "U_V710_MY2023_Tx" SG_ 549 BeltminderAudioMute 1;
BA_ "U_P708_MY2023_Tx" SG_ 549 BeltminderAudioMute 1;
BA_ "U_V713AV_MY2022_Tx" SG_ 549 BeltminderAudioMute 1;
BA_ "U_V713N_MY2022_Tx" SG_ 549 BeltminderAudioMute 1;
BA_ "U_V710_MY2023_Rx" SG_ 549 BeltminderAudioMute 1;
BA_ "U_P708_MY2023_Rx" SG_ 549 BeltminderAudioMute 1;
BA_ "U_V713AV_MY2022_Rx" SG_ 549 BeltminderAudioMute 1;
BA_ "U_V713N_MY2022_Rx" SG_ 549 BeltminderAudioMute 1;
BA_ "GenSigSendType" SG_ 549 BeltminderAudioMute 3;
BA_ "U_V710_MY2023_Tx" SG_ 549 Power_Up_Chime_Modules 1;
BA_ "U_P708_MY2023_Tx" SG_ 549 Power_Up_Chime_Modules 1;
BA_ "U_V713AV_MY2022_Tx" SG_ 549 Power_Up_Chime_Modules 1;
BA_ "U_V713N_MY2022_Tx" SG_ 549 Power_Up_Chime_Modules 1;
BA_ "ECGUsedRxSignal" SG_ 549 Power_Up_Chime_Modules 1;
BA_ "U_V710_MY2023_Rx" SG_ 549 Power_Up_Chime_Modules 1;
BA_ "U_P708_MY2023_Rx" SG_ 549 Power_Up_Chime_Modules 1;
BA_ "U_V713AV_MY2022_Rx" SG_ 549 Power_Up_Chime_Modules 1;
BA_ "U_V713N_MY2022_Rx" SG_ 549 Power_Up_Chime_Modules 1;
BA_ "GenSigSendType" SG_ 549 Power_Up_Chime_Modules 3;
BA_ "WakeupSignal" SG_ 549 Power_Up_Chime_Modules 1;
BA_ "U_V710_MY2023_Tx" SG_ 549 Chime_Source 1;
BA_ "U_P708_MY2023_Tx" SG_ 549 Chime_Source 1;
BA_ "U_V713AV_MY2022_Tx" SG_ 549 Chime_Source 1;
BA_ "U_V713N_MY2022_Tx" SG_ 549 Chime_Source 1;
BA_ "ECGUsedRxSignal" SG_ 549 Chime_Source 1;
BA_ "U_V710_MY2023_Rx" SG_ 549 Chime_Source 1;
BA_ "U_P708_MY2023_Rx" SG_ 549 Chime_Source 1;
BA_ "U_V713AV_MY2022_Rx" SG_ 549 Chime_Source 1;
BA_ "U_V713N_MY2022_Rx" SG_ 549 Chime_Source 1;
BA_ "GenSigSendType" SG_ 549 Chime_Source 3;
BA_ "U_P708_MY2023_Tx" SG_ 549 CCOI_PolicyClient_St2 1;
BA_ "U_V710_MY2023_Rx" SG_ 549 CCOI_PolicyClient_St2 1;
BA_ "ECGUsedRxSignal" SG_ 549 CCOI_PolicyClient_St2 1;
BA_ "GenSigSendType" SG_ 549 CCOI_PolicyClient_St2 3;
BA_ "U_P708_MY2023_Tx" SG_ 549 FactoryReset_Rq2 1;
BA_ "U_V710_MY2023_Rx" SG_ 549 FactoryReset_Rq2 1;
BA_ "ECGUsedRxSignal" SG_ 549 FactoryReset_Rq2 1;
BA_ "GenSigSendType" SG_ 549 FactoryReset_Rq2 3;
BA_ "U_V710_MY2023_Tx" SG_ 549 IPC_New_Attn_Event 1;
BA_ "U_P708_MY2023_Tx" SG_ 549 IPC_New_Attn_Event 1;
BA_ "U_V713AV_MY2022_Tx" SG_ 549 IPC_New_Attn_Event 1;
BA_ "U_V713N_MY2022_Tx" SG_ 549 IPC_New_Attn_Event 1;
BA_ "U_V710_MY2023_Rx" SG_ 549 IPC_New_Attn_Event 1;
BA_ "U_P708_MY2023_Rx" SG_ 549 IPC_New_Attn_Event 1;
BA_ "U_V713AV_MY2022_Rx" SG_ 549 IPC_New_Attn_Event 1;
BA_ "U_V713N_MY2022_Rx" SG_ 549 IPC_New_Attn_Event 1;
BA_ "GenSigSendType" SG_ 549 IPC_New_Attn_Event 3;
BA_ "U_V710_MY2023_Tx" SG_ 549 MetricActv_B_Dsply 1;
BA_ "U_P708_MY2023_Tx" SG_ 549 MetricActv_B_Dsply 1;
BA_ "U_V713AV_MY2022_Tx" SG_ 549 MetricActv_B_Dsply 1;
BA_ "U_V713N_MY2022_Tx" SG_ 549 MetricActv_B_Dsply 1;
BA_ "U_P708_MY2023_Rx" SG_ 549 MetricActv_B_Dsply 1;
BA_ "GenSigSendType" SG_ 549 MetricActv_B_Dsply 3;
BA_ "U_P708_MY2023_Tx" SG_ 765 BalrSwtch_D_Stat 1;
BA_ "U_V713AV_MY2022_Tx" SG_ 765 BalrSwtch_D_Stat 1;
BA_ "U_V713N_MY2022_Tx" SG_ 765 BalrSwtch_D_Stat 1;
BA_ "GenSigSendType" SG_ 765 BalrSwtch_D_Stat 3;
BA_ "GenSigStartValue" SG_ 765 BalrSwtch_D_Stat 1;
BA_ "U_P708_MY2023_Tx" SG_ 765 BalrMde_D_Rq 1;
BA_ "U_V713AV_MY2022_Tx" SG_ 765 BalrMde_D_Rq 1;
BA_ "U_V713N_MY2022_Tx" SG_ 765 BalrMde_D_Rq 1;
BA_ "GenSigSendType" SG_ 765 BalrMde_D_Rq 3;
BA_ "U_V710_MY2023_Tx" SG_ 765 RstrnOnPsngr_D_RqMnu 1;
BA_ "U_V713AV_MY2022_Tx" SG_ 765 RstrnOnPsngr_D_RqMnu 1;
BA_ "U_V713N_MY2022_Tx" SG_ 765 RstrnOnPsngr_D_RqMnu 1;
BA_ "GenSigSendType" SG_ 765 RstrnOnPsngr_D_RqMnu 3;
BA_ "U_V710_MY2023_Tx" SG_ 765 WaitToStartLamp_D_Falt 1;
BA_ "U_P708_MY2023_Tx" SG_ 765 WaitToStartLamp_D_Falt 1;
BA_ "U_V713AV_MY2022_Tx" SG_ 765 WaitToStartLamp_D_Falt 1;
BA_ "U_V713N_MY2022_Tx" SG_ 765 WaitToStartLamp_D_Falt 1;
BA_ "GenSigSendType" SG_ 765 WaitToStartLamp_D_Falt 3;
BA_ "GenSigStartValue" SG_ 765 WaitToStartLamp_D_Falt 1;
BA_ "U_V710_MY2023_Tx" SG_ 765 EsaOn_B_Rq 1;
BA_ "U_P708_MY2023_Tx" SG_ 765 EsaOn_B_Rq 1;
BA_ "U_V713AV_MY2022_Tx" SG_ 765 EsaOn_B_Rq 1;
BA_ "U_V713N_MY2022_Tx" SG_ 765 EsaOn_B_Rq 1;
BA_ "GenSigSendType" SG_ 765 EsaOn_B_Rq 3;
BA_ "GenSigStartValue" SG_ 765 EsaOn_B_Rq 1;
BA_ "U_V710_MY2023_Tx" SG_ 765 BttOn_B_Rq 1;
BA_ "U_P708_MY2023_Tx" SG_ 765 BttOn_B_Rq 1;
BA_ "U_V713AV_MY2022_Tx" SG_ 765 BttOn_B_Rq 1;
BA_ "U_V713N_MY2022_Tx" SG_ 765 BttOn_B_Rq 1;
BA_ "GenSigSendType" SG_ 765 BttOn_B_Rq 3;
BA_ "U_V710_MY2023_Tx" SG_ 765 Btt_L_Actl 1;
BA_ "U_P708_MY2023_Tx" SG_ 765 Btt_L_Actl 1;
BA_ "U_V713AV_MY2022_Tx" SG_ 765 Btt_L_Actl 1;
BA_ "U_V713N_MY2022_Tx" SG_ 765 Btt_L_Actl 1;
BA_ "GenSigStartValue" SG_ 765 Btt_L_Actl 126;
BA_ "U_V713AV_MY2022_Tx" SG_ 765 RearDiffLck_D_RqArb 1;
BA_ "U_V713N_MY2022_Tx" SG_ 765 RearDiffLck_D_RqArb 1;
BA_ "GenSigSendType" SG_ 765 RearDiffLck_D_RqArb 3;
BA_ "GenSigStartValue" SG_ 765 RearDiffLck_D_RqArb 3;
BA_ "U_V713AV_MY2022_Tx" SG_ 765 AwdMde_D_RqArb 1;
BA_ "U_V713N_MY2022_Tx" SG_ 765 AwdMde_D_RqArb 1;
BA_ "GenSigSendType" SG_ 765 AwdMde_D_RqArb 3;
BA_ "GenSigStartValue" SG_ 765 AwdMde_D_RqArb 5;
BA_ "U_V710_MY2023_Tx" SG_ 765 SelDrvMdeTxtReset_B_Rq 1;
BA_ "U_P708_MY2023_Tx" SG_ 765 SelDrvMdeTxtReset_B_Rq 1;
BA_ "U_V713AV_MY2022_Tx" SG_ 765 SelDrvMdeTxtReset_B_Rq 1;
BA_ "U_V713N_MY2022_Tx" SG_ 765 SelDrvMdeTxtReset_B_Rq 1;
BA_ "GenSigSendType" SG_ 765 SelDrvMdeTxtReset_B_Rq 3;
BA_ "U_V713AV_MY2022_Tx" SG_ 765 AutoTowAllw_D_RqMnu 1;
BA_ "U_V713N_MY2022_Tx" SG_ 765 AutoTowAllw_D_RqMnu 1;
BA_ "GenSigSendType" SG_ 765 AutoTowAllw_D_RqMnu 3;
BA_ "U_V710_MY2023_Tx" SG_ 765 DrvInputRequired_B_Rq 1;
BA_ "U_P708_MY2023_Tx" SG_ 765 DrvInputRequired_B_Rq 1;
BA_ "U_V713AV_MY2022_Tx" SG_ 765 DrvInputRequired_B_Rq 1;
BA_ "U_V713N_MY2022_Tx" SG_ 765 DrvInputRequired_B_Rq 1;
BA_ "GenSigSendType" SG_ 765 DrvInputRequired_B_Rq 3;
BA_ "WakeupSignal" SG_ 765 DrvInputRequired_B_Rq 1;
BA_ "U_V710_MY2023_Tx" SG_ 765 SelDrvMdeDsply_B_Avail 1;
BA_ "U_P708_MY2023_Tx" SG_ 765 SelDrvMdeDsply_B_Avail 1;
BA_ "U_V713AV_MY2022_Tx" SG_ 765 SelDrvMdeDsply_B_Avail 1;
BA_ "U_V713N_MY2022_Tx" SG_ 765 SelDrvMdeDsply_B_Avail 1;
BA_ "GenSigSendType" SG_ 765 SelDrvMdeDsply_B_Avail 3;
BA_ "U_V713AV_MY2022_Tx" SG_ 765 EngExhMdeQuiet_D_Rq 1;
BA_ "U_V713N_MY2022_Tx" SG_ 765 EngExhMdeQuiet_D_Rq 1;
BA_ "GenSigSendType" SG_ 765 EngExhMdeQuiet_D_Rq 3;
BA_ "GenSigStartValue" SG_ 765 EngExhMdeQuiet_D_Rq 2;
BA_ "U_V713AV_MY2022_Tx" SG_ 765 AirSusp_D_RqDrv 1;
BA_ "U_V713N_MY2022_Tx" SG_ 765 AirSusp_D_RqDrv 1;
BA_ "GenSigSendType" SG_ 765 AirSusp_D_RqDrv 3;
BA_ "U_V710_MY2023_Tx" SG_ 765 Mc_VehUntTrpCoUsrSel_St 1;
BA_ "U_P708_MY2023_Tx" SG_ 765 Mc_VehUntTrpCoUsrSel_St 1;
BA_ "U_V713AV_MY2022_Tx" SG_ 765 Mc_VehUntTrpCoUsrSel_St 1;
BA_ "U_V713N_MY2022_Tx" SG_ 765 Mc_VehUntTrpCoUsrSel_St 1;
BA_ "U_V710_MY2023_Rx" SG_ 765 Mc_VehUntTrpCoUsrSel_St 1;
BA_ "U_V713AV_MY2022_Rx" SG_ 765 Mc_VehUntTrpCoUsrSel_St 1;
BA_ "U_V713N_MY2022_Rx" SG_ 765 Mc_VehUntTrpCoUsrSel_St 1;
BA_ "ECGUsedRxSignal" SG_ 765 Mc_VehUntTrpCoUsrSel_St 1;
BA_ "U_P708_MY2023_Rx" SG_ 765 Mc_VehUntTrpCoUsrSel_St 1;
BA_ "GenSigSendType" SG_ 765 Mc_VehUntTrpCoUsrSel_St 3;
BA_ "U_V710_MY2023_Tx" SG_ 765 Mc_VehUnitTempUsrSel_St 1;
BA_ "U_P708_MY2023_Tx" SG_ 765 Mc_VehUnitTempUsrSel_St 1;
BA_ "U_V713AV_MY2022_Tx" SG_ 765 Mc_VehUnitTempUsrSel_St 1;
BA_ "U_V713N_MY2022_Tx" SG_ 765 Mc_VehUnitTempUsrSel_St 1;
BA_ "U_P708_MY2023_Rx" SG_ 765 Mc_VehUnitTempUsrSel_St 1;
BA_ "GenSigSendType" SG_ 765 Mc_VehUnitTempUsrSel_St 3;
BA_ "U_V713AV_MY2022_Tx" SG_ 765 Mc_VehDayNightUsrSel_St 1;
BA_ "U_V713N_MY2022_Tx" SG_ 765 Mc_VehDayNightUsrSel_St 1;
BA_ "U_V710_MY2023_Rx" SG_ 765 Mc_VehDayNightUsrSel_St 1;
BA_ "U_P708_MY2023_Rx" SG_ 765 Mc_VehDayNightUsrSel_St 1;
BA_ "U_V713AV_MY2022_Rx" SG_ 765 Mc_VehDayNightUsrSel_St 1;
BA_ "U_V713N_MY2022_Rx" SG_ 765 Mc_VehDayNightUsrSel_St 1;
BA_ "GenSigSendType" SG_ 765 Mc_VehDayNightUsrSel_St 3;
BA_ "U_V710_MY2023_Tx" SG_ 765 Mc_VehTimeFrmtUsrSel_St 1;
BA_ "U_P708_MY2023_Tx" SG_ 765 Mc_VehTimeFrmtUsrSel_St 1;
BA_ "U_V713AV_MY2022_Tx" SG_ 765 Mc_VehTimeFrmtUsrSel_St 1;
BA_ "U_V713N_MY2022_Tx" SG_ 765 Mc_VehTimeFrmtUsrSel_St 1;
BA_ "U_P708_MY2023_Rx" SG_ 765 Mc_VehTimeFrmtUsrSel_St 1;
BA_ "GenSigSendType" SG_ 765 Mc_VehTimeFrmtUsrSel_St 3;
BA_ "U_V713AV_MY2022_Tx" SG_ 765 Mc_VehThemeUsrSel_St 1;
BA_ "U_V713N_MY2022_Tx" SG_ 765 Mc_VehThemeUsrSel_St 1;
BA_ "GenSigSendType" SG_ 765 Mc_VehThemeUsrSel_St 3;
BA_ "U_V710_MY2023_Tx" SG_ 765 Mc_VehLangUsrSel_St 1;
BA_ "U_P708_MY2023_Tx" SG_ 765 Mc_VehLangUsrSel_St 1;
BA_ "U_V713AV_MY2022_Tx" SG_ 765 Mc_VehLangUsrSel_St 1;
BA_ "U_V713N_MY2022_Tx" SG_ 765 Mc_VehLangUsrSel_St 1;
BA_ "U_V710_MY2023_Rx" SG_ 765 Mc_VehLangUsrSel_St 1;
BA_ "U_P708_MY2023_Rx" SG_ 765 Mc_VehLangUsrSel_St 1;
BA_ "U_V713AV_MY2022_Rx" SG_ 765 Mc_VehLangUsrSel_St 1;
BA_ "U_V713N_MY2022_Rx" SG_ 765 Mc_VehLangUsrSel_St 1;
BA_ "GenSigSendType" SG_ 765 Mc_VehLangUsrSel_St 3;
BA_ "U_V710_MY2023_Tx" SG_ 765 AwdRnge_D_ActlIpc 1;
BA_ "U_P708_MY2023_Tx" SG_ 765 AwdRnge_D_ActlIpc 1;
BA_ "U_V713AV_MY2022_Tx" SG_ 765 AwdRnge_D_ActlIpc 1;
BA_ "U_V713N_MY2022_Tx" SG_ 765 AwdRnge_D_ActlIpc 1;
BA_ "GenSigSendType" SG_ 765 AwdRnge_D_ActlIpc 3;
BA_ "GenSigStartValue" SG_ 765 AwdRnge_D_ActlIpc 7;
BA_ "U_V713AV_MY2022_Tx" SG_ 765 AwdDrvMde_D_Rq 1;
BA_ "U_V713N_MY2022_Tx" SG_ 765 AwdDrvMde_D_Rq 1;
BA_ "GenSigSendType" SG_ 765 AwdDrvMde_D_Rq 3;
BA_ "U_V713AV_MY2022_Tx" SG_ 765 EngExhMdeQuiet_D2_Rq 1;
BA_ "U_V713N_MY2022_Tx" SG_ 765 EngExhMdeQuiet_D2_Rq 1;
BA_ "GenSigSendType" SG_ 765 EngExhMdeQuiet_D2_Rq 3;
BA_ "U_V713AV_MY2022_Tx" SG_ 765 BrkLineLck_D_Rq 1;
BA_ "U_V713N_MY2022_Tx" SG_ 765 BrkLineLck_D_Rq 1;
BA_ "GenSigSendType" SG_ 765 BrkLineLck_D_Rq 3;
BA_ "U_V710_MY2023_Tx" SG_ 765 EdmSailMde_B_RqDrv 1;
BA_ "U_P708_MY2023_Tx" SG_ 765 EdmSailMde_B_RqDrv 1;
BA_ "U_V713AV_MY2022_Tx" SG_ 765 EdmSailMde_B_RqDrv 1;
BA_ "U_V713N_MY2022_Tx" SG_ 765 EdmSailMde_B_RqDrv 1;
BA_ "GenSigSendType" SG_ 765 EdmSailMde_B_RqDrv 3;
BA_ "U_V710_MY2023_Tx" SG_ 765 Running_Board_Cmd 1;
BA_ "U_P708_MY2023_Tx" SG_ 765 Running_Board_Cmd 1;
BA_ "GenSigSendType" SG_ 765 Running_Board_Cmd 3;
BA_ "U_V710_MY2023_Rx" SG_ 508 Mc_DB1GetInfStartInd_Rq 1;
BA_ "U_P708_MY2023_Rx" SG_ 508 Mc_DB1GetInfStartInd_Rq 1;
BA_ "U_V713AV_MY2022_Rx" SG_ 508 Mc_DB1GetInfStartInd_Rq 1;
BA_ "U_V713N_MY2022_Rx" SG_ 508 Mc_DB1GetInfStartInd_Rq 1;
BA_ "GenSigSendType" SG_ 508 Mc_DB1GetInfStartInd_Rq 1;
BA_ "U_V710_MY2023_Rx" SG_ 508 Mc_DB1GtInfNbrOfItms_Rq 1;
BA_ "U_P708_MY2023_Rx" SG_ 508 Mc_DB1GtInfNbrOfItms_Rq 1;
BA_ "U_V713AV_MY2022_Rx" SG_ 508 Mc_DB1GtInfNbrOfItms_Rq 1;
BA_ "U_V713N_MY2022_Rx" SG_ 508 Mc_DB1GtInfNbrOfItms_Rq 1;
BA_ "U_V710_MY2023_Rx" SG_ 508 Mc_DB1GetInfSetConf_Rq 1;
BA_ "U_P708_MY2023_Rx" SG_ 508 Mc_DB1GetInfSetConf_Rq 1;
BA_ "U_V713AV_MY2022_Rx" SG_ 508 Mc_DB1GetInfSetConf_Rq 1;
BA_ "U_V713N_MY2022_Rx" SG_ 508 Mc_DB1GetInfSetConf_Rq 1;
BA_ "U_V710_MY2023_Rx" SG_ 508 Mc_DB1GetInfSetFilt3_Rq 1;
BA_ "U_P708_MY2023_Rx" SG_ 508 Mc_DB1GetInfSetFilt3_Rq 1;
BA_ "U_V713AV_MY2022_Rx" SG_ 508 Mc_DB1GetInfSetFilt3_Rq 1;
BA_ "U_V713N_MY2022_Rx" SG_ 508 Mc_DB1GetInfSetFilt3_Rq 1;
BA_ "U_V710_MY2023_Rx" SG_ 508 Mc_DB1GetInfSetFilt2_Rq 1;
BA_ "U_P708_MY2023_Rx" SG_ 508 Mc_DB1GetInfSetFilt2_Rq 1;
BA_ "U_V713AV_MY2022_Rx" SG_ 508 Mc_DB1GetInfSetFilt2_Rq 1;
BA_ "U_V713N_MY2022_Rx" SG_ 508 Mc_DB1GetInfSetFilt2_Rq 1;
BA_ "U_V710_MY2023_Rx" SG_ 508 Mc_DB1GetInfSetFilt1_Rq 1;
BA_ "U_P708_MY2023_Rx" SG_ 508 Mc_DB1GetInfSetFilt1_Rq 1;
BA_ "U_V713AV_MY2022_Rx" SG_ 508 Mc_DB1GetInfSetFilt1_Rq 1;
BA_ "U_V713N_MY2022_Rx" SG_ 508 Mc_DB1GetInfSetFilt1_Rq 1;
BA_ "U_V710_MY2023_Rx" SG_ 507 Mc_DB1SetTrkItmIndex_Rq 1;
BA_ "U_P708_MY2023_Rx" SG_ 507 Mc_DB1SetTrkItmIndex_Rq 1;
BA_ "U_V713AV_MY2022_Rx" SG_ 507 Mc_DB1SetTrkItmIndex_Rq 1;
BA_ "U_V713N_MY2022_Rx" SG_ 507 Mc_DB1SetTrkItmIndex_Rq 1;
BA_ "GenSigSendType" SG_ 507 Mc_DB1SetTrkItmIndex_Rq 1;
BA_ "U_V710_MY2023_Rx" SG_ 507 Mc_DB1SetTrkSetConf_Rq 1;
BA_ "U_P708_MY2023_Rx" SG_ 507 Mc_DB1SetTrkSetConf_Rq 1;
BA_ "U_V713AV_MY2022_Rx" SG_ 507 Mc_DB1SetTrkSetConf_Rq 1;
BA_ "U_V713N_MY2022_Rx" SG_ 507 Mc_DB1SetTrkSetConf_Rq 1;
BA_ "U_V710_MY2023_Rx" SG_ 507 Mc_DB1SetTrkSetFilt3_Rq 1;
BA_ "U_P708_MY2023_Rx" SG_ 507 Mc_DB1SetTrkSetFilt3_Rq 1;
BA_ "U_V713AV_MY2022_Rx" SG_ 507 Mc_DB1SetTrkSetFilt3_Rq 1;
BA_ "U_V713N_MY2022_Rx" SG_ 507 Mc_DB1SetTrkSetFilt3_Rq 1;
BA_ "U_V710_MY2023_Rx" SG_ 507 Mc_DB1SetTrkSetFilt2_Rq 1;
BA_ "U_P708_MY2023_Rx" SG_ 507 Mc_DB1SetTrkSetFilt2_Rq 1;
BA_ "U_V713AV_MY2022_Rx" SG_ 507 Mc_DB1SetTrkSetFilt2_Rq 1;
BA_ "U_V713N_MY2022_Rx" SG_ 507 Mc_DB1SetTrkSetFilt2_Rq 1;
BA_ "U_V710_MY2023_Rx" SG_ 507 Mc_DB1SetTrkSetFilt1_Rq 1;
BA_ "U_P708_MY2023_Rx" SG_ 507 Mc_DB1SetTrkSetFilt1_Rq 1;
BA_ "U_V713AV_MY2022_Rx" SG_ 507 Mc_DB1SetTrkSetFilt1_Rq 1;
BA_ "U_V713N_MY2022_Rx" SG_ 507 Mc_DB1SetTrkSetFilt1_Rq 1;
BA_ "U_V710_MY2023_Rx" SG_ 506 Mc_AudioSourceSel3_Rq 1;
BA_ "U_P708_MY2023_Rx" SG_ 506 Mc_AudioSourceSel3_Rq 1;
BA_ "U_V713AV_MY2022_Rx" SG_ 506 Mc_AudioSourceSel3_Rq 1;
BA_ "U_V713N_MY2022_Rx" SG_ 506 Mc_AudioSourceSel3_Rq 1;
BA_ "GenSigSendType" SG_ 506 Mc_AudioSourceSel3_Rq 3;
BA_ "U_V710_MY2023_Rx" SG_ 506 Mc_PlayFrstTrInFldr_Rq 1;
BA_ "U_P708_MY2023_Rx" SG_ 506 Mc_PlayFrstTrInFldr_Rq 1;
BA_ "U_V713AV_MY2022_Rx" SG_ 506 Mc_PlayFrstTrInFldr_Rq 1;
BA_ "U_V713N_MY2022_Rx" SG_ 506 Mc_PlayFrstTrInFldr_Rq 1;
BA_ "U_V710_MY2023_Rx" SG_ 506 Mc_ItemIndex_Rq 1;
BA_ "U_P708_MY2023_Rx" SG_ 506 Mc_ItemIndex_Rq 1;
BA_ "U_V713AV_MY2022_Rx" SG_ 506 Mc_ItemIndex_Rq 1;
BA_ "U_V713N_MY2022_Rx" SG_ 506 Mc_ItemIndex_Rq 1;
BA_ "U_V710_MY2023_Rx" SG_ 506 Mc_FolderNumber3_Rq 1;
BA_ "U_P708_MY2023_Rx" SG_ 506 Mc_FolderNumber3_Rq 1;
BA_ "U_V713AV_MY2022_Rx" SG_ 506 Mc_FolderNumber3_Rq 1;
BA_ "U_V713N_MY2022_Rx" SG_ 506 Mc_FolderNumber3_Rq 1;
BA_ "U_V710_MY2023_Rx" SG_ 505 Mc_AudioSourceSel2_Rq 1;
BA_ "U_P708_MY2023_Rx" SG_ 505 Mc_AudioSourceSel2_Rq 1;
BA_ "U_V713AV_MY2022_Rx" SG_ 505 Mc_AudioSourceSel2_Rq 1;
BA_ "U_V713N_MY2022_Rx" SG_ 505 Mc_AudioSourceSel2_Rq 1;
BA_ "GenSigSendType" SG_ 505 Mc_AudioSourceSel2_Rq 3;
BA_ "U_V710_MY2023_Rx" SG_ 505 Mc_StartItemIndexRq 1;
BA_ "U_P708_MY2023_Rx" SG_ 505 Mc_StartItemIndexRq 1;
BA_ "U_V713AV_MY2022_Rx" SG_ 505 Mc_StartItemIndexRq 1;
BA_ "U_V713N_MY2022_Rx" SG_ 505 Mc_StartItemIndexRq 1;
BA_ "U_V710_MY2023_Rx" SG_ 505 Mc_NbrOfItems2_Rq 1;
BA_ "U_P708_MY2023_Rx" SG_ 505 Mc_NbrOfItems2_Rq 1;
BA_ "U_V713AV_MY2022_Rx" SG_ 505 Mc_NbrOfItems2_Rq 1;
BA_ "U_V713N_MY2022_Rx" SG_ 505 Mc_NbrOfItems2_Rq 1;
BA_ "U_V710_MY2023_Rx" SG_ 505 Mc_ItemNameLength2_Rq 1;
BA_ "U_P708_MY2023_Rx" SG_ 505 Mc_ItemNameLength2_Rq 1;
BA_ "U_V713AV_MY2022_Rx" SG_ 505 Mc_ItemNameLength2_Rq 1;
BA_ "U_V713N_MY2022_Rx" SG_ 505 Mc_ItemNameLength2_Rq 1;
BA_ "U_V710_MY2023_Rx" SG_ 505 Mc_CutItem2_Rq 1;
BA_ "U_P708_MY2023_Rx" SG_ 505 Mc_CutItem2_Rq 1;
BA_ "U_V713AV_MY2022_Rx" SG_ 505 Mc_CutItem2_Rq 1;
BA_ "U_V713N_MY2022_Rx" SG_ 505 Mc_CutItem2_Rq 1;
BA_ "U_V710_MY2023_Rx" SG_ 505 Mc_FolderNumber2_Rq 1;
BA_ "U_P708_MY2023_Rx" SG_ 505 Mc_FolderNumber2_Rq 1;
BA_ "U_V713AV_MY2022_Rx" SG_ 505 Mc_FolderNumber2_Rq 1;
BA_ "U_V713N_MY2022_Rx" SG_ 505 Mc_FolderNumber2_Rq 1;
BA_ "U_V710_MY2023_Rx" SG_ 505 Mc_FolderContent_Rq 1;
BA_ "U_P708_MY2023_Rx" SG_ 505 Mc_FolderContent_Rq 1;
BA_ "U_V713AV_MY2022_Rx" SG_ 505 Mc_FolderContent_Rq 1;
BA_ "U_V713N_MY2022_Rx" SG_ 505 Mc_FolderContent_Rq 1;
BA_ "U_V710_MY2023_Tx" SG_ 403 McLangSel2_Rq 1;
BA_ "U_P708_MY2023_Tx" SG_ 403 McLangSel2_Rq 1;
BA_ "U_V713AV_MY2022_Tx" SG_ 403 McLangSel2_Rq 1;
BA_ "U_V713N_MY2022_Tx" SG_ 403 McLangSel2_Rq 1;
BA_ "GenSigSendType" SG_ 403 McLangSel2_Rq 3;
BA_ "U_P708_MY2023_Tx" SG_ 403 DealerCall_B_Rq 1;
BA_ "U_V713AV_MY2022_Tx" SG_ 403 DealerCall_B_Rq 1;
BA_ "U_V713N_MY2022_Tx" SG_ 403 DealerCall_B_Rq 1;
BA_ "GenSigSendType" SG_ 403 DealerCall_B_Rq 3;
BA_ "U_V710_MY2023_Tx" SG_ 403 Mc_RepeatGuidance_Rq 1;
BA_ "U_V713AV_MY2022_Tx" SG_ 403 Mc_RepeatGuidance_Rq 1;
BA_ "U_V713N_MY2022_Tx" SG_ 403 Mc_RepeatGuidance_Rq 1;
BA_ "GenSigSendType" SG_ 403 Mc_RepeatGuidance_Rq 3;
BA_ "U_V710_MY2023_Tx" SG_ 403 Mc_CancelRoute_Rq 1;
BA_ "U_V713AV_MY2022_Tx" SG_ 403 Mc_CancelRoute_Rq 1;
BA_ "U_V713N_MY2022_Tx" SG_ 403 Mc_CancelRoute_Rq 1;
BA_ "GenSigSendType" SG_ 403 Mc_CancelRoute_Rq 3;
BA_ "U_V710_MY2023_Tx" SG_ 403 Mc_CancelCurrWaypt_Rq 1;
BA_ "U_P708_MY2023_Tx" SG_ 403 Mc_CancelCurrWaypt_Rq 1;
BA_ "U_V713AV_MY2022_Tx" SG_ 403 Mc_CancelCurrWaypt_Rq 1;
BA_ "U_V713N_MY2022_Tx" SG_ 403 Mc_CancelCurrWaypt_Rq 1;
BA_ "GenSigSendType" SG_ 403 Mc_CancelCurrWaypt_Rq 3;
BA_ "U_V710_MY2023_Tx" SG_ 403 Mc_TextMessage_Rq 1;
BA_ "U_V713AV_MY2022_Tx" SG_ 403 Mc_TextMessage_Rq 1;
BA_ "U_V713N_MY2022_Tx" SG_ 403 Mc_TextMessage_Rq 1;
BA_ "GenSigSendType" SG_ 403 Mc_TextMessage_Rq 3;
BA_ "U_V710_MY2023_Tx" SG_ 403 Mc_BTInCallOptions_Rq 1;
BA_ "U_P708_MY2023_Tx" SG_ 403 Mc_BTInCallOptions_Rq 1;
BA_ "U_V713AV_MY2022_Tx" SG_ 403 Mc_BTInCallOptions_Rq 1;
BA_ "U_V713N_MY2022_Tx" SG_ 403 Mc_BTInCallOptions_Rq 1;
BA_ "GenSigSendType" SG_ 403 Mc_BTInCallOptions_Rq 3;
BA_ "U_V710_MY2023_Tx" SG_ 403 Mc_PhMicrophoneMute_Rq 1;
BA_ "U_P708_MY2023_Tx" SG_ 403 Mc_PhMicrophoneMute_Rq 1;
BA_ "U_V713AV_MY2022_Tx" SG_ 403 Mc_PhMicrophoneMute_Rq 1;
BA_ "U_V713N_MY2022_Tx" SG_ 403 Mc_PhMicrophoneMute_Rq 1;
BA_ "GenSigSendType" SG_ 403 Mc_PhMicrophoneMute_Rq 3;
BA_ "U_V710_MY2023_Tx" SG_ 403 Mc_LangSel_Rq 1;
BA_ "U_P708_MY2023_Tx" SG_ 403 Mc_LangSel_Rq 1;
BA_ "U_V713AV_MY2022_Tx" SG_ 403 Mc_LangSel_Rq 1;
BA_ "U_V713N_MY2022_Tx" SG_ 403 Mc_LangSel_Rq 1;
BA_ "GenSigSendType" SG_ 403 Mc_LangSel_Rq 3;
BA_ "GenSigSendType" SG_ 401 Bezel_Beeps_Rq 3;
BA_ "WakeupSignal" SG_ 401 Bezel_Beeps_Rq 1;
BA_ "U_V710_MY2023_Rx" SG_ 401 Disp_VehUntTripCoUsrSel 1;
BA_ "U_P708_MY2023_Rx" SG_ 401 Disp_VehUntTripCoUsrSel 1;
BA_ "U_V713AV_MY2022_Rx" SG_ 401 Disp_VehUntTripCoUsrSel 1;
BA_ "U_V713N_MY2022_Rx" SG_ 401 Disp_VehUntTripCoUsrSel 1;
BA_ "GenSigSendType" SG_ 401 Disp_VehUntTripCoUsrSel 3;
BA_ "GenSigStartValue" SG_ 401 Disp_VehUntTripCoUsrSel 3;
BA_ "U_V710_MY2023_Rx" SG_ 401 Disp_VehUnitTempUsrSel 1;
BA_ "U_P708_MY2023_Rx" SG_ 401 Disp_VehUnitTempUsrSel 1;
BA_ "U_V713AV_MY2022_Rx" SG_ 401 Disp_VehUnitTempUsrSel 1;
BA_ "U_V713N_MY2022_Rx" SG_ 401 Disp_VehUnitTempUsrSel 1;
BA_ "GenSigSendType" SG_ 401 Disp_VehUnitTempUsrSel 3;
BA_ "GenSigStartValue" SG_ 401 Disp_VehUnitTempUsrSel 3;
BA_ "U_V710_MY2023_Rx" SG_ 401 Disp_LangSel_Rq 1;
BA_ "U_P708_MY2023_Rx" SG_ 401 Disp_LangSel_Rq 1;
BA_ "U_V713AV_MY2022_Rx" SG_ 401 Disp_LangSel_Rq 1;
BA_ "U_V713N_MY2022_Rx" SG_ 401 Disp_LangSel_Rq 1;
BA_ "GenSigSendType" SG_ 401 Disp_LangSel_Rq 3;
BA_ "U_V710_MY2023_Rx" SG_ 401 Disp_LangSel2_Rq 1;
BA_ "U_P708_MY2023_Rx" SG_ 401 Disp_LangSel2_Rq 1;
BA_ "U_V713AV_MY2022_Rx" SG_ 401 Disp_LangSel2_Rq 1;
BA_ "U_V713N_MY2022_Rx" SG_ 401 Disp_LangSel2_Rq 1;
BA_ "GenSigSendType" SG_ 401 Disp_LangSel2_Rq 3;
BA_ "U_V713AV_MY2022_Rx" SG_ 1143 EffAvgChrg_Pc_Dsply 1;
BA_ "U_V713N_MY2022_Rx" SG_ 1143 EffAvgChrg_Pc_Dsply 1;
BA_ "GenSigStartValue" SG_ 1143 ConsTipTot_Pc_Dsply 1022;
BA_ "U_V710_MY2023_Rx" SG_ 973 LaSysOffStat_D_Dsply 1;
BA_ "U_P708_MY2023_Rx" SG_ 973 LaSysOffStat_D_Dsply 1;
BA_ "U_V713AV_MY2022_Rx" SG_ 973 LaSysOffStat_D_Dsply 1;
BA_ "U_V713N_MY2022_Rx" SG_ 973 LaSysOffStat_D_Dsply 1;
BA_ "U_V710_MY2023_Rx" SG_ 973 TsrVl1RstrcMsgTxt2_D_Rq 1;
BA_ "U_P708_MY2023_Rx" SG_ 973 TsrVl1RstrcMsgTxt2_D_Rq 1;
BA_ "U_V713AV_MY2022_Rx" SG_ 973 TsrVl1RstrcMsgTxt2_D_Rq 1;
BA_ "U_V713N_MY2022_Rx" SG_ 973 TsrVl1RstrcMsgTxt2_D_Rq 1;
BA_ "GenSigStartValue" SG_ 973 TsrVl1RstrcMsgTxt2_D_Rq 1;
BA_ "U_V710_MY2023_Rx" SG_ 973 TsrVl2RstrcMsgTxt2_D_Rq 1;
BA_ "U_P708_MY2023_Rx" SG_ 973 TsrVl2RstrcMsgTxt2_D_Rq 1;
BA_ "U_V713AV_MY2022_Rx" SG_ 973 TsrVl2RstrcMsgTxt2_D_Rq 1;
BA_ "U_V713N_MY2022_Rx" SG_ 973 TsrVl2RstrcMsgTxt2_D_Rq 1;
BA_ "GenSigStartValue" SG_ 973 TsrVl2RstrcMsgTxt2_D_Rq 1;
BA_ "U_V710_MY2023_Rx" SG_ 973 TsrVl2PrmntMsgTxt_D_Rq 1;
BA_ "U_P708_MY2023_Rx" SG_ 973 TsrVl2PrmntMsgTxt_D_Rq 1;
BA_ "U_V713AV_MY2022_Rx" SG_ 973 TsrVl2PrmntMsgTxt_D_Rq 1;
BA_ "U_V713N_MY2022_Rx" SG_ 973 TsrVl2PrmntMsgTxt_D_Rq 1;
BA_ "U_V710_MY2023_Rx" SG_ 973 TsrVl1PrmntMsgTxt_D_Rq 1;
BA_ "U_P708_MY2023_Rx" SG_ 973 TsrVl1PrmntMsgTxt_D_Rq 1;
BA_ "U_V713AV_MY2022_Rx" SG_ 973 TsrVl1PrmntMsgTxt_D_Rq 1;
BA_ "U_V713N_MY2022_Rx" SG_ 973 TsrVl1PrmntMsgTxt_D_Rq 1;
BA_ "U_V710_MY2023_Rx" SG_ 973 TsrOvtkMsgTxt2_D_Rq 1;
BA_ "U_P708_MY2023_Rx" SG_ 973 TsrOvtkMsgTxt2_D_Rq 1;
BA_ "U_V713AV_MY2022_Rx" SG_ 973 TsrOvtkMsgTxt2_D_Rq 1;
BA_ "U_V713N_MY2022_Rx" SG_ 973 TsrOvtkMsgTxt2_D_Rq 1;
BA_ "U_P708_MY2023_Rx" SG_ 973 WwaWarn_B_Rq 1;
BA_ "U_V710_MY2023_Rx" SG_ 973 WwaWarn_B_Rq 1;
BA_ "U_V713AV_MY2022_Rx" SG_ 973 WwaWarn_B_Rq 1;
BA_ "U_V713N_MY2022_Rx" SG_ 973 WwaWarn_B_Rq 1;
BA_ "U_V710_MY2023_Rx" SG_ 973 TsrVlUnitMsgTxt_D_Rq 1;
BA_ "U_P708_MY2023_Rx" SG_ 973 TsrVlUnitMsgTxt_D_Rq 1;
BA_ "U_V713AV_MY2022_Rx" SG_ 973 TsrVlUnitMsgTxt_D_Rq 1;
BA_ "U_V713N_MY2022_Rx" SG_ 973 TsrVlUnitMsgTxt_D_Rq 1;
BA_ "GenSigStartValue" SG_ 973 TsrVlUnitMsgTxt_D_Rq 2;
BA_ "U_V710_MY2023_Rx" SG_ 973 TsrVLim2MsgTxt_D_Rq 1;
BA_ "U_P708_MY2023_Rx" SG_ 973 TsrVLim2MsgTxt_D_Rq 1;
BA_ "U_V713AV_MY2022_Rx" SG_ 973 TsrVLim2MsgTxt_D_Rq 1;
BA_ "U_V713N_MY2022_Rx" SG_ 973 TsrVLim2MsgTxt_D_Rq 1;
BA_ "GenSigStartValue" SG_ 973 TsrVLim2MsgTxt_D_Rq 255;
BA_ "U_V710_MY2023_Rx" SG_ 973 TsrVLim1MsgTxt_D_Rq 1;
BA_ "U_P708_MY2023_Rx" SG_ 973 TsrVLim1MsgTxt_D_Rq 1;
BA_ "U_V713AV_MY2022_Rx" SG_ 973 TsrVLim1MsgTxt_D_Rq 1;
BA_ "U_V713N_MY2022_Rx" SG_ 973 TsrVLim1MsgTxt_D_Rq 1;
BA_ "GenSigStartValue" SG_ 973 TsrVLim1MsgTxt_D_Rq 255;
BA_ "U_V710_MY2023_Rx" SG_ 973 TsrVl2StatMsgTxt_D_Rq 1;
BA_ "U_P708_MY2023_Rx" SG_ 973 TsrVl2StatMsgTxt_D_Rq 1;
BA_ "U_V713AV_MY2022_Rx" SG_ 973 TsrVl2StatMsgTxt_D_Rq 1;
BA_ "U_V713N_MY2022_Rx" SG_ 973 TsrVl2StatMsgTxt_D_Rq 1;
BA_ "U_V713AV_MY2022_Rx" SG_ 973 TsrVl2RstrcMsgTxt_D_Rq 1;
BA_ "U_V713N_MY2022_Rx" SG_ 973 TsrVl2RstrcMsgTxt_D_Rq 1;
BA_ "U_V710_MY2023_Rx" SG_ 973 TsrVl1StatMsgTxt_D_Rq 1;
BA_ "U_P708_MY2023_Rx" SG_ 973 TsrVl1StatMsgTxt_D_Rq 1;
BA_ "U_V713AV_MY2022_Rx" SG_ 973 TsrVl1StatMsgTxt_D_Rq 1;
BA_ "U_V713N_MY2022_Rx" SG_ 973 TsrVl1StatMsgTxt_D_Rq 1;
BA_ "U_V713AV_MY2022_Rx" SG_ 973 TsrVl1RstrcMsgTxt_D_Rq 1;
BA_ "U_V713N_MY2022_Rx" SG_ 973 TsrVl1RstrcMsgTxt_D_Rq 1;
BA_ "U_V713AV_MY2022_Rx" SG_ 973 TsrStatMsgTxt_D_Rq 1;
BA_ "U_V713N_MY2022_Rx" SG_ 973 TsrStatMsgTxt_D_Rq 1;
BA_ "U_V710_MY2023_Rx" SG_ 973 TsrOvtkStatMsgTxt_D_Rq 1;
BA_ "U_P708_MY2023_Rx" SG_ 973 TsrOvtkStatMsgTxt_D_Rq 1;
BA_ "U_V713AV_MY2022_Rx" SG_ 973 TsrOvtkStatMsgTxt_D_Rq 1;
BA_ "U_V713N_MY2022_Rx" SG_ 973 TsrOvtkStatMsgTxt_D_Rq 1;
BA_ "U_V710_MY2023_Rx" SG_ 973 TsrOvtkMsgTxt_D_Rq 1;
BA_ "U_P708_MY2023_Rx" SG_ 973 TsrOvtkMsgTxt_D_Rq 1;
BA_ "U_V713AV_MY2022_Rx" SG_ 973 TsrOvtkMsgTxt_D_Rq 1;
BA_ "U_V713N_MY2022_Rx" SG_ 973 TsrOvtkMsgTxt_D_Rq 1;
BA_ "GenSigStartValue" SG_ 973 TsrOvtkMsgTxt_D_Rq 1;
BA_ "U_V710_MY2023_Rx" SG_ 973 TsrOswWarnMsgTxt_D_Rq 1;
BA_ "U_P708_MY2023_Rx" SG_ 973 TsrOswWarnMsgTxt_D_Rq 1;
BA_ "U_V713AV_MY2022_Rx" SG_ 973 TsrOswWarnMsgTxt_D_Rq 1;
BA_ "U_V713N_MY2022_Rx" SG_ 973 TsrOswWarnMsgTxt_D_Rq 1;
BA_ "GenSigStartValue" SG_ 973 TsrOswWarnMsgTxt_D_Rq 1;
BA_ "U_P708_MY2023_Rx" SG_ 973 TsrMsgTxt_D_Rq 1;
BA_ "U_V713AV_MY2022_Rx" SG_ 973 TsrMsgTxt_D_Rq 1;
BA_ "U_V713N_MY2022_Rx" SG_ 973 TsrMsgTxt_D_Rq 1;
BA_ "GenSigStartValue" SG_ 973 TsrMsgTxt_D_Rq 1;
BA_ "U_V710_MY2023_Tx" SG_ 405 LBC1_StartItemInd 1;
BA_ "U_P708_MY2023_Tx" SG_ 405 LBC1_StartItemInd 1;
BA_ "U_V713AV_MY2022_Tx" SG_ 405 LBC1_StartItemInd 1;
BA_ "U_V713N_MY2022_Tx" SG_ 405 LBC1_StartItemInd 1;
BA_ "U_V710_MY2023_Rx" SG_ 405 LBC1_StartItemInd 1;
BA_ "U_P708_MY2023_Rx" SG_ 405 LBC1_StartItemInd 1;
BA_ "U_V713AV_MY2022_Rx" SG_ 405 LBC1_StartItemInd 1;
BA_ "U_V713N_MY2022_Rx" SG_ 405 LBC1_StartItemInd 1;
BA_ "GenSigSendType" SG_ 405 LBC1_StartItemInd 3;
BA_ "U_V710_MY2023_Tx" SG_ 405 LBC1_SetListServ 1;
BA_ "U_P708_MY2023_Tx" SG_ 405 LBC1_SetListServ 1;
BA_ "U_V713AV_MY2022_Tx" SG_ 405 LBC1_SetListServ 1;
BA_ "U_V713N_MY2022_Tx" SG_ 405 LBC1_SetListServ 1;
BA_ "U_V710_MY2023_Rx" SG_ 405 LBC1_SetListServ 1;
BA_ "U_P708_MY2023_Rx" SG_ 405 LBC1_SetListServ 1;
BA_ "U_V713AV_MY2022_Rx" SG_ 405 LBC1_SetListServ 1;
BA_ "U_V713N_MY2022_Rx" SG_ 405 LBC1_SetListServ 1;
BA_ "GenSigSendType" SG_ 405 LBC1_SetListServ 3;
BA_ "U_V710_MY2023_Tx" SG_ 405 LBC1_Opcode 1;
BA_ "U_P708_MY2023_Tx" SG_ 405 LBC1_Opcode 1;
BA_ "U_V713AV_MY2022_Tx" SG_ 405 LBC1_Opcode 1;
BA_ "U_V713N_MY2022_Tx" SG_ 405 LBC1_Opcode 1;
BA_ "U_V710_MY2023_Rx" SG_ 405 LBC1_Opcode 1;
BA_ "U_P708_MY2023_Rx" SG_ 405 LBC1_Opcode 1;
BA_ "U_V713AV_MY2022_Rx" SG_ 405 LBC1_Opcode 1;
BA_ "U_V713N_MY2022_Rx" SG_ 405 LBC1_Opcode 1;
BA_ "GenSigSendType" SG_ 405 LBC1_Opcode 3;
BA_ "U_V710_MY2023_Tx" SG_ 405 LBC1_NbrOfItems 1;
BA_ "U_P708_MY2023_Tx" SG_ 405 LBC1_NbrOfItems 1;
BA_ "U_V713AV_MY2022_Tx" SG_ 405 LBC1_NbrOfItems 1;
BA_ "U_V713N_MY2022_Tx" SG_ 405 LBC1_NbrOfItems 1;
BA_ "U_V710_MY2023_Rx" SG_ 405 LBC1_NbrOfItems 1;
BA_ "U_P708_MY2023_Rx" SG_ 405 LBC1_NbrOfItems 1;
BA_ "U_V713AV_MY2022_Rx" SG_ 405 LBC1_NbrOfItems 1;
BA_ "U_V713N_MY2022_Rx" SG_ 405 LBC1_NbrOfItems 1;
BA_ "GenSigSendType" SG_ 405 LBC1_NbrOfItems 3;
BA_ "U_V710_MY2023_Tx" SG_ 405 LBC1_ItemIndex 1;
BA_ "U_P708_MY2023_Tx" SG_ 405 LBC1_ItemIndex 1;
BA_ "U_V713AV_MY2022_Tx" SG_ 405 LBC1_ItemIndex 1;
BA_ "U_V713N_MY2022_Tx" SG_ 405 LBC1_ItemIndex 1;
BA_ "U_V710_MY2023_Rx" SG_ 405 LBC1_ItemIndex 1;
BA_ "U_P708_MY2023_Rx" SG_ 405 LBC1_ItemIndex 1;
BA_ "U_V713AV_MY2022_Rx" SG_ 405 LBC1_ItemIndex 1;
BA_ "U_V713N_MY2022_Rx" SG_ 405 LBC1_ItemIndex 1;
BA_ "GenSigSendType" SG_ 405 LBC1_ItemIndex 3;
BA_ "U_V710_MY2023_Tx" SG_ 405 LBC1_ActiveListID 1;
BA_ "U_P708_MY2023_Tx" SG_ 405 LBC1_ActiveListID 1;
BA_ "U_V713AV_MY2022_Tx" SG_ 405 LBC1_ActiveListID 1;
BA_ "U_V713N_MY2022_Tx" SG_ 405 LBC1_ActiveListID 1;
BA_ "U_V710_MY2023_Rx" SG_ 405 LBC1_ActiveListID 1;
BA_ "U_P708_MY2023_Rx" SG_ 405 LBC1_ActiveListID 1;
BA_ "U_V713AV_MY2022_Rx" SG_ 405 LBC1_ActiveListID 1;
BA_ "U_V713N_MY2022_Rx" SG_ 405 LBC1_ActiveListID 1;
BA_ "GenSigSendType" SG_ 405 LBC1_ActiveListID 3;
BA_ "U_V710_MY2023_Tx" SG_ 756 AdjustableChimeVol2_Rq 1;
BA_ "U_P708_MY2023_Tx" SG_ 756 AdjustableChimeVol2_Rq 1;
BA_ "U_V713AV_MY2022_Tx" SG_ 756 AdjustableChimeVol2_Rq 1;
BA_ "U_V713N_MY2022_Tx" SG_ 756 AdjustableChimeVol2_Rq 1;
BA_ "ECGUsedRxSignal" SG_ 756 AdjustableChimeVol2_Rq 1;
BA_ "U_V710_MY2023_Rx" SG_ 756 AdjustableChimeVol2_Rq 1;
BA_ "U_P708_MY2023_Rx" SG_ 756 AdjustableChimeVol2_Rq 1;
BA_ "U_V713AV_MY2022_Rx" SG_ 756 AdjustableChimeVol2_Rq 1;
BA_ "U_V713N_MY2022_Rx" SG_ 756 AdjustableChimeVol2_Rq 1;
BA_ "GenSigSendType" SG_ 756 AdjustableChimeVol2_Rq 3;
BA_ "U_V710_MY2023_Tx" SG_ 756 Off_Time_Btwn_Chime2 1;
BA_ "U_P708_MY2023_Tx" SG_ 756 Off_Time_Btwn_Chime2 1;
BA_ "U_V713AV_MY2022_Tx" SG_ 756 Off_Time_Btwn_Chime2 1;
BA_ "U_V713N_MY2022_Tx" SG_ 756 Off_Time_Btwn_Chime2 1;
BA_ "U_V710_MY2023_Rx" SG_ 756 Off_Time_Btwn_Chime2 1;
BA_ "U_P708_MY2023_Rx" SG_ 756 Off_Time_Btwn_Chime2 1;
BA_ "U_V713AV_MY2022_Rx" SG_ 756 Off_Time_Btwn_Chime2 1;
BA_ "U_V713N_MY2022_Rx" SG_ 756 Off_Time_Btwn_Chime2 1;
BA_ "U_V710_MY2023_Tx" SG_ 756 Chime_Vol_Level2 1;
BA_ "U_P708_MY2023_Tx" SG_ 756 Chime_Vol_Level2 1;
BA_ "U_V713AV_MY2022_Tx" SG_ 756 Chime_Vol_Level2 1;
BA_ "U_V713N_MY2022_Tx" SG_ 756 Chime_Vol_Level2 1;
BA_ "U_V710_MY2023_Rx" SG_ 756 Chime_Vol_Level2 1;
BA_ "U_P708_MY2023_Rx" SG_ 756 Chime_Vol_Level2 1;
BA_ "U_V713AV_MY2022_Rx" SG_ 756 Chime_Vol_Level2 1;
BA_ "U_V713N_MY2022_Rx" SG_ 756 Chime_Vol_Level2 1;
BA_ "U_V710_MY2023_Tx" SG_ 756 Chime_Time_Criticality2 1;
BA_ "U_P708_MY2023_Tx" SG_ 756 Chime_Time_Criticality2 1;
BA_ "U_V713AV_MY2022_Tx" SG_ 756 Chime_Time_Criticality2 1;
BA_ "U_V713N_MY2022_Tx" SG_ 756 Chime_Time_Criticality2 1;
BA_ "ECGUsedRxSignal" SG_ 756 Chime_Time_Criticality2 1;
BA_ "U_V710_MY2023_Rx" SG_ 756 Chime_Time_Criticality2 1;
BA_ "U_P708_MY2023_Rx" SG_ 756 Chime_Time_Criticality2 1;
BA_ "U_V713AV_MY2022_Rx" SG_ 756 Chime_Time_Criticality2 1;
BA_ "U_V713N_MY2022_Rx" SG_ 756 Chime_Time_Criticality2 1;
BA_ "GenSigSendType" SG_ 756 Chime_Time_Criticality2 3;
BA_ "U_V710_MY2023_Tx" SG_ 756 Chime_Occurence2 1;
BA_ "U_P708_MY2023_Tx" SG_ 756 Chime_Occurence2 1;
BA_ "U_V713AV_MY2022_Tx" SG_ 756 Chime_Occurence2 1;
BA_ "U_V713N_MY2022_Tx" SG_ 756 Chime_Occurence2 1;
BA_ "U_V710_MY2023_Rx" SG_ 756 Chime_Occurence2 1;
BA_ "U_P708_MY2023_Rx" SG_ 756 Chime_Occurence2 1;
BA_ "U_V713AV_MY2022_Rx" SG_ 756 Chime_Occurence2 1;
BA_ "U_V713N_MY2022_Rx" SG_ 756 Chime_Occurence2 1;
BA_ "GenSigSendType" SG_ 756 Chime_Occurence2 3;
BA_ "U_V710_MY2023_Tx" SG_ 756 Chime_Directionality2 1;
BA_ "U_P708_MY2023_Tx" SG_ 756 Chime_Directionality2 1;
BA_ "U_V713AV_MY2022_Tx" SG_ 756 Chime_Directionality2 1;
BA_ "U_V713N_MY2022_Tx" SG_ 756 Chime_Directionality2 1;
BA_ "ECGUsedRxSignal" SG_ 756 Chime_Directionality2 1;
BA_ "U_V710_MY2023_Rx" SG_ 756 Chime_Directionality2 1;
BA_ "U_P708_MY2023_Rx" SG_ 756 Chime_Directionality2 1;
BA_ "U_V713AV_MY2022_Rx" SG_ 756 Chime_Directionality2 1;
BA_ "U_V713N_MY2022_Rx" SG_ 756 Chime_Directionality2 1;
BA_ "GenSigSendType" SG_ 756 Chime_Directionality2 3;
BA_ "U_V710_MY2023_Tx" SG_ 756 Chime2 1;
BA_ "U_P708_MY2023_Tx" SG_ 756 Chime2 1;
BA_ "U_V713AV_MY2022_Tx" SG_ 756 Chime2 1;
BA_ "U_V713N_MY2022_Tx" SG_ 756 Chime2 1;
BA_ "U_V710_MY2023_Rx" SG_ 756 Chime2 1;
BA_ "U_P708_MY2023_Rx" SG_ 756 Chime2 1;
BA_ "U_V713AV_MY2022_Rx" SG_ 756 Chime2 1;
BA_ "U_V713N_MY2022_Rx" SG_ 756 Chime2 1;
BA_ "U_V710_MY2023_Tx" SG_ 756 Chime2Id_No_Rq 1;
BA_ "U_P708_MY2023_Tx" SG_ 756 Chime2Id_No_Rq 1;
BA_ "U_V713AV_MY2022_Tx" SG_ 756 Chime2Id_No_Rq 1;
BA_ "U_V713N_MY2022_Tx" SG_ 756 Chime2Id_No_Rq 1;
BA_ "U_V710_MY2023_Rx" SG_ 756 Chime2Id_No_Rq 1;
BA_ "U_P708_MY2023_Rx" SG_ 756 Chime2Id_No_Rq 1;
BA_ "U_V713AV_MY2022_Rx" SG_ 756 Chime2Id_No_Rq 1;
BA_ "U_V713N_MY2022_Rx" SG_ 756 Chime2Id_No_Rq 1;
BA_ "GenSigSendType" SG_ 756 Chime2Id_No_Rq 3;
BA_ "U_V710_MY2023_Tx" SG_ 544 ChimeId_No_Rq 1;
BA_ "U_V713AV_MY2022_Tx" SG_ 544 ChimeId_No_Rq 1;
BA_ "U_V713N_MY2022_Tx" SG_ 544 ChimeId_No_Rq 1;
BA_ "U_V710_MY2023_Rx" SG_ 544 ChimeId_No_Rq 1;
BA_ "U_P708_MY2023_Rx" SG_ 544 ChimeId_No_Rq 1;
BA_ "U_V713AV_MY2022_Rx" SG_ 544 ChimeId_No_Rq 1;
BA_ "U_V713N_MY2022_Rx" SG_ 544 ChimeId_No_Rq 1;
BA_ "GenSigSendType" SG_ 544 ChimeId_No_Rq 3;
BA_ "U_V710_MY2023_Tx" SG_ 544 AdjustableChimeVol_Rq 1;
BA_ "U_P708_MY2023_Tx" SG_ 544 AdjustableChimeVol_Rq 1;
BA_ "U_V713AV_MY2022_Tx" SG_ 544 AdjustableChimeVol_Rq 1;
BA_ "U_V713N_MY2022_Tx" SG_ 544 AdjustableChimeVol_Rq 1;
BA_ "ECGUsedRxSignal" SG_ 544 AdjustableChimeVol_Rq 1;
BA_ "U_V710_MY2023_Rx" SG_ 544 AdjustableChimeVol_Rq 1;
BA_ "U_P708_MY2023_Rx" SG_ 544 AdjustableChimeVol_Rq 1;
BA_ "U_V713AV_MY2022_Rx" SG_ 544 AdjustableChimeVol_Rq 1;
BA_ "U_V713N_MY2022_Rx" SG_ 544 AdjustableChimeVol_Rq 1;
BA_ "GenSigSendType" SG_ 544 AdjustableChimeVol_Rq 3;
BA_ "U_V710_MY2023_Tx" SG_ 544 Chime_Occurence 1;
BA_ "U_P708_MY2023_Tx" SG_ 544 Chime_Occurence 1;
BA_ "U_V713AV_MY2022_Tx" SG_ 544 Chime_Occurence 1;
BA_ "U_V713N_MY2022_Tx" SG_ 544 Chime_Occurence 1;
BA_ "ECGUsedRxSignal" SG_ 544 Chime_Occurence 1;
BA_ "U_V710_MY2023_Rx" SG_ 544 Chime_Occurence 1;
BA_ "U_P708_MY2023_Rx" SG_ 544 Chime_Occurence 1;
BA_ "U_V713AV_MY2022_Rx" SG_ 544 Chime_Occurence 1;
BA_ "U_V713N_MY2022_Rx" SG_ 544 Chime_Occurence 1;
BA_ "GenSigSendType" SG_ 544 Chime_Occurence 3;
BA_ "U_V710_MY2023_Tx" SG_ 544 Off_Time_Btwn_Chime 1;
BA_ "U_P708_MY2023_Tx" SG_ 544 Off_Time_Btwn_Chime 1;
BA_ "U_V713AV_MY2022_Tx" SG_ 544 Off_Time_Btwn_Chime 1;
BA_ "U_V713N_MY2022_Tx" SG_ 544 Off_Time_Btwn_Chime 1;
BA_ "ECGUsedRxSignal" SG_ 544 Off_Time_Btwn_Chime 1;
BA_ "U_V710_MY2023_Rx" SG_ 544 Off_Time_Btwn_Chime 1;
BA_ "U_P708_MY2023_Rx" SG_ 544 Off_Time_Btwn_Chime 1;
BA_ "U_V713AV_MY2022_Rx" SG_ 544 Off_Time_Btwn_Chime 1;
BA_ "U_V713N_MY2022_Rx" SG_ 544 Off_Time_Btwn_Chime 1;
BA_ "U_V710_MY2023_Tx" SG_ 544 Chime_Time_Criticality 1;
BA_ "U_P708_MY2023_Tx" SG_ 544 Chime_Time_Criticality 1;
BA_ "U_V713AV_MY2022_Tx" SG_ 544 Chime_Time_Criticality 1;
BA_ "U_V713N_MY2022_Tx" SG_ 544 Chime_Time_Criticality 1;
BA_ "ECGUsedRxSignal" SG_ 544 Chime_Time_Criticality 1;
BA_ "U_V710_MY2023_Rx" SG_ 544 Chime_Time_Criticality 1;
BA_ "U_P708_MY2023_Rx" SG_ 544 Chime_Time_Criticality 1;
BA_ "U_V713AV_MY2022_Rx" SG_ 544 Chime_Time_Criticality 1;
BA_ "U_V713N_MY2022_Rx" SG_ 544 Chime_Time_Criticality 1;
BA_ "GenSigSendType" SG_ 544 Chime_Time_Criticality 3;
BA_ "U_V710_MY2023_Tx" SG_ 544 Chime_Directionality 1;
BA_ "U_P708_MY2023_Tx" SG_ 544 Chime_Directionality 1;
BA_ "U_V713AV_MY2022_Tx" SG_ 544 Chime_Directionality 1;
BA_ "U_V713N_MY2022_Tx" SG_ 544 Chime_Directionality 1;
BA_ "ECGUsedRxSignal" SG_ 544 Chime_Directionality 1;
BA_ "U_V710_MY2023_Rx" SG_ 544 Chime_Directionality 1;
BA_ "U_P708_MY2023_Rx" SG_ 544 Chime_Directionality 1;
BA_ "U_V713AV_MY2022_Rx" SG_ 544 Chime_Directionality 1;
BA_ "U_V713N_MY2022_Rx" SG_ 544 Chime_Directionality 1;
BA_ "GenSigSendType" SG_ 544 Chime_Directionality 3;
BA_ "U_V710_MY2023_Tx" SG_ 544 Chime_Vol_Level 1;
BA_ "U_P708_MY2023_Tx" SG_ 544 Chime_Vol_Level 1;
BA_ "U_V713AV_MY2022_Tx" SG_ 544 Chime_Vol_Level 1;
BA_ "U_V713N_MY2022_Tx" SG_ 544 Chime_Vol_Level 1;
BA_ "U_V710_MY2023_Rx" SG_ 544 Chime_Vol_Level 1;
BA_ "U_P708_MY2023_Rx" SG_ 544 Chime_Vol_Level 1;
BA_ "U_V713AV_MY2022_Rx" SG_ 544 Chime_Vol_Level 1;
BA_ "U_V713N_MY2022_Rx" SG_ 544 Chime_Vol_Level 1;
BA_ "U_V710_MY2023_Tx" SG_ 544 Chime 1;
BA_ "U_P708_MY2023_Tx" SG_ 544 Chime 1;
BA_ "U_V713AV_MY2022_Tx" SG_ 544 Chime 1;
BA_ "U_V713N_MY2022_Tx" SG_ 544 Chime 1;
BA_ "U_V710_MY2023_Rx" SG_ 544 Chime 1;
BA_ "U_P708_MY2023_Rx" SG_ 544 Chime 1;
BA_ "U_V713AV_MY2022_Rx" SG_ 544 Chime 1;
BA_ "U_V713N_MY2022_Rx" SG_ 544 Chime 1;
BA_ "WakeupSignal" SG_ 544 Chime 1;
BA_ "U_V710_MY2023_Tx" SG_ 291 LangUpdate_Rsp 1;
BA_ "U_P708_MY2023_Tx" SG_ 291 LangUpdate_Rsp 1;
BA_ "U_V713AV_MY2022_Tx" SG_ 291 LangUpdate_Rsp 1;
BA_ "U_V713N_MY2022_Tx" SG_ 291 LangUpdate_Rsp 1;
BA_ "GenSigSendType" SG_ 291 LangUpdate_Rsp 3;
BA_ "U_V713N_MY2022_Tx" SG_ 400 Mc_SetCurrntStatFreq_Rq 1;
BA_ "U_P708_MY2023_Rx" SG_ 400 Mc_SetCurrntStatFreq_Rq 1;
BA_ "U_V713AV_MY2022_Rx" SG_ 400 Mc_SetCurrntStatFreq_Rq 1;
BA_ "U_V713N_MY2022_Rx" SG_ 400 Mc_SetCurrntStatFreq_Rq 1;
BA_ "U_V713N_MY2022_Tx" SG_ 400 Mc_SetCurrStatMCCh_Rq 1;
BA_ "U_P708_MY2023_Rx" SG_ 400 Mc_SetCurrStatMCCh_Rq 1;
BA_ "U_V713AV_MY2022_Rx" SG_ 400 Mc_SetCurrStatMCCh_Rq 1;
BA_ "U_V713N_MY2022_Rx" SG_ 400 Mc_SetCurrStatMCCh_Rq 1;
BA_ "U_V713N_MY2022_Tx" SG_ 400 Mc_SetCurrentStatOp_Rq 1;
BA_ "U_V710_MY2023_Rx" SG_ 400 Mc_SetCurrentStatOp_Rq 1;
BA_ "U_P708_MY2023_Rx" SG_ 400 Mc_SetCurrentStatOp_Rq 1;
BA_ "U_V713AV_MY2022_Rx" SG_ 400 Mc_SetCurrentStatOp_Rq 1;
BA_ "U_V713N_MY2022_Rx" SG_ 400 Mc_SetCurrentStatOp_Rq 1;
BA_ "GenSigSendType" SG_ 400 Mc_SetCurrentStatOp_Rq 3;
BA_ "U_V713N_MY2022_Tx" SG_ 400 Mc_PerTUStartIndex2_Rq 1;
BA_ "U_V710_MY2023_Rx" SG_ 400 Mc_PerTUStartIndex2_Rq 1;
BA_ "U_P708_MY2023_Rx" SG_ 400 Mc_PerTUStartIndex2_Rq 1;
BA_ "U_V713AV_MY2022_Rx" SG_ 400 Mc_PerTUStartIndex2_Rq 1;
BA_ "U_V713N_MY2022_Rx" SG_ 400 Mc_PerTUStartIndex2_Rq 1;
BA_ "U_V713N_MY2022_Tx" SG_ 400 Mc_PerTUPresetArea_Rq 1;
BA_ "U_V710_MY2023_Rx" SG_ 400 Mc_PerTUPresetArea_Rq 1;
BA_ "U_P708_MY2023_Rx" SG_ 400 Mc_PerTUPresetArea_Rq 1;
BA_ "U_V713AV_MY2022_Rx" SG_ 400 Mc_PerTUPresetArea_Rq 1;
BA_ "U_V713N_MY2022_Rx" SG_ 400 Mc_PerTUPresetArea_Rq 1;
BA_ "GenSigSendType" SG_ 400 Mc_PerTUPresetArea_Rq 3;
BA_ "U_V713N_MY2022_Tx" SG_ 400 Mc_PerTUNbrOfPresets_Rq 1;
BA_ "U_V710_MY2023_Rx" SG_ 400 Mc_PerTUNbrOfPresets_Rq 1;
BA_ "U_P708_MY2023_Rx" SG_ 400 Mc_PerTUNbrOfPresets_Rq 1;
BA_ "U_V713AV_MY2022_Rx" SG_ 400 Mc_PerTUNbrOfPresets_Rq 1;
BA_ "U_V713N_MY2022_Rx" SG_ 400 Mc_PerTUNbrOfPresets_Rq 1;
BA_ "U_P708_MY2023_Tx" SG_ 647 HEC_BTIncomingCall_Rq 1;
BA_ "U_V713AV_MY2022_Tx" SG_ 647 HEC_BTIncomingCall_Rq 1;
BA_ "U_V713N_MY2022_Tx" SG_ 647 HEC_BTIncomingCall_Rq 1;
BA_ "GenSigSendType" SG_ 647 HEC_BTIncomingCall_Rq 3;
BA_ "U_P708_MY2023_Tx" SG_ 647 HEC_BTEndTelService_Rq 1;
BA_ "U_V713AV_MY2022_Tx" SG_ 647 HEC_BTEndTelService_Rq 1;
BA_ "U_V713N_MY2022_Tx" SG_ 647 HEC_BTEndTelService_Rq 1;
BA_ "GenSigSendType" SG_ 647 HEC_BTEndTelService_Rq 3;
BA_ "U_V710_MY2023_Rx" SG_ 359 TrnAin_Tq_Actl 1;
BA_ "U_P708_MY2023_Rx" SG_ 359 TrnAin_Tq_Actl 1;
BA_ "U_V713AV_MY2022_Rx" SG_ 359 TrnAin_Tq_Actl 1;
BA_ "U_V713N_MY2022_Rx" SG_ 359 TrnAin_Tq_Actl 1;
BA_ "U_P708_MY2023_Rx" SG_ 359 PrplWhlTot2_Tq_Actl 1;
BA_ "U_V713AV_MY2022_Rx" SG_ 359 PrplWhlTot2_Tq_Actl 1;
BA_ "U_V713N_MY2022_Rx" SG_ 359 PrplWhlTot2_Tq_Actl 1;
BA_ "U_V710_MY2023_Rx" SG_ 359 PwPckTq_D_Stat 1;
BA_ "U_P708_MY2023_Rx" SG_ 359 PwPckTq_D_Stat 1;
BA_ "U_V713AV_MY2022_Rx" SG_ 359 PwPckTq_D_Stat 1;
BA_ "U_V713N_MY2022_Rx" SG_ 359 PwPckTq_D_Stat 1;
BA_ "U_V710_MY2023_Rx" SG_ 359 Eng_D_Stat 1;
BA_ "U_P708_MY2023_Rx" SG_ 359 Eng_D_Stat 1;
BA_ "U_V713AV_MY2022_Rx" SG_ 359 Eng_D_Stat 1;
BA_ "U_V713N_MY2022_Rx" SG_ 359 Eng_D_Stat 1;
BA_ "U_P708_MY2023_Rx" SG_ 359 PlgActvArb_B_Actl 1;
BA_ "GenSigStartValue" SG_ 359 PlgActvArb_B_Actl 1;
BA_ "U_V710_MY2023_Rx" SG_ 359 ElPw_D_Stat 1;
BA_ "U_P708_MY2023_Rx" SG_ 359 ElPw_D_Stat 1;
BA_ "U_V713AV_MY2022_Rx" SG_ 359 ElPw_D_Stat 1;
BA_ "U_V713N_MY2022_Rx" SG_ 359 ElPw_D_Stat 1;
BA_ "U_V710_MY2023_Rx" SG_ 359 TrnAinTq_D_Qf 1;
BA_ "U_P708_MY2023_Rx" SG_ 359 TrnAinTq_D_Qf 1;
BA_ "U_V713AV_MY2022_Rx" SG_ 359 TrnAinTq_D_Qf 1;
BA_ "U_V713N_MY2022_Rx" SG_ 359 TrnAinTq_D_Qf 1;
BA_ "MetaData" SG_ 359 TrnAinTq_D_Qf 1;
BA_ "U_P708_MY2023_Rx" SG_ 990 PersIndexDdm_D_Actl 1;
BA_ "U_V713AV_MY2022_Rx" SG_ 990 PersIndexDdm_D_Actl 1;
BA_ "U_V713N_MY2022_Rx" SG_ 990 PersIndexDdm_D_Actl 1;
BA_ "GenSigStartValue" SG_ 990 PersIndexDdm_D_Actl 4;
BA_ "U_V710_MY2023_Rx" SG_ 990 FeatNoDdm_No_Actl 1;
BA_ "U_P708_MY2023_Rx" SG_ 990 FeatNoDdm_No_Actl 1;
BA_ "U_V713AV_MY2022_Rx" SG_ 990 FeatNoDdm_No_Actl 1;
BA_ "U_V713N_MY2022_Rx" SG_ 990 FeatNoDdm_No_Actl 1;
BA_ "U_V710_MY2023_Rx" SG_ 990 FeatConfigDdmActl 1;
BA_ "U_P708_MY2023_Rx" SG_ 990 FeatConfigDdmActl 1;
BA_ "U_V713AV_MY2022_Rx" SG_ 990 FeatConfigDdmActl 1;
BA_ "U_V713N_MY2022_Rx" SG_ 990 FeatConfigDdmActl 1;
BA_ "U_V710_MY2023_Rx" SG_ 989 FeatNoHcm_No_Actl 1;
BA_ "U_P708_MY2023_Rx" SG_ 989 FeatNoHcm_No_Actl 1;
BA_ "U_V713AV_MY2022_Rx" SG_ 989 FeatNoHcm_No_Actl 1;
BA_ "U_V713N_MY2022_Rx" SG_ 989 FeatNoHcm_No_Actl 1;
BA_ "U_V710_MY2023_Rx" SG_ 989 FeatConfigHcmActl 1;
BA_ "U_P708_MY2023_Rx" SG_ 989 FeatConfigHcmActl 1;
BA_ "U_V713AV_MY2022_Rx" SG_ 989 FeatConfigHcmActl 1;
BA_ "U_V713N_MY2022_Rx" SG_ 989 FeatConfigHcmActl 1;
BA_ "U_V710_MY2023_Tx" SG_ 1091 WakeAlarm2_T_Rq 1;
BA_ "U_P708_MY2023_Tx" SG_ 1091 WakeAlarm2_T_Rq 1;
BA_ "GenSigSendType" SG_ 1091 WakeAlarm2_T_Rq 3;
BA_ "GenSigStartValue" SG_ 1091 WakeAlarm2_T_Rq 32767;
BA_ "U_V710_MY2023_Tx" SG_ 1091 WakeAlarm2_B_Typ 1;
BA_ "U_P708_MY2023_Tx" SG_ 1091 WakeAlarm2_B_Typ 1;
BA_ "GenSigSendType" SG_ 1091 WakeAlarm2_B_Typ 3;
BA_ "U_V710_MY2023_Tx" SG_ 1091 CamraRearOn_D2_Stat2 1;
BA_ "U_V713AV_MY2022_Rx" SG_ 1091 PoliceAux4Lamp_B_Rq2 1;
BA_ "U_V713N_MY2022_Rx" SG_ 1091 PoliceAux4Lamp_B_Rq2 1;
BA_ "U_V713AV_MY2022_Rx" SG_ 1091 PoliceAux3Lamp_B_Rq2 1;
BA_ "U_V713N_MY2022_Rx" SG_ 1091 PoliceAux3Lamp_B_Rq2 1;
BA_ "U_V713AV_MY2022_Rx" SG_ 1091 PoliceAux2Lamp_B_Rq2 1;
BA_ "U_V713N_MY2022_Rx" SG_ 1091 PoliceAux2Lamp_B_Rq2 1;
BA_ "U_V713AV_MY2022_Rx" SG_ 1091 PoliceAux1Lamp_B_Rq2 1;
BA_ "U_V713N_MY2022_Rx" SG_ 1091 PoliceAux1Lamp_B_Rq2 1;
BA_ "U_V710_MY2023_Tx" SG_ 1091 TowBarMsgTxt_D_Rq 1;
BA_ "U_V710_MY2023_Rx" SG_ 1091 TowBarMsgTxt_D_Rq 1;
BA_ "U_V713AV_MY2022_Rx" SG_ 1091 TowBarMsgTxt_D_Rq 1;
BA_ "U_V713N_MY2022_Rx" SG_ 1091 TowBarMsgTxt_D_Rq 1;
BA_ "U_V710_MY2023_Tx" SG_ 1091 ParkLampTrlrOut_B_Stat 1;
BA_ "U_V710_MY2023_Rx" SG_ 1091 ParkLampTrlrOut_B_Stat 1;
BA_ "U_P708_MY2023_Rx" SG_ 1091 ParkLampTrlrOut_B_Stat 1;
BA_ "U_V713AV_MY2022_Rx" SG_ 1091 ParkLampTrlrOut_B_Stat 1;
BA_ "U_V713N_MY2022_Rx" SG_ 1091 ParkLampTrlrOut_B_Stat 1;
BA_ "U_V710_MY2023_Tx" SG_ 1091 StopLampTrlrOut_B_Stat 1;
BA_ "U_V710_MY2023_Rx" SG_ 1091 StopLampTrlrOut_B_Stat 1;
BA_ "U_P708_MY2023_Rx" SG_ 1091 StopLampTrlrOut_B_Stat 1;
BA_ "U_V713AV_MY2022_Rx" SG_ 1091 StopLampTrlrOut_B_Stat 1;
BA_ "U_V713N_MY2022_Rx" SG_ 1091 StopLampTrlrOut_B_Stat 1;
BA_ "U_V710_MY2023_Tx" SG_ 1091 TrlrBattChrg_D_Stat 1;
BA_ "U_P708_MY2023_Tx" SG_ 1091 TrlrBattChrg_D_Stat 1;
BA_ "U_V710_MY2023_Rx" SG_ 1091 TrlrBattChrg_D_Stat 1;
BA_ "U_P708_MY2023_Rx" SG_ 1091 TrlrBattChrg_D_Stat 1;
BA_ "U_V713AV_MY2022_Rx" SG_ 1091 TrlrBattChrg_D_Stat 1;
BA_ "U_V713N_MY2022_Rx" SG_ 1091 TrlrBattChrg_D_Stat 1;
BA_ "U_V710_MY2023_Tx" SG_ 1091 TrlrLampCtl_D_Stat 1;
BA_ "U_P708_MY2023_Tx" SG_ 1091 TrlrLampCtl_D_Stat 1;
BA_ "U_V710_MY2023_Rx" SG_ 1091 TrlrLampCtl_D_Stat 1;
BA_ "U_P708_MY2023_Rx" SG_ 1091 TrlrLampCtl_D_Stat 1;
BA_ "U_V713AV_MY2022_Rx" SG_ 1091 TrlrLampCtl_D_Stat 1;
BA_ "U_V713N_MY2022_Rx" SG_ 1091 TrlrLampCtl_D_Stat 1;
BA_ "U_V710_MY2023_Tx" SG_ 1091 TrlrAlarmSpprt_D_Stat 1;
BA_ "U_P708_MY2023_Tx" SG_ 1091 TrlrAlarmSpprt_D_Stat 1;
BA_ "GenSigSendType" SG_ 1091 TrlrAlarmSpprt_D_Stat 3;
BA_ "U_V710_MY2023_Tx" SG_ 1091 TurnLampTrlrRr_B_Stat 1;
BA_ "U_P708_MY2023_Tx" SG_ 1091 TurnLampTrlrRr_B_Stat 1;
BA_ "U_V710_MY2023_Rx" SG_ 1091 TurnLampTrlrRr_B_Stat 1;
BA_ "U_P708_MY2023_Rx" SG_ 1091 TurnLampTrlrRr_B_Stat 1;
BA_ "U_V713AV_MY2022_Rx" SG_ 1091 TurnLampTrlrRr_B_Stat 1;
BA_ "U_V713N_MY2022_Rx" SG_ 1091 TurnLampTrlrRr_B_Stat 1;
BA_ "U_V710_MY2023_Tx" SG_ 1091 TurnLampTrlrRl_B_Stat 1;
BA_ "U_P708_MY2023_Tx" SG_ 1091 TurnLampTrlrRl_B_Stat 1;
BA_ "U_V710_MY2023_Rx" SG_ 1091 TurnLampTrlrRl_B_Stat 1;
BA_ "U_P708_MY2023_Rx" SG_ 1091 TurnLampTrlrRl_B_Stat 1;
BA_ "U_V713AV_MY2022_Rx" SG_ 1091 TurnLampTrlrRl_B_Stat 1;
BA_ "U_V713N_MY2022_Rx" SG_ 1091 TurnLampTrlrRl_B_Stat 1;
BA_ "U_V710_MY2023_Tx" SG_ 1091 TrlrLampCnnct_B_Actl 1;
BA_ "U_P708_MY2023_Tx" SG_ 1091 TrlrLampCnnct_B_Actl 1;
BA_ "U_V710_MY2023_Rx" SG_ 1091 TrlrLampCnnct_B_Actl 1;
BA_ "U_P708_MY2023_Rx" SG_ 1091 TrlrLampCnnct_B_Actl 1;
BA_ "U_V713AV_MY2022_Rx" SG_ 1091 TrlrLampCnnct_B_Actl 1;
BA_ "U_V713N_MY2022_Rx" SG_ 1091 TrlrLampCnnct_B_Actl 1;
BA_ "GenSigStartValue" SG_ 1045 VehStab_D_Stat 14;
BA_ "GenSigStartValue" SG_ 1045 VehYawNonLin_W_Rq 4094;
BA_ "GenSigStartValue" SG_ 1045 VehYawLin_W_Rq 4094;
BA_ "U_V710_MY2023_Rx" SG_ 1045 VehVActlBrk_No_Cs 1;
BA_ "U_P708_MY2023_Rx" SG_ 1045 VehVActlBrk_No_Cs 1;
BA_ "MetaData" SG_ 1045 VehVActlBrk_No_Cs 1;
BA_ "U_V710_MY2023_Rx" SG_ 1045 Veh_V_ActlBrk 1;
BA_ "U_P708_MY2023_Rx" SG_ 1045 Veh_V_ActlBrk 1;
BA_ "U_V710_MY2023_Rx" SG_ 1045 VehVActlBrk_No_Cnt 1;
BA_ "U_P708_MY2023_Rx" SG_ 1045 VehVActlBrk_No_Cnt 1;
BA_ "MetaData" SG_ 1045 VehVActlBrk_No_Cnt 1;
BA_ "U_V710_MY2023_Rx" SG_ 1045 VehVActlBrk_D_Qf 1;
BA_ "U_P708_MY2023_Rx" SG_ 1045 VehVActlBrk_D_Qf 1;
BA_ "MetaData" SG_ 1045 VehVActlBrk_D_Qf 1;
BA_ "U_V710_MY2023_Tx" SG_ 1439 WCM_GWOnBoardTester 1;
BA_ "U_P708_MY2023_Tx" SG_ 1439 WCM_GWOnBoardTester 1;
BA_ "U_V713N_MY2022_Tx" SG_ 1439 WCM_GWOnBoardTester 1;
BA_ "U_P708_MY2023_Rx" SG_ 1439 WCM_GWOnBoardTester 1;
BA_ "U_V710_MY2023_Rx" SG_ 1439 WCM_GWOnBoardTester 1;
BA_ "GenSigStartValue" SG_ 1439 WCM_GWOnBoardTester 255;
BA_ "U_V710_MY2023_Tx" SG_ 1439 WCM_GWNMProxy 1;
BA_ "U_P708_MY2023_Tx" SG_ 1439 WCM_GWNMProxy 1;
BA_ "U_V713N_MY2022_Tx" SG_ 1439 WCM_GWNMProxy 1;
BA_ "U_P708_MY2023_Rx" SG_ 1439 WCM_GWNMProxy 1;
BA_ "U_V710_MY2023_Rx" SG_ 1439 WCM_GWNMProxy 1;
BA_ "GenSigStartValue" SG_ 1439 WCM_GWNMProxy 255;
BA_ "U_V710_MY2023_Tx" SG_ 1439 WCM_AutoSarNMReserved4 1;
BA_ "U_P708_MY2023_Tx" SG_ 1439 WCM_AutoSarNMReserved4 1;
BA_ "U_V713N_MY2022_Tx" SG_ 1439 WCM_AutoSarNMReserved4 1;
BA_ "U_P708_MY2023_Rx" SG_ 1439 WCM_AutoSarNMReserved4 1;
BA_ "U_V710_MY2023_Rx" SG_ 1439 WCM_AutoSarNMReserved4 1;
BA_ "GenSigStartValue" SG_ 1439 WCM_AutoSarNMReserved4 255;
BA_ "U_V710_MY2023_Tx" SG_ 1439 WCM_AutoSarNMReserved3 1;
BA_ "U_P708_MY2023_Tx" SG_ 1439 WCM_AutoSarNMReserved3 1;
BA_ "U_V713N_MY2022_Tx" SG_ 1439 WCM_AutoSarNMReserved3 1;
BA_ "U_P708_MY2023_Rx" SG_ 1439 WCM_AutoSarNMReserved3 1;
BA_ "U_V710_MY2023_Rx" SG_ 1439 WCM_AutoSarNMReserved3 1;
BA_ "GenSigStartValue" SG_ 1439 WCM_AutoSarNMReserved3 255;
BA_ "U_V710_MY2023_Tx" SG_ 1439 WCM_AutoSarNMReserved2 1;
BA_ "U_P708_MY2023_Tx" SG_ 1439 WCM_AutoSarNMReserved2 1;
BA_ "U_V713N_MY2022_Tx" SG_ 1439 WCM_AutoSarNMReserved2 1;
BA_ "U_P708_MY2023_Rx" SG_ 1439 WCM_AutoSarNMReserved2 1;
BA_ "U_V710_MY2023_Rx" SG_ 1439 WCM_AutoSarNMReserved2 1;
BA_ "GenSigStartValue" SG_ 1439 WCM_AutoSarNMReserved2 255;
BA_ "U_V710_MY2023_Tx" SG_ 1439 WCM_AutoSarNMReserved1 1;
BA_ "U_P708_MY2023_Tx" SG_ 1439 WCM_AutoSarNMReserved1 1;
BA_ "U_V713N_MY2022_Tx" SG_ 1439 WCM_AutoSarNMReserved1 1;
BA_ "U_P708_MY2023_Rx" SG_ 1439 WCM_AutoSarNMReserved1 1;
BA_ "U_V710_MY2023_Rx" SG_ 1439 WCM_AutoSarNMReserved1 1;
BA_ "GenSigStartValue" SG_ 1439 WCM_AutoSarNMReserved1 255;
BA_ "U_V710_MY2023_Tx" SG_ 1439 WCM_AutoSarNMNodeId 1;
BA_ "U_P708_MY2023_Tx" SG_ 1439 WCM_AutoSarNMNodeId 1;
BA_ "U_V713N_MY2022_Tx" SG_ 1439 WCM_AutoSarNMNodeId 1;
BA_ "U_V710_MY2023_Rx" SG_ 1439 WCM_AutoSarNMNodeId 1;
BA_ "U_P708_MY2023_Rx" SG_ 1439 WCM_AutoSarNMNodeId 1;
BA_ "GenSigStartValue" SG_ 1439 WCM_AutoSarNMNodeId 159;
BA_ "U_V710_MY2023_Tx" SG_ 1439 WCM_AutoSarNMControl 1;
BA_ "U_P708_MY2023_Tx" SG_ 1439 WCM_AutoSarNMControl 1;
BA_ "U_V713N_MY2022_Tx" SG_ 1439 WCM_AutoSarNMControl 1;
BA_ "U_V710_MY2023_Rx" SG_ 1439 WCM_AutoSarNMControl 1;
BA_ "U_P708_MY2023_Rx" SG_ 1439 WCM_AutoSarNMControl 1;
BA_ "U_P708_MY2023_Tx" SG_ 261 ChrgStatDsply_D_Rq 1;
BA_ "U_V713AV_MY2022_Tx" SG_ 261 ChrgStatDsply_D_Rq 1;
BA_ "U_V713N_MY2022_Tx" SG_ 261 ChrgStatDsply_D_Rq 1;
BA_ "GenSigSendType" SG_ 261 ChrgStatDsply_D_Rq 3;
BA_ "GenSigStartValue" SG_ 261 ChrgStatDsply_D_Rq 1;
BA_ "U_P708_MY2023_Tx" SG_ 261 OffPeakTimeSetMin_Rq 1;
BA_ "U_V713AV_MY2022_Tx" SG_ 261 OffPeakTimeSetMin_Rq 1;
BA_ "U_V713N_MY2022_Tx" SG_ 261 OffPeakTimeSetMin_Rq 1;
BA_ "GenSigSendType" SG_ 261 OffPeakTimeSetMin_Rq 3;
BA_ "U_P708_MY2023_Tx" SG_ 261 OffPeakTimeSetHR_Rq 1;
BA_ "U_V713AV_MY2022_Tx" SG_ 261 OffPeakTimeSetHR_Rq 1;
BA_ "U_V713N_MY2022_Tx" SG_ 261 OffPeakTimeSetHR_Rq 1;
BA_ "GenSigSendType" SG_ 261 OffPeakTimeSetHR_Rq 3;
BA_ "U_P708_MY2023_Tx" SG_ 261 NextUsageTimeToggle_Rq 1;
BA_ "U_V713AV_MY2022_Tx" SG_ 261 NextUsageTimeToggle_Rq 1;
BA_ "U_V713N_MY2022_Tx" SG_ 261 NextUsageTimeToggle_Rq 1;
BA_ "GenSigSendType" SG_ 261 NextUsageTimeToggle_Rq 3;
BA_ "U_P708_MY2023_Tx" SG_ 261 LongTermParking_Rq 1;
BA_ "U_V713AV_MY2022_Tx" SG_ 261 LongTermParking_Rq 1;
BA_ "U_V713N_MY2022_Tx" SG_ 261 LongTermParking_Rq 1;
BA_ "GenSigSendType" SG_ 261 LongTermParking_Rq 3;
BA_ "U_P708_MY2023_Tx" SG_ 261 CbnCmrtPrefLstNmItm_Rq 1;
BA_ "U_V713AV_MY2022_Tx" SG_ 261 CbnCmrtPrefLstNmItm_Rq 1;
BA_ "U_V713N_MY2022_Tx" SG_ 261 CbnCmrtPrefLstNmItm_Rq 1;
BA_ "GenSigSendType" SG_ 261 CbnCmrtPrefLstNmItm_Rq 3;
BA_ "U_P708_MY2023_Tx" SG_ 261 CbnCmrtPrefListIndx_Rq 1;
BA_ "U_V713AV_MY2022_Tx" SG_ 261 CbnCmrtPrefListIndx_Rq 1;
BA_ "U_V713N_MY2022_Tx" SG_ 261 CbnCmrtPrefListIndx_Rq 1;
BA_ "GenSigSendType" SG_ 261 CbnCmrtPrefListIndx_Rq 3;
BA_ "U_P708_MY2023_Tx" SG_ 261 ModemReset_D_Rq 1;
BA_ "U_V713AV_MY2022_Tx" SG_ 261 ModemReset_D_Rq 1;
BA_ "U_V713N_MY2022_Tx" SG_ 261 ModemReset_D_Rq 1;
BA_ "U_V710_MY2023_Rx" SG_ 261 ModemReset_D_Rq 1;
BA_ "U_P708_MY2023_Rx" SG_ 261 ModemReset_D_Rq 1;
BA_ "U_V713AV_MY2022_Rx" SG_ 261 ModemReset_D_Rq 1;
BA_ "U_V713N_MY2022_Rx" SG_ 261 ModemReset_D_Rq 1;
BA_ "ECGUsedRxSignal" SG_ 261 ModemReset_D_Rq 1;
BA_ "GenSigSendType" SG_ 261 ModemReset_D_Rq 3;
BA_ "U_P708_MY2023_Tx" SG_ 261 StopStrtDrvMde_B_RqBtn3 1;
BA_ "U_V713AV_MY2022_Tx" SG_ 261 StopStrtDrvMde_B_RqBtn3 1;
BA_ "U_V713N_MY2022_Tx" SG_ 261 StopStrtDrvMde_B_RqBtn3 1;
BA_ "GenSigSendType" SG_ 261 StopStrtDrvMde_B_RqBtn3 3;
BA_ "U_P708_MY2023_Tx" SG_ 261 AudioToneTouchY_D_Rq 1;
BA_ "U_V713AV_MY2022_Tx" SG_ 261 AudioToneTouchY_D_Rq 1;
BA_ "U_V713N_MY2022_Tx" SG_ 261 AudioToneTouchY_D_Rq 1;
BA_ "GenSigSendType" SG_ 261 AudioToneTouchY_D_Rq 3;
BA_ "U_P708_MY2023_Tx" SG_ 261 AudioToneTouchX_D_Rq 1;
BA_ "U_V713AV_MY2022_Tx" SG_ 261 AudioToneTouchX_D_Rq 1;
BA_ "U_V713N_MY2022_Tx" SG_ 261 AudioToneTouchX_D_Rq 1;
BA_ "GenSigSendType" SG_ 261 AudioToneTouchX_D_Rq 3;
BA_ "U_P708_MY2023_Tx" SG_ 261 TCU_ESN_D_Rq 1;
BA_ "U_V713AV_MY2022_Tx" SG_ 261 TCU_ESN_D_Rq 1;
BA_ "U_V713N_MY2022_Tx" SG_ 261 TCU_ESN_D_Rq 1;
BA_ "GenSigSendType" SG_ 261 TCU_ESN_D_Rq 3;
BA_ "U_P708_MY2023_Tx" SG_ 261 FactoryReset_Rq 1;
BA_ "U_V713AV_MY2022_Tx" SG_ 261 FactoryReset_Rq 1;
BA_ "U_V713N_MY2022_Tx" SG_ 261 FactoryReset_Rq 1;
BA_ "U_V710_MY2023_Rx" SG_ 261 FactoryReset_Rq 1;
BA_ "U_P708_MY2023_Rx" SG_ 261 FactoryReset_Rq 1;
BA_ "U_V713AV_MY2022_Rx" SG_ 261 FactoryReset_Rq 1;
BA_ "U_V713N_MY2022_Rx" SG_ 261 FactoryReset_Rq 1;
BA_ "ECGUsedRxSignal" SG_ 261 FactoryReset_Rq 1;
BA_ "GenSigSendType" SG_ 261 FactoryReset_Rq 3;
BA_ "U_P708_MY2023_Tx" SG_ 261 OffPeakTimeSetType_Rq 1;
BA_ "U_V713AV_MY2022_Tx" SG_ 261 OffPeakTimeSetType_Rq 1;
BA_ "U_V713N_MY2022_Tx" SG_ 261 OffPeakTimeSetType_Rq 1;
BA_ "GenSigSendType" SG_ 261 OffPeakTimeSetType_Rq 3;
BA_ "U_P708_MY2023_Tx" SG_ 261 AudioToneTouch_D_Rq 1;
BA_ "U_V713AV_MY2022_Tx" SG_ 261 AudioToneTouch_D_Rq 1;
BA_ "U_V713N_MY2022_Tx" SG_ 261 AudioToneTouch_D_Rq 1;
BA_ "GenSigSendType" SG_ 261 AudioToneTouch_D_Rq 3;
BA_ "U_V710_MY2023_Rx" SG_ 995 KeyAssocCmplt_B_Rq 1;
BA_ "U_P708_MY2023_Rx" SG_ 995 KeyAssocCmplt_B_Rq 1;
BA_ "U_V713AV_MY2022_Rx" SG_ 995 KeyAssocCmplt_B_Rq 1;
BA_ "U_V713N_MY2022_Rx" SG_ 995 KeyAssocCmplt_B_Rq 1;
BA_ "U_P708_MY2023_Rx" SG_ 995 FobAssocChime_B_Rq 1;
BA_ "U_V713AV_MY2022_Rx" SG_ 995 FobAssocChime_B_Rq 1;
BA_ "U_V713N_MY2022_Rx" SG_ 995 FobAssocChime_B_Rq 1;
BA_ "U_V710_MY2023_Rx" SG_ 995 PersIndexBcm_D_Actl 1;
BA_ "U_P708_MY2023_Rx" SG_ 995 PersIndexBcm_D_Actl 1;
BA_ "U_V713AV_MY2022_Rx" SG_ 995 PersIndexBcm_D_Actl 1;
BA_ "U_V713N_MY2022_Rx" SG_ 995 PersIndexBcm_D_Actl 1;
BA_ "GenSigStartValue" SG_ 995 PersIndexBcm_D_Actl 4;
BA_ "U_V710_MY2023_Rx" SG_ 995 FeatNoBcm_No_Actl 1;
BA_ "U_P708_MY2023_Rx" SG_ 995 FeatNoBcm_No_Actl 1;
BA_ "U_V713AV_MY2022_Rx" SG_ 995 FeatNoBcm_No_Actl 1;
BA_ "U_V713N_MY2022_Rx" SG_ 995 FeatNoBcm_No_Actl 1;
BA_ "U_V710_MY2023_Rx" SG_ 995 FeatConfigBcmActl 1;
BA_ "U_P708_MY2023_Rx" SG_ 995 FeatConfigBcmActl 1;
BA_ "U_V713AV_MY2022_Rx" SG_ 995 FeatConfigBcmActl 1;
BA_ "U_V713N_MY2022_Rx" SG_ 995 FeatConfigBcmActl 1;
BA_ "GenSigSendType" SG_ 753 RollCodeValet 3;
BA_ "U_V710_MY2023_Tx" SG_ 1000 AHU_Bezel_Diag_St 1;
BA_ "U_P708_MY2023_Tx" SG_ 1000 AHU_Bezel_Diag_St 1;
BA_ "U_V713AV_MY2022_Tx" SG_ 1000 AHU_Bezel_Diag_St 1;
BA_ "U_V713N_MY2022_Tx" SG_ 1000 AHU_Bezel_Diag_St 1;
BA_ "GenSigSendType" SG_ 1000 AHU_Bezel_Diag_St 3;
BA_ "U_V710_MY2023_Tx" SG_ 1000 ThermalReduction_St 1;
BA_ "U_P708_MY2023_Tx" SG_ 1000 ThermalReduction_St 1;
BA_ "U_V713AV_MY2022_Tx" SG_ 1000 ThermalReduction_St 1;
BA_ "U_V713N_MY2022_Tx" SG_ 1000 ThermalReduction_St 1;
BA_ "GenSigSendType" SG_ 1000 ThermalReduction_St 3;
BA_ "U_V710_MY2023_Tx" SG_ 1000 AHU_Shaker_St 1;
BA_ "U_P708_MY2023_Tx" SG_ 1000 AHU_Shaker_St 1;
BA_ "U_V713AV_MY2022_Tx" SG_ 1000 AHU_Shaker_St 1;
BA_ "U_V713N_MY2022_Tx" SG_ 1000 AHU_Shaker_St 1;
BA_ "GenSigSendType" SG_ 1000 AHU_Shaker_St 3;
BA_ "U_V710_MY2023_Tx" SG_ 1000 ACM_BeltminderAudioSt 1;
BA_ "U_P708_MY2023_Tx" SG_ 1000 ACM_BeltminderAudioSt 1;
BA_ "U_V713AV_MY2022_Tx" SG_ 1000 ACM_BeltminderAudioSt 1;
BA_ "U_V713N_MY2022_Tx" SG_ 1000 ACM_BeltminderAudioSt 1;
BA_ "GenSigSendType" SG_ 1000 ACM_BeltminderAudioSt 3;
BA_ "U_V710_MY2023_Tx" SG_ 1000 MyKeyVolumeLimitUp 1;
BA_ "U_P708_MY2023_Tx" SG_ 1000 MyKeyVolumeLimitUp 1;
BA_ "U_V713AV_MY2022_Tx" SG_ 1000 MyKeyVolumeLimitUp 1;
BA_ "U_V713N_MY2022_Tx" SG_ 1000 MyKeyVolumeLimitUp 1;
BA_ "GenSigSendType" SG_ 1000 MyKeyVolumeLimitUp 3;
BA_ "U_V710_MY2023_Tx" SG_ 1000 MyKeyVolumeLimitMode 1;
BA_ "U_P708_MY2023_Tx" SG_ 1000 MyKeyVolumeLimitMode 1;
BA_ "U_V713AV_MY2022_Tx" SG_ 1000 MyKeyVolumeLimitMode 1;
BA_ "U_V713N_MY2022_Tx" SG_ 1000 MyKeyVolumeLimitMode 1;
BA_ "GenSigSendType" SG_ 1000 MyKeyVolumeLimitMode 3;
BA_ "U_V710_MY2023_Tx" SG_ 992 MsgCntrPersIndex_D_Rq 1;
BA_ "U_P708_MY2023_Tx" SG_ 992 MsgCntrPersIndex_D_Rq 1;
BA_ "U_V713AV_MY2022_Tx" SG_ 992 MsgCntrPersIndex_D_Rq 1;
BA_ "U_V713N_MY2022_Tx" SG_ 992 MsgCntrPersIndex_D_Rq 1;
BA_ "U_P708_MY2023_Rx" SG_ 992 MsgCntrPersIndex_D_Rq 1;
BA_ "GenSigSendType" SG_ 992 MsgCntrPersIndex_D_Rq 3;
BA_ "GenSigStartValue" SG_ 992 MsgCntrPersIndex_D_Rq 4;
BA_ "U_V710_MY2023_Tx" SG_ 992 MsgCntrFeatConfigRq 1;
BA_ "U_P708_MY2023_Tx" SG_ 992 MsgCntrFeatConfigRq 1;
BA_ "U_V713AV_MY2022_Tx" SG_ 992 MsgCntrFeatConfigRq 1;
BA_ "U_V713N_MY2022_Tx" SG_ 992 MsgCntrFeatConfigRq 1;
BA_ "U_P708_MY2023_Rx" SG_ 992 MsgCntrFeatConfigRq 1;
BA_ "GenSigSendType" SG_ 992 MsgCntrFeatConfigRq 3;
BA_ "U_V710_MY2023_Tx" SG_ 992 MsgCntrFeatNoRq 1;
BA_ "U_P708_MY2023_Tx" SG_ 992 MsgCntrFeatNoRq 1;
BA_ "U_V713AV_MY2022_Tx" SG_ 992 MsgCntrFeatNoRq 1;
BA_ "U_V713N_MY2022_Tx" SG_ 992 MsgCntrFeatNoRq 1;
BA_ "U_P708_MY2023_Rx" SG_ 992 MsgCntrFeatNoRq 1;
BA_ "GenSigSendType" SG_ 992 MsgCntrFeatNoRq 3;
BA_ "U_V710_MY2023_Tx" SG_ 992 MsgCntrDsplyOp_D_Rq 1;
BA_ "U_P708_MY2023_Tx" SG_ 992 MsgCntrDsplyOp_D_Rq 1;
BA_ "U_V713AV_MY2022_Tx" SG_ 992 MsgCntrDsplyOp_D_Rq 1;
BA_ "U_V713N_MY2022_Tx" SG_ 992 MsgCntrDsplyOp_D_Rq 1;
BA_ "U_P708_MY2023_Rx" SG_ 992 MsgCntrDsplyOp_D_Rq 1;
BA_ "GenSigSendType" SG_ 992 MsgCntrDsplyOp_D_Rq 3;
BA_ "GenSigStartValue" SG_ 991 TrlrTngLoad_D_Stat 6;
BA_ "GenSigStartValue" SG_ 991 Trlr_M_Actl 2046;
BA_ "U_V713AV_MY2022_Rx" SG_ 991 PersIndexVdm_D_Actl 1;
BA_ "U_V713N_MY2022_Rx" SG_ 991 PersIndexVdm_D_Actl 1;
BA_ "GenSigStartValue" SG_ 991 PersIndexVdm_D_Actl 4;
BA_ "U_V713AV_MY2022_Rx" SG_ 991 FeatNoVdmActl 1;
BA_ "U_V713N_MY2022_Rx" SG_ 991 FeatNoVdmActl 1;
BA_ "U_V713AV_MY2022_Rx" SG_ 991 FeatConfigVdmActl 1;
BA_ "U_V713N_MY2022_Rx" SG_ 991 FeatConfigVdmActl 1;
BA_ "U_V713AV_MY2022_Rx" SG_ 1004 VehKeyActv_D_Stat 1;
BA_ "U_V713N_MY2022_Rx" SG_ 1004 VehKeyActv_D_Stat 1;
BA_ "GenSigStartValue" SG_ 1004 PersConflict_D_Actl 1;
BA_ "U_V710_MY2023_Rx" SG_ 1004 RecallEvent_No_Cnt 1;
BA_ "U_V713AV_MY2022_Rx" SG_ 1004 RecallEvent_No_Cnt 1;
BA_ "U_V713N_MY2022_Rx" SG_ 1004 RecallEvent_No_Cnt 1;
BA_ "U_P708_MY2023_Rx" SG_ 1004 RecallEvent_No_Cnt 1;
BA_ "MetaData" SG_ 1004 RecallEvent_No_Cnt 1;
BA_ "U_V713AV_MY2022_Rx" SG_ 1004 PersNoPos_D_Actl 1;
BA_ "U_V713N_MY2022_Rx" SG_ 1004 PersNoPos_D_Actl 1;
BA_ "GenSigStartValue" SG_ 1004 PersNoPos_D_Actl 4;
BA_ "U_V710_MY2023_Rx" SG_ 1004 PersNo_D_Actl 1;
BA_ "U_P708_MY2023_Rx" SG_ 1004 PersNo_D_Actl 1;
BA_ "U_V713AV_MY2022_Rx" SG_ 1004 PersNo_D_Actl 1;
BA_ "U_V713N_MY2022_Rx" SG_ 1004 PersNo_D_Actl 1;
BA_ "GenSigStartValue" SG_ 1004 PersNo_D_Actl 4;
BA_ "U_V710_MY2023_Rx" SG_ 1478 DSP_GWOnBoardTester 1;
BA_ "U_P708_MY2023_Rx" SG_ 1478 DSP_GWOnBoardTester 1;
BA_ "GenSigStartValue" SG_ 1478 DSP_GWOnBoardTester 255;
BA_ "U_V710_MY2023_Rx" SG_ 1478 DSP_GWNMProxy 1;
BA_ "U_P708_MY2023_Rx" SG_ 1478 DSP_GWNMProxy 1;
BA_ "GenSigStartValue" SG_ 1478 DSP_GWNMProxy 255;
BA_ "U_V710_MY2023_Rx" SG_ 1478 DSP_AutoSarNMReserved4 1;
BA_ "U_P708_MY2023_Rx" SG_ 1478 DSP_AutoSarNMReserved4 1;
BA_ "GenSigStartValue" SG_ 1478 DSP_AutoSarNMReserved4 255;
BA_ "U_V710_MY2023_Rx" SG_ 1478 DSP_AutoSarNMReserved3 1;
BA_ "U_P708_MY2023_Rx" SG_ 1478 DSP_AutoSarNMReserved3 1;
BA_ "GenSigStartValue" SG_ 1478 DSP_AutoSarNMReserved3 255;
BA_ "U_V710_MY2023_Rx" SG_ 1478 DSP_AutoSarNMReserved2 1;
BA_ "U_P708_MY2023_Rx" SG_ 1478 DSP_AutoSarNMReserved2 1;
BA_ "GenSigStartValue" SG_ 1478 DSP_AutoSarNMReserved2 255;
BA_ "U_V710_MY2023_Rx" SG_ 1478 DSP_AutoSarNMReserved1 1;
BA_ "U_P708_MY2023_Rx" SG_ 1478 DSP_AutoSarNMReserved1 1;
BA_ "GenSigStartValue" SG_ 1478 DSP_AutoSarNMReserved1 255;
BA_ "U_V710_MY2023_Rx" SG_ 1478 DSP_AutoSarNMNodeId 1;
BA_ "U_P708_MY2023_Rx" SG_ 1478 DSP_AutoSarNMNodeId 1;
BA_ "GenSigStartValue" SG_ 1478 DSP_AutoSarNMNodeId 198;
BA_ "U_V710_MY2023_Rx" SG_ 1478 DSP_AutoSarNMControl 1;
BA_ "U_P708_MY2023_Rx" SG_ 1478 DSP_AutoSarNMControl 1;
BA_ "U_P708_MY2023_Tx" SG_ 813 TimerTripCurnt_T_Dsply 1;
BA_ "GenSigSendType" SG_ 813 TimerTripCurnt_T_Dsply 3;
BA_ "U_V710_MY2023_Tx" SG_ 807 ElDistTripUnit_D_Stat 1;
BA_ "U_P708_MY2023_Tx" SG_ 807 ElDistTripUnit_D_Stat 1;
BA_ "GenSigSendType" SG_ 807 ElDistTripUnit_D_Stat 3;
BA_ "U_V710_MY2023_Tx" SG_ 807 ElDistTrip2_No_Dsply 1;
BA_ "U_P708_MY2023_Tx" SG_ 807 ElDistTrip2_No_Dsply 1;
BA_ "GenSigSendType" SG_ 807 ElDistTrip2_No_Dsply 3;
BA_ "U_V710_MY2023_Tx" SG_ 807 ElDistTrip1_No_Dsply 1;
BA_ "U_P708_MY2023_Tx" SG_ 807 ElDistTrip1_No_Dsply 1;
BA_ "GenSigSendType" SG_ 807 ElDistTrip1_No_Dsply 3;
BA_ "U_P708_MY2023_Tx" SG_ 807 ElDistTripCur_No_Dsply 1;
BA_ "GenSigSendType" SG_ 807 ElDistTripCur_No_Dsply 3;
BA_ "U_P708_MY2023_Tx" SG_ 584 AUDIO_RDISP2_WORD_Rx 1;
BA_ "U_V710_MY2023_Rx" SG_ 584 AUDIO_RDISP2_WORD_Rx 1;
BA_ "U_P708_MY2023_Rx" SG_ 584 AUDIO_RDISP2_WORD_Rx 1;
BA_ "U_V713AV_MY2022_Rx" SG_ 584 AUDIO_RDISP2_WORD_Rx 1;
BA_ "U_V713N_MY2022_Rx" SG_ 584 AUDIO_RDISP2_WORD_Rx 1;
BA_ "GenSigStartValue" SG_ 1052 AwdCnnct_D_Stat 1;
BA_ "U_V713AV_MY2022_Rx" SG_ 1052 AwdLck_Tq_Actl 1;
BA_ "U_V713N_MY2022_Rx" SG_ 1052 AwdLck_Tq_Actl 1;
BA_ "U_V710_MY2023_Tx" SG_ 754 ACU_ActChimeTypeDat_St 1;
BA_ "U_P708_MY2023_Tx" SG_ 754 ACU_ActChimeTypeDat_St 1;
BA_ "U_V713AV_MY2022_Tx" SG_ 754 ACU_ActChimeTypeDat_St 1;
BA_ "U_V713N_MY2022_Tx" SG_ 754 ACU_ActChimeTypeDat_St 1;
BA_ "U_V710_MY2023_Tx" SG_ 754 ACU_ActChimeType_St 1;
BA_ "U_P708_MY2023_Tx" SG_ 754 ACU_ActChimeType_St 1;
BA_ "U_V713AV_MY2022_Tx" SG_ 754 ACU_ActChimeType_St 1;
BA_ "U_V713N_MY2022_Tx" SG_ 754 ACU_ActChimeType_St 1;
BA_ "GenSigSendType" SG_ 754 ACU_ActChimeType_St 3;
BA_ "U_V710_MY2023_Tx" SG_ 729 ACU_VoiceFBVolume_Up 1;
BA_ "U_P708_MY2023_Tx" SG_ 729 ACU_VoiceFBVolume_Up 1;
BA_ "U_V713AV_MY2022_Tx" SG_ 729 ACU_VoiceFBVolume_Up 1;
BA_ "U_V713N_MY2022_Tx" SG_ 729 ACU_VoiceFBVolume_Up 1;
BA_ "U_V713AV_MY2022_Rx" SG_ 729 ACU_VoiceFBVolume_Up 1;
BA_ "U_V713N_MY2022_Rx" SG_ 729 ACU_VoiceFBVolume_Up 1;
BA_ "GenSigSendType" SG_ 729 ACU_VoiceFBVolume_Up 3;
BA_ "U_V710_MY2023_Tx" SG_ 729 ACU_VoiceFBVolume_St 1;
BA_ "U_P708_MY2023_Tx" SG_ 729 ACU_VoiceFBVolume_St 1;
BA_ "U_V713AV_MY2022_Tx" SG_ 729 ACU_VoiceFBVolume_St 1;
BA_ "U_V713N_MY2022_Tx" SG_ 729 ACU_VoiceFBVolume_St 1;
BA_ "U_P708_MY2023_Rx" SG_ 729 ACU_VoiceFBVolume_St 1;
BA_ "U_V713AV_MY2022_Rx" SG_ 729 ACU_VoiceFBVolume_St 1;
BA_ "U_V713N_MY2022_Rx" SG_ 729 ACU_VoiceFBVolume_St 1;
BA_ "GenSigSendType" SG_ 729 ACU_VoiceFBVolume_St 3;
BA_ "U_V710_MY2023_Tx" SG_ 729 ACU_Treble_St 1;
BA_ "U_P708_MY2023_Tx" SG_ 729 ACU_Treble_St 1;
BA_ "U_V713AV_MY2022_Tx" SG_ 729 ACU_Treble_St 1;
BA_ "U_V713N_MY2022_Tx" SG_ 729 ACU_Treble_St 1;
BA_ "U_V713AV_MY2022_Rx" SG_ 729 ACU_Treble_St 1;
BA_ "U_V713N_MY2022_Rx" SG_ 729 ACU_Treble_St 1;
BA_ "GenSigSendType" SG_ 729 ACU_Treble_St 3;
BA_ "U_V710_MY2023_Tx" SG_ 729 ACU_TAVolume_Up 1;
BA_ "U_P708_MY2023_Tx" SG_ 729 ACU_TAVolume_Up 1;
BA_ "U_V713AV_MY2022_Tx" SG_ 729 ACU_TAVolume_Up 1;
BA_ "U_V713N_MY2022_Tx" SG_ 729 ACU_TAVolume_Up 1;
BA_ "U_V713AV_MY2022_Rx" SG_ 729 ACU_TAVolume_Up 1;
BA_ "U_V713N_MY2022_Rx" SG_ 729 ACU_TAVolume_Up 1;
BA_ "GenSigSendType" SG_ 729 ACU_TAVolume_Up 3;
BA_ "U_V710_MY2023_Tx" SG_ 729 ACU_TAVolume_St 1;
BA_ "U_P708_MY2023_Tx" SG_ 729 ACU_TAVolume_St 1;
BA_ "U_V713AV_MY2022_Tx" SG_ 729 ACU_TAVolume_St 1;
BA_ "U_V713N_MY2022_Tx" SG_ 729 ACU_TAVolume_St 1;
BA_ "U_P708_MY2023_Rx" SG_ 729 ACU_TAVolume_St 1;
BA_ "U_V713AV_MY2022_Rx" SG_ 729 ACU_TAVolume_St 1;
BA_ "U_V713N_MY2022_Rx" SG_ 729 ACU_TAVolume_St 1;
BA_ "GenSigSendType" SG_ 729 ACU_TAVolume_St 3;
BA_ "U_V710_MY2023_Tx" SG_ 729 ACU_Reg_St 1;
BA_ "U_P708_MY2023_Tx" SG_ 729 ACU_Reg_St 1;
BA_ "U_V713AV_MY2022_Tx" SG_ 729 ACU_Reg_St 1;
BA_ "U_V713N_MY2022_Tx" SG_ 729 ACU_Reg_St 1;
BA_ "GenSigSendType" SG_ 729 ACU_Reg_St 3;
BA_ "U_V710_MY2023_Tx" SG_ 729 ACU_PhoneVolume_Up 1;
BA_ "U_P708_MY2023_Tx" SG_ 729 ACU_PhoneVolume_Up 1;
BA_ "U_V713AV_MY2022_Tx" SG_ 729 ACU_PhoneVolume_Up 1;
BA_ "U_V713N_MY2022_Tx" SG_ 729 ACU_PhoneVolume_Up 1;
BA_ "U_V713AV_MY2022_Rx" SG_ 729 ACU_PhoneVolume_Up 1;
BA_ "U_V713N_MY2022_Rx" SG_ 729 ACU_PhoneVolume_Up 1;
BA_ "GenSigSendType" SG_ 729 ACU_PhoneVolume_Up 3;
BA_ "U_V710_MY2023_Tx" SG_ 729 ACU_PhoneVolume_St 1;
BA_ "U_P708_MY2023_Tx" SG_ 729 ACU_PhoneVolume_St 1;
BA_ "U_V713AV_MY2022_Tx" SG_ 729 ACU_PhoneVolume_St 1;
BA_ "U_V713N_MY2022_Tx" SG_ 729 ACU_PhoneVolume_St 1;
BA_ "U_P708_MY2023_Rx" SG_ 729 ACU_PhoneVolume_St 1;
BA_ "U_V713AV_MY2022_Rx" SG_ 729 ACU_PhoneVolume_St 1;
BA_ "U_V713N_MY2022_Rx" SG_ 729 ACU_PhoneVolume_St 1;
BA_ "GenSigSendType" SG_ 729 ACU_PhoneVolume_St 3;
BA_ "U_V710_MY2023_Tx" SG_ 729 ACU_NavCmdVolume_Up 1;
BA_ "U_P708_MY2023_Tx" SG_ 729 ACU_NavCmdVolume_Up 1;
BA_ "U_V713AV_MY2022_Tx" SG_ 729 ACU_NavCmdVolume_Up 1;
BA_ "U_V713N_MY2022_Tx" SG_ 729 ACU_NavCmdVolume_Up 1;
BA_ "U_V713AV_MY2022_Rx" SG_ 729 ACU_NavCmdVolume_Up 1;
BA_ "U_V713N_MY2022_Rx" SG_ 729 ACU_NavCmdVolume_Up 1;
BA_ "GenSigSendType" SG_ 729 ACU_NavCmdVolume_Up 3;
BA_ "U_V710_MY2023_Tx" SG_ 729 ACU_NavCmdVolume_St 1;
BA_ "U_P708_MY2023_Tx" SG_ 729 ACU_NavCmdVolume_St 1;
BA_ "U_V713AV_MY2022_Tx" SG_ 729 ACU_NavCmdVolume_St 1;
BA_ "U_V713N_MY2022_Tx" SG_ 729 ACU_NavCmdVolume_St 1;
BA_ "U_P708_MY2023_Rx" SG_ 729 ACU_NavCmdVolume_St 1;
BA_ "U_V713AV_MY2022_Rx" SG_ 729 ACU_NavCmdVolume_St 1;
BA_ "U_V713N_MY2022_Rx" SG_ 729 ACU_NavCmdVolume_St 1;
BA_ "GenSigSendType" SG_ 729 ACU_NavCmdVolume_St 3;
BA_ "U_V710_MY2023_Tx" SG_ 729 ACU_Fader_St 1;
BA_ "U_P708_MY2023_Tx" SG_ 729 ACU_Fader_St 1;
BA_ "U_V713AV_MY2022_Tx" SG_ 729 ACU_Fader_St 1;
BA_ "U_V713N_MY2022_Tx" SG_ 729 ACU_Fader_St 1;
BA_ "U_V713AV_MY2022_Rx" SG_ 729 ACU_Fader_St 1;
BA_ "U_V713N_MY2022_Rx" SG_ 729 ACU_Fader_St 1;
BA_ "GenSigSendType" SG_ 729 ACU_Fader_St 3;
BA_ "U_V710_MY2023_Tx" SG_ 729 ACU_DSPProgram_St 1;
BA_ "U_P708_MY2023_Tx" SG_ 729 ACU_DSPProgram_St 1;
BA_ "U_V713AV_MY2022_Tx" SG_ 729 ACU_DSPProgram_St 1;
BA_ "U_V713N_MY2022_Tx" SG_ 729 ACU_DSPProgram_St 1;
BA_ "GenSigSendType" SG_ 729 ACU_DSPProgram_St 3;
BA_ "U_V710_MY2023_Tx" SG_ 729 ACU_DSP_St 1;
BA_ "U_P708_MY2023_Tx" SG_ 729 ACU_DSP_St 1;
BA_ "U_V713AV_MY2022_Tx" SG_ 729 ACU_DSP_St 1;
BA_ "U_V713N_MY2022_Tx" SG_ 729 ACU_DSP_St 1;
BA_ "GenSigSendType" SG_ 729 ACU_DSP_St 3;
BA_ "U_V710_MY2023_Tx" SG_ 729 ACU_Bass_St 1;
BA_ "U_P708_MY2023_Tx" SG_ 729 ACU_Bass_St 1;
BA_ "U_V713AV_MY2022_Tx" SG_ 729 ACU_Bass_St 1;
BA_ "U_V713N_MY2022_Tx" SG_ 729 ACU_Bass_St 1;
BA_ "GenSigSendType" SG_ 729 ACU_Bass_St 3;
BA_ "U_V710_MY2023_Tx" SG_ 729 ACU_Balance_St 1;
BA_ "U_P708_MY2023_Tx" SG_ 729 ACU_Balance_St 1;
BA_ "U_V713AV_MY2022_Tx" SG_ 729 ACU_Balance_St 1;
BA_ "U_V713N_MY2022_Tx" SG_ 729 ACU_Balance_St 1;
BA_ "GenSigSendType" SG_ 729 ACU_Balance_St 3;
BA_ "U_V710_MY2023_Tx" SG_ 729 ACU_AVC_St 1;
BA_ "U_P708_MY2023_Tx" SG_ 729 ACU_AVC_St 1;
BA_ "U_V713AV_MY2022_Tx" SG_ 729 ACU_AVC_St 1;
BA_ "U_V713N_MY2022_Tx" SG_ 729 ACU_AVC_St 1;
BA_ "GenSigSendType" SG_ 729 ACU_AVC_St 3;
BA_ "U_V710_MY2023_Tx" SG_ 727 ACU_LoadEjectMode_St 1;
BA_ "U_V713AV_MY2022_Tx" SG_ 727 ACU_LoadEjectMode_St 1;
BA_ "U_V713N_MY2022_Tx" SG_ 727 ACU_LoadEjectMode_St 1;
BA_ "GenSigSendType" SG_ 727 ACU_LoadEjectMode_St 3;
BA_ "U_V710_MY2023_Tx" SG_ 727 ACU_LoadEjectDisc_St 1;
BA_ "U_V713AV_MY2022_Tx" SG_ 727 ACU_LoadEjectDisc_St 1;
BA_ "U_V713N_MY2022_Tx" SG_ 727 ACU_LoadEjectDisc_St 1;
BA_ "U_V710_MY2023_Tx" SG_ 726 ACU_SelectedPTYCodes_St 1;
BA_ "U_P708_MY2023_Tx" SG_ 726 ACU_SelectedPTYCodes_St 1;
BA_ "U_V713AV_MY2022_Tx" SG_ 726 ACU_SelectedPTYCodes_St 1;
BA_ "U_V713N_MY2022_Tx" SG_ 726 ACU_SelectedPTYCodes_St 1;
BA_ "GenSigSendType" SG_ 726 ACU_SelectedPTYCodes_St 3;
BA_ "U_V710_MY2023_Tx" SG_ 726 ACU_TAMode_St 1;
BA_ "U_P708_MY2023_Tx" SG_ 726 ACU_TAMode_St 1;
BA_ "U_V713AV_MY2022_Tx" SG_ 726 ACU_TAMode_St 1;
BA_ "U_V713N_MY2022_Tx" SG_ 726 ACU_TAMode_St 1;
BA_ "GenSigSendType" SG_ 726 ACU_TAMode_St 3;
BA_ "U_V710_MY2023_Tx" SG_ 726 ACU_NEWSMode_St 1;
BA_ "U_P708_MY2023_Tx" SG_ 726 ACU_NEWSMode_St 1;
BA_ "U_V713AV_MY2022_Tx" SG_ 726 ACU_NEWSMode_St 1;
BA_ "U_V713N_MY2022_Tx" SG_ 726 ACU_NEWSMode_St 1;
BA_ "GenSigSendType" SG_ 726 ACU_NEWSMode_St 3;
BA_ "U_V710_MY2023_Tx" SG_ 726 ACU_AFJump_St 1;
BA_ "U_P708_MY2023_Tx" SG_ 726 ACU_AFJump_St 1;
BA_ "U_V713AV_MY2022_Tx" SG_ 726 ACU_AFJump_St 1;
BA_ "U_V713N_MY2022_Tx" SG_ 726 ACU_AFJump_St 1;
BA_ "GenSigSendType" SG_ 726 ACU_AFJump_St 3;
BA_ "ContentDependant" SG_ 369 TrnIpcDsplMdeDActl_No_Cnt 1;
BA_ "MetaData" SG_ 369 TrnIpcDsplMdeDActl_No_Cnt 1;
BA_ "ContentDependant" SG_ 369 TrnIpcDsplMdeDActl_No_Cs 1;
BA_ "MetaData" SG_ 369 TrnIpcDsplMdeDActl_No_Cs 1;
BA_ "U_V710_MY2023_Rx" SG_ 369 CrawlMdeActv_B_Stat 1;
BA_ "U_P708_MY2023_Rx" SG_ 369 CrawlMdeActv_B_Stat 1;
BA_ "U_P708_MY2023_Rx" SG_ 369 SeatWorkSrfc_B_Falt 1;
BA_ "U_V713AV_MY2022_Rx" SG_ 369 SeatWorkSrfc_B_Falt 1;
BA_ "U_V713N_MY2022_Rx" SG_ 369 SeatWorkSrfc_B_Falt 1;
BA_ "U_V710_MY2023_Rx" SG_ 369 TrnIpcDsplyRng_D_Stat 1;
BA_ "U_P708_MY2023_Rx" SG_ 369 TrnIpcDsplyRng_D_Stat 1;
BA_ "U_V713AV_MY2022_Rx" SG_ 369 TrnIpcDsplyRng_D_Stat 1;
BA_ "U_V713N_MY2022_Rx" SG_ 369 TrnIpcDsplyRng_D_Stat 1;
BA_ "GenSigStartValue" SG_ 369 PrplWhlScnd_Tq_Cmd 2048;
BA_ "GenSigStartValue" SG_ 369 PrplWhlPrim_Tq_Cmd 2048;
BA_ "U_V710_MY2023_Rx" SG_ 369 TrnIpcDsplyGear_D_Actl 1;
BA_ "U_P708_MY2023_Rx" SG_ 369 TrnIpcDsplyGear_D_Actl 1;
BA_ "U_V713AV_MY2022_Rx" SG_ 369 TrnIpcDsplyGear_D_Actl 1;
BA_ "U_V713N_MY2022_Rx" SG_ 369 TrnIpcDsplyGear_D_Actl 1;
BA_ "GenSigStartValue" SG_ 369 TrnIpcDsplyGear_D_Actl 15;
BA_ "U_V710_MY2023_Rx" SG_ 369 TrnIpcDsplyMde_D_Stat 1;
BA_ "U_P708_MY2023_Rx" SG_ 369 TrnIpcDsplyMde_D_Stat 1;
BA_ "U_V713AV_MY2022_Rx" SG_ 369 TrnIpcDsplyMde_D_Stat 1;
BA_ "U_V713N_MY2022_Rx" SG_ 369 TrnIpcDsplyMde_D_Stat 1;
BA_ "WakeupSignal" SG_ 369 TrnIpcDsplyMde_D_Stat 1;
BA_ "U_V710_MY2023_Rx" SG_ 369 TrnIpcDsplyMde_D_Actl 1;
BA_ "U_P708_MY2023_Rx" SG_ 369 TrnIpcDsplyMde_D_Actl 1;
BA_ "U_V713AV_MY2022_Rx" SG_ 369 TrnIpcDsplyMde_D_Actl 1;
BA_ "U_V713N_MY2022_Rx" SG_ 369 TrnIpcDsplyMde_D_Actl 1;
BA_ "WakeupSignal" SG_ 369 TrnIpcDsplyMde_D_Actl 1;
BA_ "U_V710_MY2023_Rx" SG_ 369 TrnIpcDsplyGear_D_Stat 1;
BA_ "U_P708_MY2023_Rx" SG_ 369 TrnIpcDsplyGear_D_Stat 1;
BA_ "U_V713AV_MY2022_Rx" SG_ 369 TrnIpcDsplyGear_D_Stat 1;
BA_ "U_V713N_MY2022_Rx" SG_ 369 TrnIpcDsplyGear_D_Stat 1;
BA_ "U_V710_MY2023_Rx" SG_ 369 TrnIpcDsplyRng2_D_Actl 1;
BA_ "U_P708_MY2023_Rx" SG_ 369 TrnIpcDsplyRng2_D_Actl 1;
BA_ "U_V713AV_MY2022_Rx" SG_ 369 TrnIpcDsplyRng2_D_Actl 1;
BA_ "U_V713N_MY2022_Rx" SG_ 369 TrnIpcDsplyRng2_D_Actl 1;
BA_ "GenSigStartValue" SG_ 369 TrnIpcDsplyRng2_D_Actl 15;
BA_ "U_V710_MY2023_Tx" SG_ 1832 TesterPhysicalResIPC 1;
BA_ "U_P708_MY2023_Tx" SG_ 1832 TesterPhysicalResIPC 1;
BA_ "U_V713AV_MY2022_Tx" SG_ 1832 TesterPhysicalResIPC 1;
BA_ "U_V713N_MY2022_Tx" SG_ 1832 TesterPhysicalResIPC 1;
BA_ "GenSigSendType" SG_ 1832 TesterPhysicalResIPC 3;
BA_ "U_V713AV_MY2022_Rx" SG_ 1071 CluPdl_PcRate_Actl 1;
BA_ "U_V713N_MY2022_Rx" SG_ 1071 CluPdl_PcRate_Actl 1;
BA_ "U_V713AV_MY2022_Rx" SG_ 1071 CluPdlPosPcMeas_D_Qf 1;
BA_ "U_V713N_MY2022_Rx" SG_ 1071 CluPdlPosPcMeas_D_Qf 1;
BA_ "GenSigStartValue" SG_ 1071 CluPdlPosPcMeas_D_Qf 1;
BA_ "MetaData" SG_ 1071 CluPdlPosPcMeas_D_Qf 1;
BA_ "GenSigStartValue" SG_ 1071 EngMnfld3_P_Actl 254;
BA_ "U_V710_MY2023_Rx" SG_ 1071 EngAout_N_Dsply 1;
BA_ "U_P708_MY2023_Rx" SG_ 1071 EngAout_N_Dsply 1;
BA_ "U_V713AV_MY2022_Rx" SG_ 1071 EngAout_N_Dsply 1;
BA_ "U_V713N_MY2022_Rx" SG_ 1071 EngAout_N_Dsply 1;
BA_ "U_V713AV_MY2022_Rx" SG_ 1071 CluPdlPos_Pc_Meas 1;
BA_ "U_V713N_MY2022_Rx" SG_ 1071 CluPdlPos_Pc_Meas 1;
BA_ "U_V710_MY2023_Tx" SG_ 848 RILStat 1;
BA_ "U_P708_MY2023_Tx" SG_ 848 RILStat 1;
BA_ "U_V713AV_MY2022_Tx" SG_ 848 RILStat 1;
BA_ "U_V713N_MY2022_Tx" SG_ 848 RILStat 1;
BA_ "U_V710_MY2023_Rx" SG_ 610 AwdLckWhlRr_Pc_RqDsply 1;
BA_ "U_P708_MY2023_Rx" SG_ 610 AwdLckWhlRr_Pc_RqDsply 1;
BA_ "U_V713AV_MY2022_Rx" SG_ 610 AwdLckWhlRr_Pc_RqDsply 1;
BA_ "U_V713N_MY2022_Rx" SG_ 610 AwdLckWhlRr_Pc_RqDsply 1;
BA_ "U_V710_MY2023_Rx" SG_ 610 AwdLckWhlRl_Pc_RqDsply 1;
BA_ "U_P708_MY2023_Rx" SG_ 610 AwdLckWhlRl_Pc_RqDsply 1;
BA_ "U_V713AV_MY2022_Rx" SG_ 610 AwdLckWhlRl_Pc_RqDsply 1;
BA_ "U_V713N_MY2022_Rx" SG_ 610 AwdLckWhlRl_Pc_RqDsply 1;
BA_ "U_V710_MY2023_Rx" SG_ 610 AwdLckWhlFr_Pc_RqDsply 1;
BA_ "U_P708_MY2023_Rx" SG_ 610 AwdLckWhlFr_Pc_RqDsply 1;
BA_ "U_V713AV_MY2022_Rx" SG_ 610 AwdLckWhlFr_Pc_RqDsply 1;
BA_ "U_V713N_MY2022_Rx" SG_ 610 AwdLckWhlFr_Pc_RqDsply 1;
BA_ "U_V710_MY2023_Rx" SG_ 610 AwdLckWhlFl_Pc_RqDsply 1;
BA_ "U_P708_MY2023_Rx" SG_ 610 AwdLckWhlFl_Pc_RqDsply 1;
BA_ "U_V713AV_MY2022_Rx" SG_ 610 AwdLckWhlFl_Pc_RqDsply 1;
BA_ "U_V713N_MY2022_Rx" SG_ 610 AwdLckWhlFl_Pc_RqDsply 1;
BA_ "U_V710_MY2023_Tx" SG_ 1425 IPC_GWOnBoardTester 1;
BA_ "U_P708_MY2023_Tx" SG_ 1425 IPC_GWOnBoardTester 1;
BA_ "U_V713AV_MY2022_Tx" SG_ 1425 IPC_GWOnBoardTester 1;
BA_ "U_V713N_MY2022_Tx" SG_ 1425 IPC_GWOnBoardTester 1;
BA_ "U_V710_MY2023_Rx" SG_ 1425 IPC_GWOnBoardTester 1;
BA_ "U_P708_MY2023_Rx" SG_ 1425 IPC_GWOnBoardTester 1;
BA_ "GenSigStartValue" SG_ 1425 IPC_GWOnBoardTester 255;
BA_ "U_V710_MY2023_Tx" SG_ 1425 IPC_GWNMProxy 1;
BA_ "U_P708_MY2023_Tx" SG_ 1425 IPC_GWNMProxy 1;
BA_ "U_V713AV_MY2022_Tx" SG_ 1425 IPC_GWNMProxy 1;
BA_ "U_V713N_MY2022_Tx" SG_ 1425 IPC_GWNMProxy 1;
BA_ "U_V710_MY2023_Rx" SG_ 1425 IPC_GWNMProxy 1;
BA_ "U_P708_MY2023_Rx" SG_ 1425 IPC_GWNMProxy 1;
BA_ "GenSigStartValue" SG_ 1425 IPC_GWNMProxy 255;
BA_ "U_V710_MY2023_Tx" SG_ 1425 IPC_AutoSarNMReserved4 1;
BA_ "U_P708_MY2023_Tx" SG_ 1425 IPC_AutoSarNMReserved4 1;
BA_ "U_V713AV_MY2022_Tx" SG_ 1425 IPC_AutoSarNMReserved4 1;
BA_ "U_V713N_MY2022_Tx" SG_ 1425 IPC_AutoSarNMReserved4 1;
BA_ "U_V710_MY2023_Rx" SG_ 1425 IPC_AutoSarNMReserved4 1;
BA_ "U_P708_MY2023_Rx" SG_ 1425 IPC_AutoSarNMReserved4 1;
BA_ "GenSigStartValue" SG_ 1425 IPC_AutoSarNMReserved4 255;
BA_ "U_V710_MY2023_Tx" SG_ 1425 IPC_AutoSarNMReserved3 1;
BA_ "U_P708_MY2023_Tx" SG_ 1425 IPC_AutoSarNMReserved3 1;
BA_ "U_V713AV_MY2022_Tx" SG_ 1425 IPC_AutoSarNMReserved3 1;
BA_ "U_V713N_MY2022_Tx" SG_ 1425 IPC_AutoSarNMReserved3 1;
BA_ "U_V710_MY2023_Rx" SG_ 1425 IPC_AutoSarNMReserved3 1;
BA_ "U_P708_MY2023_Rx" SG_ 1425 IPC_AutoSarNMReserved3 1;
BA_ "GenSigStartValue" SG_ 1425 IPC_AutoSarNMReserved3 255;
BA_ "U_V710_MY2023_Tx" SG_ 1425 IPC_AutoSarNMReserved2 1;
BA_ "U_P708_MY2023_Tx" SG_ 1425 IPC_AutoSarNMReserved2 1;
BA_ "U_V713AV_MY2022_Tx" SG_ 1425 IPC_AutoSarNMReserved2 1;
BA_ "U_V713N_MY2022_Tx" SG_ 1425 IPC_AutoSarNMReserved2 1;
BA_ "U_V710_MY2023_Rx" SG_ 1425 IPC_AutoSarNMReserved2 1;
BA_ "U_P708_MY2023_Rx" SG_ 1425 IPC_AutoSarNMReserved2 1;
BA_ "GenSigStartValue" SG_ 1425 IPC_AutoSarNMReserved2 255;
BA_ "U_V710_MY2023_Tx" SG_ 1425 IPC_AutoSarNMReserved1 1;
BA_ "U_P708_MY2023_Tx" SG_ 1425 IPC_AutoSarNMReserved1 1;
BA_ "U_V713AV_MY2022_Tx" SG_ 1425 IPC_AutoSarNMReserved1 1;
BA_ "U_V713N_MY2022_Tx" SG_ 1425 IPC_AutoSarNMReserved1 1;
BA_ "U_V710_MY2023_Rx" SG_ 1425 IPC_AutoSarNMReserved1 1;
BA_ "U_P708_MY2023_Rx" SG_ 1425 IPC_AutoSarNMReserved1 1;
BA_ "GenSigStartValue" SG_ 1425 IPC_AutoSarNMReserved1 255;
BA_ "U_V710_MY2023_Tx" SG_ 1425 IPC_AutoSarNMNodeId 1;
BA_ "U_P708_MY2023_Tx" SG_ 1425 IPC_AutoSarNMNodeId 1;
BA_ "U_V713AV_MY2022_Tx" SG_ 1425 IPC_AutoSarNMNodeId 1;
BA_ "U_V713N_MY2022_Tx" SG_ 1425 IPC_AutoSarNMNodeId 1;
BA_ "U_V710_MY2023_Rx" SG_ 1425 IPC_AutoSarNMNodeId 1;
BA_ "U_P708_MY2023_Rx" SG_ 1425 IPC_AutoSarNMNodeId 1;
BA_ "GenSigStartValue" SG_ 1425 IPC_AutoSarNMNodeId 145;
BA_ "U_V710_MY2023_Tx" SG_ 1425 IPC_AutoSarNMControl 1;
BA_ "U_P708_MY2023_Tx" SG_ 1425 IPC_AutoSarNMControl 1;
BA_ "U_V713AV_MY2022_Tx" SG_ 1425 IPC_AutoSarNMControl 1;
BA_ "U_V713N_MY2022_Tx" SG_ 1425 IPC_AutoSarNMControl 1;
BA_ "U_V710_MY2023_Rx" SG_ 1425 IPC_AutoSarNMControl 1;
BA_ "U_P708_MY2023_Rx" SG_ 1425 IPC_AutoSarNMControl 1;
BA_ "U_P708_MY2023_Rx" SG_ 998 PersIndexSccm_D_Actl 1;
BA_ "U_V713AV_MY2022_Rx" SG_ 998 PersIndexSccm_D_Actl 1;
BA_ "U_V713N_MY2022_Rx" SG_ 998 PersIndexSccm_D_Actl 1;
BA_ "GenSigStartValue" SG_ 998 PersIndexSccm_D_Actl 4;
BA_ "U_V710_MY2023_Rx" SG_ 998 FeatNoSccmActl 1;
BA_ "U_P708_MY2023_Rx" SG_ 998 FeatNoSccmActl 1;
BA_ "U_V713AV_MY2022_Rx" SG_ 998 FeatNoSccmActl 1;
BA_ "U_V713N_MY2022_Rx" SG_ 998 FeatNoSccmActl 1;
BA_ "U_V710_MY2023_Rx" SG_ 998 FeatConfigSccmActl 1;
BA_ "U_P708_MY2023_Rx" SG_ 998 FeatConfigSccmActl 1;
BA_ "U_V713AV_MY2022_Rx" SG_ 998 FeatConfigSccmActl 1;
BA_ "U_V713N_MY2022_Rx" SG_ 998 FeatConfigSccmActl 1;
BA_ "U_V710_MY2023_Rx" SG_ 984 LaActvStats_D2_Dsply 1;
BA_ "U_P708_MY2023_Rx" SG_ 984 LaActvStats_D2_Dsply 1;
BA_ "U_V710_MY2023_Rx" SG_ 984 AhbFeat_D_Stat 1;
BA_ "U_V710_MY2023_Rx" SG_ 984 DsmcMsgTxt_D_Dsply 1;
BA_ "U_P708_MY2023_Rx" SG_ 984 DsmcMsgTxt_D_Dsply 1;
BA_ "U_V713AV_MY2022_Rx" SG_ 984 DsmcMsgTxt_D_Dsply 1;
BA_ "U_V713N_MY2022_Rx" SG_ 984 DsmcMsgTxt_D_Dsply 1;
BA_ "U_V710_MY2023_Rx" SG_ 984 DasWarn_D_Dsply 1;
BA_ "U_P708_MY2023_Rx" SG_ 984 DasWarn_D_Dsply 1;
BA_ "U_V713AV_MY2022_Rx" SG_ 984 DasWarn_D_Dsply 1;
BA_ "U_V713N_MY2022_Rx" SG_ 984 DasWarn_D_Dsply 1;
BA_ "U_V710_MY2023_Rx" SG_ 984 DasStats_D_Dsply 1;
BA_ "U_P708_MY2023_Rx" SG_ 984 DasStats_D_Dsply 1;
BA_ "U_V713AV_MY2022_Rx" SG_ 984 DasStats_D_Dsply 1;
BA_ "U_V713N_MY2022_Rx" SG_ 984 DasStats_D_Dsply 1;
BA_ "U_V710_MY2023_Rx" SG_ 984 DasAlrtLvl_D_Dsply 1;
BA_ "U_P708_MY2023_Rx" SG_ 984 DasAlrtLvl_D_Dsply 1;
BA_ "U_V713AV_MY2022_Rx" SG_ 984 DasAlrtLvl_D_Dsply 1;
BA_ "U_V713N_MY2022_Rx" SG_ 984 DasAlrtLvl_D_Dsply 1;
BA_ "U_P708_MY2023_Rx" SG_ 984 CamraStats_D_Dsply 1;
BA_ "U_V713AV_MY2022_Rx" SG_ 984 CamraStats_D_Dsply 1;
BA_ "U_V713N_MY2022_Rx" SG_ 984 CamraStats_D_Dsply 1;
BA_ "U_V710_MY2023_Rx" SG_ 984 LaHandsOff_D_Dsply 1;
BA_ "U_P708_MY2023_Rx" SG_ 984 LaHandsOff_D_Dsply 1;
BA_ "U_V713AV_MY2022_Rx" SG_ 984 LaHandsOff_D_Dsply 1;
BA_ "U_V713N_MY2022_Rx" SG_ 984 LaHandsOff_D_Dsply 1;
BA_ "U_V710_MY2023_Rx" SG_ 984 LaDenyStats_B_Dsply 1;
BA_ "U_P708_MY2023_Rx" SG_ 984 LaDenyStats_B_Dsply 1;
BA_ "U_V713AV_MY2022_Rx" SG_ 984 LaDenyStats_B_Dsply 1;
BA_ "U_V713N_MY2022_Rx" SG_ 984 LaDenyStats_B_Dsply 1;
BA_ "U_V710_MY2023_Rx" SG_ 984 CamraDefog_B_Req 1;
BA_ "U_V713AV_MY2022_Rx" SG_ 984 CamraDefog_B_Req 1;
BA_ "U_V713N_MY2022_Rx" SG_ 984 CamraDefog_B_Req 1;
BA_ "U_V710_MY2023_Rx" SG_ 984 PersIndexIpma_D_Actl 1;
BA_ "U_P708_MY2023_Rx" SG_ 984 PersIndexIpma_D_Actl 1;
BA_ "U_V713AV_MY2022_Rx" SG_ 984 PersIndexIpma_D_Actl 1;
BA_ "U_V713N_MY2022_Rx" SG_ 984 PersIndexIpma_D_Actl 1;
BA_ "GenSigStartValue" SG_ 984 PersIndexIpma_D_Actl 4;
BA_ "U_V710_MY2023_Rx" SG_ 984 FeatNoIpmaActl 1;
BA_ "U_P708_MY2023_Rx" SG_ 984 FeatNoIpmaActl 1;
BA_ "U_V713AV_MY2022_Rx" SG_ 984 FeatNoIpmaActl 1;
BA_ "U_V713N_MY2022_Rx" SG_ 984 FeatNoIpmaActl 1;
BA_ "U_V710_MY2023_Rx" SG_ 984 FeatConfigIpmaActl 1;
BA_ "U_P708_MY2023_Rx" SG_ 984 FeatConfigIpmaActl 1;
BA_ "U_V713AV_MY2022_Rx" SG_ 984 FeatConfigIpmaActl 1;
BA_ "U_V713N_MY2022_Rx" SG_ 984 FeatConfigIpmaActl 1;
BA_ "U_V713AV_MY2022_Tx" SG_ 1072 PtDrvMde_D_Rq 1;
BA_ "U_V713N_MY2022_Tx" SG_ 1072 PtDrvMde_D_Rq 1;
BA_ "GenSigSendType" SG_ 1072 PtDrvMde_D_Rq 3;
BA_ "U_V710_MY2023_Tx" SG_ 1072 DrvSlipCtlMde_D_Rq 1;
BA_ "U_P708_MY2023_Tx" SG_ 1072 DrvSlipCtlMde_D_Rq 1;
BA_ "U_V713AV_MY2022_Tx" SG_ 1072 DrvSlipCtlMde_D_Rq 1;
BA_ "U_V713N_MY2022_Tx" SG_ 1072 DrvSlipCtlMde_D_Rq 1;
BA_ "U_V710_MY2023_Rx" SG_ 1072 DrvSlipCtlMde_D_Rq 1;
BA_ "U_P708_MY2023_Rx" SG_ 1072 DrvSlipCtlMde_D_Rq 1;
BA_ "U_V713AV_MY2022_Rx" SG_ 1072 DrvSlipCtlMde_D_Rq 1;
BA_ "U_V713N_MY2022_Rx" SG_ 1072 DrvSlipCtlMde_D_Rq 1;
BA_ "ECGUsedRxSignal" SG_ 1072 DrvSlipCtlMde_D_Rq 1;
BA_ "GenSigSendType" SG_ 1072 DrvSlipCtlMde_D_Rq 3;
BA_ "U_V710_MY2023_Tx" SG_ 1072 EngIdlShutDown_B_RqDrv 1;
BA_ "U_P708_MY2023_Tx" SG_ 1072 EngIdlShutDown_B_RqDrv 1;
BA_ "U_V713AV_MY2022_Tx" SG_ 1072 EngIdlShutDown_B_RqDrv 1;
BA_ "U_V713N_MY2022_Tx" SG_ 1072 EngIdlShutDown_B_RqDrv 1;
BA_ "GenSigSendType" SG_ 1072 EngIdlShutDown_B_RqDrv 3;
BA_ "U_V713AV_MY2022_Tx" SG_ 1072 DrvPerfMde_D_Rq 1;
BA_ "U_V713N_MY2022_Tx" SG_ 1072 DrvPerfMde_D_Rq 1;
BA_ "GenSigSendType" SG_ 1072 DrvPerfMde_D_Rq 3;
BA_ "U_V710_MY2023_Tx" SG_ 1072 HsaMde_D_Rq 1;
BA_ "U_P708_MY2023_Tx" SG_ 1072 HsaMde_D_Rq 1;
BA_ "U_V713AV_MY2022_Tx" SG_ 1072 HsaMde_D_Rq 1;
BA_ "U_V713N_MY2022_Tx" SG_ 1072 HsaMde_D_Rq 1;
BA_ "GenSigSendType" SG_ 1072 HsaMde_D_Rq 3;
BA_ "GenSigStartValue" SG_ 1072 HsaMde_D_Rq 1;
BA_ "U_V713AV_MY2022_Tx" SG_ 1072 StopStrtDrvMde_D_RqMnu 1;
BA_ "U_V713N_MY2022_Tx" SG_ 1072 StopStrtDrvMde_D_RqMnu 1;
BA_ "GenSigSendType" SG_ 1072 StopStrtDrvMde_D_RqMnu 3;
BA_ "U_V710_MY2023_Tx" SG_ 1072 NtrlTowMdeEnbl_B_RqDrv 1;
BA_ "U_P708_MY2023_Tx" SG_ 1072 NtrlTowMdeEnbl_B_RqDrv 1;
BA_ "U_V713AV_MY2022_Tx" SG_ 1072 NtrlTowMdeEnbl_B_RqDrv 1;
BA_ "U_V713N_MY2022_Tx" SG_ 1072 NtrlTowMdeEnbl_B_RqDrv 1;
BA_ "GenSigSendType" SG_ 1072 NtrlTowMdeEnbl_B_RqDrv 3;
BA_ "U_P708_MY2023_Tx" SG_ 1072 LscmbbStat_B_Actl 1;
BA_ "U_V713AV_MY2022_Tx" SG_ 1072 LscmbbStat_B_Actl 1;
BA_ "U_V713N_MY2022_Tx" SG_ 1072 LscmbbStat_B_Actl 1;
BA_ "U_V710_MY2023_Rx" SG_ 1072 LscmbbStat_B_Actl 1;
BA_ "U_P708_MY2023_Rx" SG_ 1072 LscmbbStat_B_Actl 1;
BA_ "U_V713AV_MY2022_Rx" SG_ 1072 LscmbbStat_B_Actl 1;
BA_ "U_V713N_MY2022_Rx" SG_ 1072 LscmbbStat_B_Actl 1;
BA_ "ECGUsedRxSignal" SG_ 1072 LscmbbStat_B_Actl 1;
BA_ "GenSigSendType" SG_ 1072 LscmbbStat_B_Actl 3;
BA_ "U_V710_MY2023_Tx" SG_ 1072 BulbChkActv_B_Stat 1;
BA_ "U_P708_MY2023_Tx" SG_ 1072 BulbChkActv_B_Stat 1;
BA_ "U_V713AV_MY2022_Tx" SG_ 1072 BulbChkActv_B_Stat 1;
BA_ "U_V713N_MY2022_Tx" SG_ 1072 BulbChkActv_B_Stat 1;
BA_ "GenSigSendType" SG_ 1072 BulbChkActv_B_Stat 3;
BA_ "U_V710_MY2023_Tx" SG_ 1072 ParkDetect_Stat 1;
BA_ "U_P708_MY2023_Tx" SG_ 1072 ParkDetect_Stat 1;
BA_ "U_V713AV_MY2022_Tx" SG_ 1072 ParkDetect_Stat 1;
BA_ "U_V713N_MY2022_Tx" SG_ 1072 ParkDetect_Stat 1;
BA_ "U_P708_MY2023_Rx" SG_ 1072 ParkDetect_Stat 1;
BA_ "GenSigSendType" SG_ 1072 ParkDetect_Stat 3;
BA_ "U_V710_MY2023_Tx" SG_ 1072 ReducedGuard_D_Rq 1;
BA_ "U_P708_MY2023_Tx" SG_ 1072 ReducedGuard_D_Rq 1;
BA_ "U_V713AV_MY2022_Tx" SG_ 1072 ReducedGuard_D_Rq 1;
BA_ "U_V713N_MY2022_Tx" SG_ 1072 ReducedGuard_D_Rq 1;
BA_ "GenSigSendType" SG_ 1072 ReducedGuard_D_Rq 3;
BA_ "U_V710_MY2023_Tx" SG_ 1072 FrostWarn_D_Stat 1;
BA_ "U_V713AV_MY2022_Tx" SG_ 1072 FrostWarn_D_Stat 1;
BA_ "U_V713N_MY2022_Tx" SG_ 1072 FrostWarn_D_Stat 1;
BA_ "GenSigSendType" SG_ 1072 FrostWarn_D_Stat 3;
BA_ "U_V710_MY2023_Tx" SG_ 1072 TrlrBrkMde_D_Rq 1;
BA_ "U_P708_MY2023_Tx" SG_ 1072 TrlrBrkMde_D_Rq 1;
BA_ "U_V713AV_MY2022_Tx" SG_ 1072 TrlrBrkMde_D_Rq 1;
BA_ "U_V713N_MY2022_Tx" SG_ 1072 TrlrBrkMde_D_Rq 1;
BA_ "U_P708_MY2023_Rx" SG_ 1072 TrlrBrkMde_D_Rq 1;
BA_ "GenSigSendType" SG_ 1072 TrlrBrkMde_D_Rq 3;
BA_ "U_V710_MY2023_Tx" SG_ 1072 TRLR_SWAY_CONFIG_CMD 1;
BA_ "U_P708_MY2023_Tx" SG_ 1072 TRLR_SWAY_CONFIG_CMD 1;
BA_ "U_V713AV_MY2022_Tx" SG_ 1072 TRLR_SWAY_CONFIG_CMD 1;
BA_ "U_V713N_MY2022_Tx" SG_ 1072 TRLR_SWAY_CONFIG_CMD 1;
BA_ "GenSigSendType" SG_ 1072 TRLR_SWAY_CONFIG_CMD 3;
BA_ "U_V710_MY2023_Tx" SG_ 1072 TRAILER_BRAKE_CONFIG 1;
BA_ "U_P708_MY2023_Tx" SG_ 1072 TRAILER_BRAKE_CONFIG 1;
BA_ "U_V713AV_MY2022_Tx" SG_ 1072 TRAILER_BRAKE_CONFIG 1;
BA_ "U_V713N_MY2022_Tx" SG_ 1072 TRAILER_BRAKE_CONFIG 1;
BA_ "U_P708_MY2023_Rx" SG_ 1072 TRAILER_BRAKE_CONFIG 1;
BA_ "GenSigSendType" SG_ 1072 TRAILER_BRAKE_CONFIG 3;
BA_ "U_V710_MY2023_Tx" SG_ 1072 Power_Liftgate_Mode_Cmd 1;
BA_ "U_P708_MY2023_Tx" SG_ 1072 Power_Liftgate_Mode_Cmd 1;
BA_ "U_V713AV_MY2022_Tx" SG_ 1072 Power_Liftgate_Mode_Cmd 1;
BA_ "U_V713N_MY2022_Tx" SG_ 1072 Power_Liftgate_Mode_Cmd 1;
BA_ "GenSigSendType" SG_ 1072 Power_Liftgate_Mode_Cmd 3;
BA_ "WakeupSignal" SG_ 1072 Power_Liftgate_Mode_Cmd 1;
BA_ "U_V710_MY2023_Tx" SG_ 1072 AccEnbl_B_RqDrv 1;
BA_ "U_P708_MY2023_Tx" SG_ 1072 AccEnbl_B_RqDrv 1;
BA_ "U_V713AV_MY2022_Tx" SG_ 1072 AccEnbl_B_RqDrv 1;
BA_ "U_V713N_MY2022_Tx" SG_ 1072 AccEnbl_B_RqDrv 1;
BA_ "U_P708_MY2023_Rx" SG_ 1072 AccEnbl_B_RqDrv 1;
BA_ "GenSigSendType" SG_ 1072 AccEnbl_B_RqDrv 3;
BA_ "GenSigStartValue" SG_ 1072 AccEnbl_B_RqDrv 1;
BA_ "U_V710_MY2023_Tx" SG_ 1072 HaDsplyCpblty_B_Stat 1;
BA_ "U_P708_MY2023_Tx" SG_ 1072 HaDsplyCpblty_B_Stat 1;
BA_ "GenSigSendType" SG_ 1072 HaDsplyCpblty_B_Stat 3;
BA_ "U_V710_MY2023_Tx" SG_ 1072 OdometerMasterValue 1;
BA_ "U_P708_MY2023_Tx" SG_ 1072 OdometerMasterValue 1;
BA_ "U_V713AV_MY2022_Tx" SG_ 1072 OdometerMasterValue 1;
BA_ "U_V713N_MY2022_Tx" SG_ 1072 OdometerMasterValue 1;
BA_ "U_V710_MY2023_Rx" SG_ 1072 OdometerMasterValue 1;
BA_ "U_P708_MY2023_Rx" SG_ 1072 OdometerMasterValue 1;
BA_ "U_V713AV_MY2022_Rx" SG_ 1072 OdometerMasterValue 1;
BA_ "U_V713N_MY2022_Rx" SG_ 1072 OdometerMasterValue 1;
BA_ "ECGUsedRxSignal" SG_ 1072 OdometerMasterValue 1;
BA_ "U_V710_MY2023_Tx" SG_ 1072 EngOilLife_B_RqReset 1;
BA_ "U_P708_MY2023_Tx" SG_ 1072 EngOilLife_B_RqReset 1;
BA_ "U_V713AV_MY2022_Tx" SG_ 1072 EngOilLife_B_RqReset 1;
BA_ "U_V713N_MY2022_Tx" SG_ 1072 EngOilLife_B_RqReset 1;
BA_ "GenSigSendType" SG_ 1072 EngOilLife_B_RqReset 3;
BA_ "U_P708_MY2023_Tx" SG_ 1072 MetricActvTe_B_Actl 1;
BA_ "U_V713AV_MY2022_Tx" SG_ 1072 MetricActvTe_B_Actl 1;
BA_ "U_V713N_MY2022_Tx" SG_ 1072 MetricActvTe_B_Actl 1;
BA_ "GenSigSendType" SG_ 1072 MetricActvTe_B_Actl 3;
BA_ "U_P708_MY2023_Tx" SG_ 1072 AccDeny_B_RqIpc 1;
BA_ "U_V713AV_MY2022_Tx" SG_ 1072 AccDeny_B_RqIpc 1;
BA_ "U_V713N_MY2022_Tx" SG_ 1072 AccDeny_B_RqIpc 1;
BA_ "U_P708_MY2023_Rx" SG_ 1072 AccDeny_B_RqIpc 1;
BA_ "GenSigSendType" SG_ 1072 AccDeny_B_RqIpc 3;
BA_ "U_V710_MY2023_Tx" SG_ 1072 ePRNDL_MODE 1;
BA_ "U_P708_MY2023_Tx" SG_ 1072 ePRNDL_MODE 1;
BA_ "U_V713AV_MY2022_Tx" SG_ 1072 ePRNDL_MODE 1;
BA_ "U_V713N_MY2022_Tx" SG_ 1072 ePRNDL_MODE 1;
BA_ "GenSigSendType" SG_ 1072 ePRNDL_MODE 3;
BA_ "WakeupSignal" SG_ 1072 ePRNDL_MODE 1;
BA_ "U_V713AV_MY2022_Tx" SG_ 1072 PrkLckCtlEnbl_D_RqIpc 1;
BA_ "U_V713N_MY2022_Tx" SG_ 1072 PrkLckCtlEnbl_D_RqIpc 1;
BA_ "GenSigSendType" SG_ 1072 PrkLckCtlEnbl_D_RqIpc 3;
BA_ "U_V710_MY2023_Tx" SG_ 1072 DrvSlipCtlMde_B_Rq2 1;
BA_ "U_P708_MY2023_Tx" SG_ 1072 DrvSlipCtlMde_B_Rq2 1;
BA_ "U_V713AV_MY2022_Tx" SG_ 1072 DrvSlipCtlMde_B_Rq2 1;
BA_ "U_V713N_MY2022_Tx" SG_ 1072 DrvSlipCtlMde_B_Rq2 1;
BA_ "GenSigSendType" SG_ 1072 DrvSlipCtlMde_B_Rq2 3;
BA_ "U_V713AV_MY2022_Tx" SG_ 1072 Fda_B_Stat 1;
BA_ "U_V713N_MY2022_Tx" SG_ 1072 Fda_B_Stat 1;
BA_ "GenSigSendType" SG_ 1072 Fda_B_Stat 3;
BA_ "U_V710_MY2023_Tx" SG_ 1072 MetricActv_B_Actl 1;
BA_ "U_P708_MY2023_Tx" SG_ 1072 MetricActv_B_Actl 1;
BA_ "U_V713AV_MY2022_Tx" SG_ 1072 MetricActv_B_Actl 1;
BA_ "U_V713N_MY2022_Tx" SG_ 1072 MetricActv_B_Actl 1;
BA_ "U_V710_MY2023_Rx" SG_ 1072 MetricActv_B_Actl 1;
BA_ "U_P708_MY2023_Rx" SG_ 1072 MetricActv_B_Actl 1;
BA_ "U_V713AV_MY2022_Rx" SG_ 1072 MetricActv_B_Actl 1;
BA_ "U_V713N_MY2022_Rx" SG_ 1072 MetricActv_B_Actl 1;
BA_ "ECGUsedRxSignal" SG_ 1072 MetricActv_B_Actl 1;
BA_ "GenSigSendType" SG_ 1072 MetricActv_B_Actl 3;
BA_ "U_V710_MY2023_Tx" SG_ 1072 KeyTypeChngMykey_D_Rq 1;
BA_ "U_P708_MY2023_Tx" SG_ 1072 KeyTypeChngMykey_D_Rq 1;
BA_ "U_V713AV_MY2022_Tx" SG_ 1072 KeyTypeChngMykey_D_Rq 1;
BA_ "U_V713N_MY2022_Tx" SG_ 1072 KeyTypeChngMykey_D_Rq 1;
BA_ "GenSigSendType" SG_ 1072 KeyTypeChngMykey_D_Rq 3;
BA_ "U_V710_MY2023_Tx" SG_ 1072 ManRgen_D_Rq 1;
BA_ "U_P708_MY2023_Tx" SG_ 1072 ManRgen_D_Rq 1;
BA_ "U_V713AV_MY2022_Tx" SG_ 1072 ManRgen_D_Rq 1;
BA_ "U_V713N_MY2022_Tx" SG_ 1072 ManRgen_D_Rq 1;
BA_ "GenSigSendType" SG_ 1072 ManRgen_D_Rq 3;
BA_ "U_V710_MY2023_Tx" SG_ 395 SelDrvMdeCnfm_D_Stat 1;
BA_ "U_P708_MY2023_Tx" SG_ 395 SelDrvMdeCnfm_D_Stat 1;
BA_ "U_V713AV_MY2022_Tx" SG_ 395 SelDrvMdeCnfm_D_Stat 1;
BA_ "U_V713N_MY2022_Tx" SG_ 395 SelDrvMdeCnfm_D_Stat 1;
BA_ "GenSigSendType" SG_ 395 SelDrvMdeCnfm_D_Stat 3;
BA_ "GenSigStartValue" SG_ 395 HudShifPoint_N_Rq 30;
BA_ "GenSigSendType" SG_ 395 HudMde_D_Rq 3;
BA_ "GenSigSendType" SG_ 395 HudLedMde_D_Rq 3;
BA_ "GenSigSendType" SG_ 395 HudLed9On_B_Rq 3;
BA_ "GenSigSendType" SG_ 395 HudLed8On_B_Rq 3;
BA_ "GenSigSendType" SG_ 395 HudLed7On_B_Rq 3;
BA_ "GenSigSendType" SG_ 395 HudLed6On_B_Rq 3;
BA_ "GenSigSendType" SG_ 395 HudLed5On_B_Rq 3;
BA_ "GenSigSendType" SG_ 395 HudLed4On_B_Rq 3;
BA_ "GenSigSendType" SG_ 395 HudLed3On_B_Rq 3;
BA_ "GenSigSendType" SG_ 395 HudLed2On_B_Rq 3;
BA_ "GenSigSendType" SG_ 395 HudLed1On_B_Rq 3;
BA_ "GenSigSendType" SG_ 395 HudLed18On_B_Rq 3;
BA_ "GenSigSendType" SG_ 395 HudLed17On_B_Rq 3;
BA_ "GenSigSendType" SG_ 395 HudLed16On_B_Rq 3;
BA_ "GenSigSendType" SG_ 395 HudLed15On_B_Rq 3;
BA_ "GenSigSendType" SG_ 395 HudLed14On_B_Rq 3;
BA_ "GenSigSendType" SG_ 395 HudLed13On_B_Rq 3;
BA_ "GenSigSendType" SG_ 395 HudLed12On_B_Rq 3;
BA_ "GenSigSendType" SG_ 395 HudLed11On_B_Rq 3;
BA_ "GenSigSendType" SG_ 395 HudLed10On_B_Rq 3;
BA_ "U_V710_MY2023_Tx" SG_ 1438 GWM_GWOnBoardTester 1;
BA_ "U_P708_MY2023_Tx" SG_ 1438 GWM_GWOnBoardTester 1;
BA_ "U_V713AV_MY2022_Tx" SG_ 1438 GWM_GWOnBoardTester 1;
BA_ "U_V713N_MY2022_Tx" SG_ 1438 GWM_GWOnBoardTester 1;
BA_ "ECGUsedTxSignal" SG_ 1438 GWM_GWOnBoardTester 1;
BA_ "U_V713AV_MY2022_Rx" SG_ 1438 GWM_GWOnBoardTester 1;
BA_ "U_V713N_MY2022_Rx" SG_ 1438 GWM_GWOnBoardTester 1;
BA_ "U_V710_MY2023_Rx" SG_ 1438 GWM_GWOnBoardTester 1;
BA_ "U_P708_MY2023_Rx" SG_ 1438 GWM_GWOnBoardTester 1;
BA_ "GenSigStartValue" SG_ 1438 GWM_GWOnBoardTester 255;
BA_ "U_V710_MY2023_Tx" SG_ 1438 GWM_GWNMProxy 1;
BA_ "U_P708_MY2023_Tx" SG_ 1438 GWM_GWNMProxy 1;
BA_ "U_V713AV_MY2022_Tx" SG_ 1438 GWM_GWNMProxy 1;
BA_ "U_V713N_MY2022_Tx" SG_ 1438 GWM_GWNMProxy 1;
BA_ "ECGUsedTxSignal" SG_ 1438 GWM_GWNMProxy 1;
BA_ "U_V713AV_MY2022_Rx" SG_ 1438 GWM_GWNMProxy 1;
BA_ "U_V713N_MY2022_Rx" SG_ 1438 GWM_GWNMProxy 1;
BA_ "U_V710_MY2023_Rx" SG_ 1438 GWM_GWNMProxy 1;
BA_ "U_P708_MY2023_Rx" SG_ 1438 GWM_GWNMProxy 1;
BA_ "GenSigStartValue" SG_ 1438 GWM_GWNMProxy 255;
BA_ "U_V710_MY2023_Tx" SG_ 1438 GWM_AutoSarNMReserved4 1;
BA_ "U_P708_MY2023_Tx" SG_ 1438 GWM_AutoSarNMReserved4 1;
BA_ "U_V713AV_MY2022_Tx" SG_ 1438 GWM_AutoSarNMReserved4 1;
BA_ "U_V713N_MY2022_Tx" SG_ 1438 GWM_AutoSarNMReserved4 1;
BA_ "ECGUsedTxSignal" SG_ 1438 GWM_AutoSarNMReserved4 1;
BA_ "U_V713AV_MY2022_Rx" SG_ 1438 GWM_AutoSarNMReserved4 1;
BA_ "U_V713N_MY2022_Rx" SG_ 1438 GWM_AutoSarNMReserved4 1;
BA_ "U_V710_MY2023_Rx" SG_ 1438 GWM_AutoSarNMReserved4 1;
BA_ "U_P708_MY2023_Rx" SG_ 1438 GWM_AutoSarNMReserved4 1;
BA_ "GenSigStartValue" SG_ 1438 GWM_AutoSarNMReserved4 255;
BA_ "U_V710_MY2023_Tx" SG_ 1438 GWM_AutoSarNMReserved3 1;
BA_ "U_P708_MY2023_Tx" SG_ 1438 GWM_AutoSarNMReserved3 1;
BA_ "U_V713AV_MY2022_Tx" SG_ 1438 GWM_AutoSarNMReserved3 1;
BA_ "U_V713N_MY2022_Tx" SG_ 1438 GWM_AutoSarNMReserved3 1;
BA_ "ECGUsedTxSignal" SG_ 1438 GWM_AutoSarNMReserved3 1;
BA_ "U_V713AV_MY2022_Rx" SG_ 1438 GWM_AutoSarNMReserved3 1;
BA_ "U_V713N_MY2022_Rx" SG_ 1438 GWM_AutoSarNMReserved3 1;
BA_ "U_V710_MY2023_Rx" SG_ 1438 GWM_AutoSarNMReserved3 1;
BA_ "U_P708_MY2023_Rx" SG_ 1438 GWM_AutoSarNMReserved3 1;
BA_ "GenSigStartValue" SG_ 1438 GWM_AutoSarNMReserved3 255;
BA_ "U_V710_MY2023_Tx" SG_ 1438 GWM_AutoSarNMReserved2 1;
BA_ "U_P708_MY2023_Tx" SG_ 1438 GWM_AutoSarNMReserved2 1;
BA_ "U_V713AV_MY2022_Tx" SG_ 1438 GWM_AutoSarNMReserved2 1;
BA_ "U_V713N_MY2022_Tx" SG_ 1438 GWM_AutoSarNMReserved2 1;
BA_ "ECGUsedTxSignal" SG_ 1438 GWM_AutoSarNMReserved2 1;
BA_ "U_V713AV_MY2022_Rx" SG_ 1438 GWM_AutoSarNMReserved2 1;
BA_ "U_V713N_MY2022_Rx" SG_ 1438 GWM_AutoSarNMReserved2 1;
BA_ "U_V710_MY2023_Rx" SG_ 1438 GWM_AutoSarNMReserved2 1;
BA_ "U_P708_MY2023_Rx" SG_ 1438 GWM_AutoSarNMReserved2 1;
BA_ "GenSigStartValue" SG_ 1438 GWM_AutoSarNMReserved2 255;
BA_ "U_V710_MY2023_Tx" SG_ 1438 GWM_AutoSarNMReserved1 1;
BA_ "U_P708_MY2023_Tx" SG_ 1438 GWM_AutoSarNMReserved1 1;
BA_ "U_V713AV_MY2022_Tx" SG_ 1438 GWM_AutoSarNMReserved1 1;
BA_ "U_V713N_MY2022_Tx" SG_ 1438 GWM_AutoSarNMReserved1 1;
BA_ "ECGUsedTxSignal" SG_ 1438 GWM_AutoSarNMReserved1 1;
BA_ "U_V713AV_MY2022_Rx" SG_ 1438 GWM_AutoSarNMReserved1 1;
BA_ "U_V713N_MY2022_Rx" SG_ 1438 GWM_AutoSarNMReserved1 1;
BA_ "U_V710_MY2023_Rx" SG_ 1438 GWM_AutoSarNMReserved1 1;
BA_ "U_P708_MY2023_Rx" SG_ 1438 GWM_AutoSarNMReserved1 1;
BA_ "GenSigStartValue" SG_ 1438 GWM_AutoSarNMReserved1 255;
BA_ "U_V710_MY2023_Tx" SG_ 1438 GWM_AutoSarNMNodeId 1;
BA_ "U_P708_MY2023_Tx" SG_ 1438 GWM_AutoSarNMNodeId 1;
BA_ "U_V713AV_MY2022_Tx" SG_ 1438 GWM_AutoSarNMNodeId 1;
BA_ "U_V713N_MY2022_Tx" SG_ 1438 GWM_AutoSarNMNodeId 1;
BA_ "ECGUsedTxSignal" SG_ 1438 GWM_AutoSarNMNodeId 1;
BA_ "U_V713AV_MY2022_Rx" SG_ 1438 GWM_AutoSarNMNodeId 1;
BA_ "U_V713N_MY2022_Rx" SG_ 1438 GWM_AutoSarNMNodeId 1;
BA_ "U_V710_MY2023_Rx" SG_ 1438 GWM_AutoSarNMNodeId 1;
BA_ "U_P708_MY2023_Rx" SG_ 1438 GWM_AutoSarNMNodeId 1;
BA_ "GenSigStartValue" SG_ 1438 GWM_AutoSarNMNodeId 158;
BA_ "U_V710_MY2023_Tx" SG_ 1438 GWM_AutoSarNMControl 1;
BA_ "U_P708_MY2023_Tx" SG_ 1438 GWM_AutoSarNMControl 1;
BA_ "U_V713AV_MY2022_Tx" SG_ 1438 GWM_AutoSarNMControl 1;
BA_ "U_V713N_MY2022_Tx" SG_ 1438 GWM_AutoSarNMControl 1;
BA_ "ECGUsedTxSignal" SG_ 1438 GWM_AutoSarNMControl 1;
BA_ "U_V713AV_MY2022_Rx" SG_ 1438 GWM_AutoSarNMControl 1;
BA_ "U_V713N_MY2022_Rx" SG_ 1438 GWM_AutoSarNMControl 1;
BA_ "U_V710_MY2023_Rx" SG_ 1438 GWM_AutoSarNMControl 1;
BA_ "U_P708_MY2023_Rx" SG_ 1438 GWM_AutoSarNMControl 1;
BA_ "U_V710_MY2023_Rx" SG_ 76 RstrnPsngrOn_D_Stat 1;
BA_ "U_P708_MY2023_Rx" SG_ 76 RstrnPsngrOn_D_Stat 1;
BA_ "U_V713AV_MY2022_Rx" SG_ 76 RstrnPsngrOn_D_Stat 1;
BA_ "U_V713N_MY2022_Rx" SG_ 76 RstrnPsngrOn_D_Stat 1;
BA_ "MetaData" SG_ 76 FirstRowBuckle_No_Cs 1;
BA_ "MetaData" SG_ 76 RCMStatusMsg2_No_Cnt 1;
BA_ "U_V710_MY2023_Rx" SG_ 76 PsngrFmidDetct_D_Actl 1;
BA_ "U_P708_MY2023_Rx" SG_ 76 PsngrFmidDetct_D_Actl 1;
BA_ "U_V713AV_MY2022_Rx" SG_ 76 PsngrFmidDetct_D_Actl 1;
BA_ "U_V713N_MY2022_Rx" SG_ 76 PsngrFmidDetct_D_Actl 1;
BA_ "GenSigStartValue" SG_ 76 PsngrFmidDetct_D_Actl 3;
BA_ "U_V710_MY2023_Rx" SG_ 76 FirstRowBuckleMid 1;
BA_ "U_P708_MY2023_Rx" SG_ 76 FirstRowBuckleMid 1;
BA_ "U_V713AV_MY2022_Rx" SG_ 76 FirstRowBuckleMid 1;
BA_ "U_V713N_MY2022_Rx" SG_ 76 FirstRowBuckleMid 1;
BA_ "GenSigStartValue" SG_ 76 FirstRowBuckleMid 3;
BA_ "U_V710_MY2023_Rx" SG_ 76 ThirdRowBucklePsngr 1;
BA_ "U_P708_MY2023_Rx" SG_ 76 ThirdRowBucklePsngr 1;
BA_ "U_V713AV_MY2022_Rx" SG_ 76 ThirdRowBucklePsngr 1;
BA_ "U_V713N_MY2022_Rx" SG_ 76 ThirdRowBucklePsngr 1;
BA_ "GenSigStartValue" SG_ 76 ThirdRowBucklePsngr 3;
BA_ "U_V710_MY2023_Rx" SG_ 76 ThirdRowBuckleMid 1;
BA_ "U_P708_MY2023_Rx" SG_ 76 ThirdRowBuckleMid 1;
BA_ "U_V713AV_MY2022_Rx" SG_ 76 ThirdRowBuckleMid 1;
BA_ "U_V713N_MY2022_Rx" SG_ 76 ThirdRowBuckleMid 1;
BA_ "GenSigStartValue" SG_ 76 ThirdRowBuckleMid 3;
BA_ "U_V710_MY2023_Rx" SG_ 76 ThirdRowBuckleDriver 1;
BA_ "U_P708_MY2023_Rx" SG_ 76 ThirdRowBuckleDriver 1;
BA_ "U_V713AV_MY2022_Rx" SG_ 76 ThirdRowBuckleDriver 1;
BA_ "U_V713N_MY2022_Rx" SG_ 76 ThirdRowBuckleDriver 1;
BA_ "GenSigStartValue" SG_ 76 ThirdRowBuckleDriver 3;
BA_ "U_V710_MY2023_Rx" SG_ 76 SecondRowBucklePsngr 1;
BA_ "U_P708_MY2023_Rx" SG_ 76 SecondRowBucklePsngr 1;
BA_ "U_V713AV_MY2022_Rx" SG_ 76 SecondRowBucklePsngr 1;
BA_ "U_V713N_MY2022_Rx" SG_ 76 SecondRowBucklePsngr 1;
BA_ "GenSigStartValue" SG_ 76 SecondRowBucklePsngr 3;
BA_ "U_V710_MY2023_Rx" SG_ 76 SecondRowBuckleMid 1;
BA_ "U_P708_MY2023_Rx" SG_ 76 SecondRowBuckleMid 1;
BA_ "U_V713AV_MY2022_Rx" SG_ 76 SecondRowBuckleMid 1;
BA_ "U_V713N_MY2022_Rx" SG_ 76 SecondRowBuckleMid 1;
BA_ "GenSigStartValue" SG_ 76 SecondRowBuckleMid 3;
BA_ "U_V710_MY2023_Rx" SG_ 76 SecondRowBuckleDriver 1;
BA_ "U_P708_MY2023_Rx" SG_ 76 SecondRowBuckleDriver 1;
BA_ "U_V713AV_MY2022_Rx" SG_ 76 SecondRowBuckleDriver 1;
BA_ "U_V713N_MY2022_Rx" SG_ 76 SecondRowBuckleDriver 1;
BA_ "GenSigStartValue" SG_ 76 SecondRowBuckleDriver 3;
BA_ "U_V710_MY2023_Rx" SG_ 76 FirstRowBuckleDriver 1;
BA_ "U_P708_MY2023_Rx" SG_ 76 FirstRowBuckleDriver 1;
BA_ "U_V713AV_MY2022_Rx" SG_ 76 FirstRowBuckleDriver 1;
BA_ "U_V713N_MY2022_Rx" SG_ 76 FirstRowBuckleDriver 1;
BA_ "GenSigStartValue" SG_ 76 FirstRowBuckleDriver 3;
BA_ "U_V710_MY2023_Rx" SG_ 76 RILReq 1;
BA_ "U_P708_MY2023_Rx" SG_ 76 RILReq 1;
BA_ "U_V713AV_MY2022_Rx" SG_ 76 RILReq 1;
BA_ "U_V713N_MY2022_Rx" SG_ 76 RILReq 1;
BA_ "U_V710_MY2023_Rx" SG_ 76 FirstRowBucklePsngr 1;
BA_ "U_P708_MY2023_Rx" SG_ 76 FirstRowBucklePsngr 1;
BA_ "U_V713AV_MY2022_Rx" SG_ 76 FirstRowBucklePsngr 1;
BA_ "U_V713N_MY2022_Rx" SG_ 76 FirstRowBucklePsngr 1;
BA_ "GenSigStartValue" SG_ 76 FirstRowBucklePsngr 3;
BA_ "U_P708_MY2023_Rx" SG_ 76 RstrnImpactEvntStatus 1;
BA_ "WakeupSignal" SG_ 76 RstrnImpactEvntStatus 1;
BA_ "U_V710_MY2023_Rx" SG_ 76 PsngrFrntDetct_D_Actl 1;
BA_ "U_P708_MY2023_Rx" SG_ 76 PsngrFrntDetct_D_Actl 1;
BA_ "U_V713AV_MY2022_Rx" SG_ 76 PsngrFrntDetct_D_Actl 1;
BA_ "U_V713N_MY2022_Rx" SG_ 76 PsngrFrntDetct_D_Actl 1;
BA_ "GenSigStartValue" SG_ 76 PsngrFrntDetct_D_Actl 3;
BA_ "GenSigStartValue" SG_ 76 PassRstrnInd_Req 3;
BA_ "U_P708_MY2023_Rx" SG_ 76 EDRTriggerEvntSync 1;
BA_ "U_V713AV_MY2022_Rx" SG_ 76 EDRTriggerEvntSync 1;
BA_ "U_V713N_MY2022_Rx" SG_ 76 EDRTriggerEvntSync 1;
BA_ "U_V710_MY2023_Rx" SG_ 1034 VehicleGGCCData 1;
BA_ "U_P708_MY2023_Rx" SG_ 1034 VehicleGGCCData 1;
BA_ "U_V713AV_MY2022_Rx" SG_ 1034 VehicleGGCCData 1;
BA_ "U_V713N_MY2022_Rx" SG_ 1034 VehicleGGCCData 1;
BA_ "U_P708_MY2023_Rx" SG_ 1069 IsaOffst_D_Stat 1;
BA_ "U_V713AV_MY2022_Rx" SG_ 1069 IsaOffst_D_Stat 1;
BA_ "U_V713N_MY2022_Rx" SG_ 1069 IsaOffst_D_Stat 1;
BA_ "U_V710_MY2023_Rx" SG_ 1069 ReFuelSysStat_D_Dsply 1;
BA_ "U_P708_MY2023_Rx" SG_ 1069 ReFuelSysStat_D_Dsply 1;
BA_ "U_V713AV_MY2022_Rx" SG_ 1069 ReFuelSysStat_D_Dsply 1;
BA_ "U_V713N_MY2022_Rx" SG_ 1069 ReFuelSysStat_D_Dsply 1;
BA_ "WakeupSignal" SG_ 1069 ReFuelSysStat_D_Dsply 1;
BA_ "U_V710_MY2023_Rx" SG_ 1069 SlMde_D_Stat 1;
BA_ "U_P708_MY2023_Rx" SG_ 1069 SlMde_D_Stat 1;
BA_ "U_V713AV_MY2022_Rx" SG_ 1069 SlMde_D_Stat 1;
BA_ "U_V713N_MY2022_Rx" SG_ 1069 SlMde_D_Stat 1;
BA_ "U_V710_MY2023_Rx" SG_ 1069 SlMde_D_RqDsply 1;
BA_ "U_P708_MY2023_Rx" SG_ 1069 SlMde_D_RqDsply 1;
BA_ "U_V713AV_MY2022_Rx" SG_ 1069 SlMde_D_RqDsply 1;
BA_ "U_V713N_MY2022_Rx" SG_ 1069 SlMde_D_RqDsply 1;
BA_ "U_V713AV_MY2022_Rx" SG_ 1069 ULoSrcOnPlg_B_Cmd 1;
BA_ "U_V713N_MY2022_Rx" SG_ 1069 ULoSrcOnPlg_B_Cmd 1;
BA_ "U_V713AV_MY2022_Rx" SG_ 1069 EngAirIn_Te_Actl 1;
BA_ "U_V713N_MY2022_Rx" SG_ 1069 EngAirIn_Te_Actl 1;
BA_ "U_V713AV_MY2022_Rx" SG_ 1069 GrllShtrPos_B_Falt 1;
BA_ "U_V713N_MY2022_Rx" SG_ 1069 GrllShtrPos_B_Falt 1;
BA_ "U_V710_MY2023_Rx" SG_ 1069 EngMsgTxt_D_Rq 1;
BA_ "U_P708_MY2023_Rx" SG_ 1069 EngMsgTxt_D_Rq 1;
BA_ "U_V713AV_MY2022_Rx" SG_ 1069 EngMsgTxt_D_Rq 1;
BA_ "U_V713N_MY2022_Rx" SG_ 1069 EngMsgTxt_D_Rq 1;
BA_ "U_V713AV_MY2022_Rx" SG_ 1069 EngClnt_Te_ActlDiag 1;
BA_ "U_V713N_MY2022_Rx" SG_ 1069 EngClnt_Te_ActlDiag 1;
BA_ "U_V713AV_MY2022_Rx" SG_ 1069 ThrPos_Pc_CalcDiag 1;
BA_ "U_V713N_MY2022_Rx" SG_ 1069 ThrPos_Pc_CalcDiag 1;
BA_ "U_V713AV_MY2022_Rx" SG_ 1069 EngLoad_Pc_CalcDiag 1;
BA_ "U_V713N_MY2022_Rx" SG_ 1069 EngLoad_Pc_CalcDiag 1;
BA_ "U_V713AV_MY2022_Rx" SG_ 1069 ApedPos_Pc_ActlDiag 1;
BA_ "U_V713N_MY2022_Rx" SG_ 1069 ApedPos_Pc_ActlDiag 1;
BA_ "U_V713AV_MY2022_Rx" SG_ 1069 TracKeyMdeEnbl_B_Stat 1;
BA_ "U_V713N_MY2022_Rx" SG_ 1069 TracKeyMdeEnbl_B_Stat 1;
BA_ "U_V713AV_MY2022_Rx" SG_ 1069 GrllShtrPos_D_Cmd 1;
BA_ "U_V713N_MY2022_Rx" SG_ 1069 GrllShtrPos_D_Cmd 1;
BA_ "U_V713AV_MY2022_Rx" SG_ 1057 FohEng_D_Rq 1;
BA_ "U_V713N_MY2022_Rx" SG_ 1057 FohEng_D_Rq 1;
BA_ "GenSigStartValue" SG_ 1057 FohEng_D_Rq 2;
BA_ "U_V713AV_MY2022_Rx" SG_ 1057 EngIdlShutDwnTxt_D_Rq 1;
BA_ "U_V713N_MY2022_Rx" SG_ 1057 EngIdlShutDwnTxt_D_Rq 1;
BA_ "U_V710_MY2023_Rx" SG_ 1057 EngIdlShutDown_D_Stat 1;
BA_ "U_P708_MY2023_Rx" SG_ 1057 EngIdlShutDown_D_Stat 1;
BA_ "U_V713AV_MY2022_Rx" SG_ 1057 EngIdlShutDown_D_Stat 1;
BA_ "U_V713N_MY2022_Rx" SG_ 1057 EngIdlShutDown_D_Stat 1;
BA_ "U_V710_MY2023_Rx" SG_ 1057 FUEL_ALCOHOL_PERCNT 1;
BA_ "U_V713AV_MY2022_Rx" SG_ 1057 FUEL_ALCOHOL_PERCNT 1;
BA_ "U_V713N_MY2022_Rx" SG_ 1057 FUEL_ALCOHOL_PERCNT 1;
BA_ "GenSigStartValue" SG_ 1057 FUEL_ALCOHOL_PERCNT 255;
BA_ "U_V713AV_MY2022_Rx" SG_ 1057 TrnTotTq_Rt_Est 1;
BA_ "U_V713N_MY2022_Rx" SG_ 1057 TrnTotTq_Rt_Est 1;
BA_ "U_V713AV_MY2022_Rx" SG_ 1057 TrnTotLss_Tq_Est 1;
BA_ "U_V713N_MY2022_Rx" SG_ 1057 TrnTotLss_Tq_Est 1;
BA_ "U_V710_MY2023_Rx" SG_ 1057 ECMMILRequest 1;
BA_ "U_P708_MY2023_Rx" SG_ 1057 ECMMILRequest 1;
BA_ "U_V713AV_MY2022_Rx" SG_ 1057 ECMMILRequest 1;
BA_ "U_V713N_MY2022_Rx" SG_ 1057 ECMMILRequest 1;
BA_ "U_V713AV_MY2022_Rx" SG_ 1057 AirCondFluidHi_P_Actl 1;
BA_ "U_V713N_MY2022_Rx" SG_ 1057 AirCondFluidHi_P_Actl 1;
BA_ "U_V710_MY2023_Rx" SG_ 1057 OilPressureWarning 1;
BA_ "U_P708_MY2023_Rx" SG_ 1057 OilPressureWarning 1;
BA_ "U_V713AV_MY2022_Rx" SG_ 1057 OilPressureWarning 1;
BA_ "U_V713N_MY2022_Rx" SG_ 1057 OilPressureWarning 1;
BA_ "U_V713AV_MY2022_Rx" SG_ 1057 VehVLimStat_D_Actl 1;
BA_ "U_V713N_MY2022_Rx" SG_ 1057 VehVLimStat_D_Actl 1;
BA_ "U_V713AV_MY2022_Rx" SG_ 1057 VehVLimActv_B_Actl 1;
BA_ "U_V713N_MY2022_Rx" SG_ 1057 VehVLimActv_B_Actl 1;
BA_ "U_V713AV_MY2022_Rx" SG_ 1057 CoolantFanStepAct 1;
BA_ "U_V713N_MY2022_Rx" SG_ 1057 CoolantFanStepAct 1;
VAL_ 549 BattTracLoThres_D_Rq2 7 "NotUsed" 6 "Thres80km_50mi" 5 "Thres50km_31mi" 4 "Thres30km_18mi" 3 "Thres50mi_80km" 2 "Thres30mi_48km" 1 "Thres20mi_32km" 0 "Null" ;
VAL_ 549 NavIod_D_Rq 7 "NotUsed_5" 6 "NotUsed_4" 5 "NotUsed_3" 4 "NotUsed_2" 3 "NotUsed_1" 2 "ModeChange" 1 "VideoOutput" 0 "NoRequest" ;
VAL_ 549 StrtInGearOk_D_Stat 3 "NotUsed" 2 "Accepted" 1 "NotAccepted" 0 "Null" ;
VAL_ 549 WwaActv_B_Stat 1 "Active" 0 "Inactive" ;
VAL_ 549 IPC_MyKeyVolLimit_St 0 "Invalid" 1 "Off" 2 "On" ;
VAL_ 549 HudVertSzMnuOn_B_Rq 1 "On" 0 "Off" ;
VAL_ 549 HudVertMnuOn_B_Rq 1 "Yes" 0 "No" ;
VAL_ 549 HudRotatMnuOn_B_Rq 1 "Yes" 0 "No" ;
VAL_ 549 HudCntntMnuOn_B_Rq 1 "On" 0 "Off" ;
VAL_ 549 HudBrightMnuOn_B_Rq 1 "Yes" 0 "No" ;
VAL_ 549 HdcOn_B_Rq 1 "On" 0 "Off" ;
VAL_ 549 IPC_Attn_Info_Audio 7 "Unknown" 6 "Attenuation_6" 5 "Attenuation_5" 4 "Attenuation_4" 3 "Attenuation_3" 2 "Attenuation_2" 1 "Attenuation_1" 0 "No_Attenuation_of_Audio" ;
VAL_ 549 BeltminderAudioMute 2 "On" 1 "Off" 0 "Invalid" ;
VAL_ 549 Power_Up_Chime_Modules 1 "Active" 0 "Inactive" ;
VAL_ 549 Chime_Source 2 "Cluster" 1 "Infotainment_Sys" 0 "Invalid" ;
VAL_ 549 CCOI_PolicyClient_St2 15 "NotUsed_4" 14 "NotUsed_3" 13 "NotUsed_2" 12 "NotUsed_1" 11 "DataStorageError" 10 "StateMachineInconsistent" 9 "UnrecoverableSyncError" 8 "OnBoardSyncFailed" 7 "OnBoardImplemented" 6 "OnBoardSynchronized" 5 "OnBoardSynchronizing" 4 "OnBoardSyncNeeded" 3 "OffBoardUpdatePending" 2 "OnBoardUpdatePending" 1 "Waiting" 0 "Null" ;
VAL_ 549 FactoryReset_Rq2 1 "ResetFactoryDefaults" 0 "Inactive" ;
VAL_ 549 IPC_New_Attn_Event 1 "Active" 0 "Inactive" ;
VAL_ 549 MetricActv_B_Dsply 1 "Active" 0 "Inactive" ;
VAL_ 765 BalrSwtch_D_Stat 3 "NotUsed" 2 "Pressed" 1 "NotPressed" 0 "Null" ;
VAL_ 765 BalrMde_D_Rq 3 "High" 2 "Medium" 1 "Low" 0 "Null" ;
VAL_ 765 RstrnOnPsngr_D_RqMnu 15 "Faulty" 14 "NotUsed_11" 13 "NotUsed_10" 12 "ConfiguredOff" 11 "NotUsed_9" 10 "On" 9 "NotUsed_8" 8 "NotUsed_7" 7 "NotUsed_6" 6 "NotUsed_5" 5 "Off" 4 "NotUsed_4" 3 "NotUsed_3" 2 "NotUsed_2" 1 "NotUsed_1" 0 "NoAction" ;
VAL_ 765 WaitToStartLamp_D_Falt 3 "NotUsed" 2 "Wait_to_start_lamp_failed" 1 "Diagnosis_not_ready" 0 "Wait_to_start_lamp_OK" ;
VAL_ 765 EsaOn_B_Rq 1 "On" 0 "Off" ;
VAL_ 765 BttOn_B_Rq 1 "On" 0 "Off" ;
VAL_ 765 Btt_L_Actl 127 "Faulty" 126 "NoDataExists" ;
VAL_ 765 RearDiffLck_D_RqArb 3 "Faulty" 2 "NotUsed" 1 "On" 0 "Off" ;
VAL_ 765 AwdMde_D_RqArb 7 "Faulty" 6 "NotUsed2" 5 "NoRequest" 4 "Neutral" 3 "FourByFourLow" 2 "FourByFourHigh" 1 "FourByFourAuto" 0 "FourByTwo" ;
VAL_ 765 SelDrvMdeTxtReset_B_Rq 1 "Yes" 0 "No" ;
VAL_ 765 AutoTowAllw_D_RqMnu 3 "TowHaulCommandedOn" 2 "AutoTowHaulEnabled" 1 "AutoTowHaulDisabled" 0 "NoSelection" ;
VAL_ 765 DrvInputRequired_B_Rq 1 "Yes" 0 "No" ;
VAL_ 765 SelDrvMdeDsply_B_Avail 1 "Available" 0 "NotAvailable" ;
VAL_ 765 EngExhMdeQuiet_D_Rq 3 "Faulty" 2 "QuietExhaust" 1 "LoudExhaust" 0 "Null" ;
VAL_ 765 AirSusp_D_RqDrv 3 "NotUsed" 2 "On" 1 "Off" 0 "NoModeSelected" ;
VAL_ 765 Mc_VehUntTrpCoUsrSel_St 0 "TripComputer_metric" 1 "TripComputer_imperial" ;
VAL_ 765 Mc_VehUnitTempUsrSel_St 0 "Temperature_deg_c" 1 "Temperature_deg_f" ;
VAL_ 765 Mc_VehDayNightUsrSel_St 2 "Night" 1 "Day" 0 "Invalid" ;
VAL_ 765 Mc_VehTimeFrmtUsrSel_St 2 "24h_mode" 1 "12h_mode" 0 "Invalid" ;
VAL_ 765 Mc_VehThemeUsrSel_St 2 "Theme_2" 1 "Theme_1" 0 "Invalid" ;
VAL_ 765 Mc_VehLangUsrSel_St 33 "Ukrainian" 32 "Indian_English" 31 "Thai" 30 "Slovak" 29 "Arabic" 28 "Taiwanese" 27 "Mandarin_Chinese" 26 "Korean" 25 "AU_English" 24 "Japanese" 23 "Braz_Portuguese" 22 "EU_Portuguese" 21 "Finish" 20 "Norwegian" 19 "Danish" 18 "Swedish" 17 "Hungarian" 16 "Greek" 15 "Czech" 14 "Polish" 13 "Flemish" 12 "Dutch" 11 "Russian" 10 "Turkish" 9 "Mex_Spanish" 8 "EU_Spanish" 7 "Cana_French" 6 "EU_French" 5 "Italian" 4 "German" 3 "NA_English" 2 "UK_English" 1 "Unknown" 0 "Invalid" ;
VAL_ 765 AwdRnge_D_ActlIpc 7 "Unknown" 6 "High_Range_2wd" 5 "High_Range_Auto" 4 "High_Range_Locked" 3 "Neutral" 2 "Low_Range_2wd" 1 "Low_Range_Auto" 0 "Low_Range_Locked" ;
VAL_ 765 AwdDrvMde_D_Rq 7 "Faulty" 6 "NotAvailable" 5 "RockCrawl" 4 "Baja" 3 "MudAndSand" 2 "Weather" 1 "Sport" 0 "Normal" ;
VAL_ 765 EngExhMdeQuiet_D2_Rq 7 "NotUsed_3" 6 "NotUsed_2" 5 "NotUsed_1" 4 "Track" 3 "Sport" 2 "Normal" 1 "Stealth" 0 "Null" ;
VAL_ 765 BrkLineLck_D_Rq 3 "Off" 2 "Engage" 1 "Initiate" 0 "NoRequest" ;
VAL_ 765 EdmSailMde_B_RqDrv 1 "On" 0 "Off" ;
VAL_ 765 Running_Board_Cmd 3 "Unused" 2 "Manually_Deployed" 1 "All_Enabled" 0 "All_Disabled" ;
VAL_ 508 Mc_DB1GtInfNbrOfItms_Rq 1 "OneItem" 0 "Standard" ;
VAL_ 508 Mc_DB1GetInfSetConf_Rq 31 "UnknownActive" 30 "Reserved_last" 9 "Reserved" 8 "Podcast" 7 "Audiobook" 6 "Composer" 5 "Track" 4 "Genre" 3 "Album" 2 "Artist" 1 "Playlist" 0 "Root" ;
VAL_ 508 Mc_DB1GetInfSetFilt3_Rq 1023 "All" 1022 "SIIndex_1022" 1 "SIIndex_1" 0 "NotEngaged" ;
VAL_ 508 Mc_DB1GetInfSetFilt2_Rq 65535 "All" 65534 "SIIndex_65534" 1 "SIIndex_1" 0 "NotEngaged" ;
VAL_ 508 Mc_DB1GetInfSetFilt1_Rq 65535 "All" 65534 "SIIndex_65534" 1 "SIIndex_1" 0 "NotEngaged" ;
VAL_ 507 Mc_DB1SetTrkSetConf_Rq 9 "Reserved" 8 "Podcast" 7 "Audiobook" 6 "Composer" 5 "Track" 4 "Genre" 3 "Album" 2 "Artist" 1 "Playlist" 0 "Root" 31 "UnknownActive" 30 "Reserved_last" ;
VAL_ 507 Mc_DB1SetTrkSetFilt3_Rq 1023 "All" 1022 "SIIndex_1022" 1 "SIIndex_1" 0 "NotEngaged" ;
VAL_ 507 Mc_DB1SetTrkSetFilt2_Rq 65535 "All" 65534 "SIIndex_65534" 1 "SIIndex_1" 0 "NotEngaged" ;
VAL_ 507 Mc_DB1SetTrkSetFilt1_Rq 65535 "All" 65534 "SIIndex_65534" 1 "SIIndex_1" 0 "NotEngaged" ;
VAL_ 506 Mc_AudioSourceSel3_Rq 4 "Reserved" 5 "SDcard" 3 "USB" 2 "BTAudio" 1 "CD" 0 "Inactive" ;
VAL_ 505 Mc_AudioSourceSel2_Rq 4 "Reserved" 5 "SDcard" 3 "USB" 2 "BTAudio" 1 "CD" 0 "Inactive" ;
VAL_ 505 Mc_CutItem2_Rq 3 "Inactive" 2 "ThreeQuarterFromBeginOneQ" 1 "End" 0 "Beginning" ;
VAL_ 505 Mc_FolderContent_Rq 2 "Inactive" 1 "ReqContentParentFolderOf" 0 "ReqContentParameterFolder" ;
VAL_ 403 McLangSel2_Rq 33 "Ukrainian" 32 "Indian_English" 31 "Thai" 30 "Slovak" 29 "Arabic" 28 "Taiwanese" 27 "Mandarin_Chinese" 26 "Korean" 25 "AU_English" 24 "Japanese" 23 "Braz_Portuguese" 22 "EU_Portuguese" 21 "Finish" 20 "Norwegian" 19 "Danish" 18 "Swedish" 17 "Hungarian" 16 "Greek" 15 "Czech" 14 "Polish" 13 "Flemish" 12 "Dutch" 11 "Russian" 10 "Turkish" 9 "Mex_Spanish" 8 "EU_Spanish" 7 "Cana_French" 6 "EU_French" 5 "Italian" 4 "German" 3 "NA_English" 2 "UK_English" 1 "Unknown" 0 "Invalid" ;
VAL_ 403 DealerCall_B_Rq 1 "Yes" 0 "Null" ;
VAL_ 403 Mc_RepeatGuidance_Rq 1 "Active" 0 "Inactive" ;
VAL_ 403 Mc_CancelRoute_Rq 1 "Cancel" 0 "Inactive" ;
VAL_ 403 Mc_CancelCurrWaypt_Rq 1 "Cancel" 0 "Inactive" ;
VAL_ 403 Mc_TextMessage_Rq 3 "Cancel" 2 "Ignore" 1 "Listen" 0 "Invalid" ;
VAL_ 403 Mc_BTInCallOptions_Rq 6 "EndHoldCall" 5 "HoldCall" 4 "GotoHandsfreeMode" 3 "GotoPrivacyMode" 2 "JoinCalls" 1 "SwitchCalls" 0 "Inactive" ;
VAL_ 403 Mc_PhMicrophoneMute_Rq 3 "Reserved" 2 "MicrophoneUnmute" 1 "MicrophoneMute" 0 "Inactive" ;
VAL_ 403 Mc_LangSel_Rq 31 "Thai" 30 "Slovak" 29 "Arabic" 28 "Taiwanese" 27 "Mandarin_Chinese" 26 "Korean" 25 "AU_English" 24 "Japanese" 23 "Braz_Portuguese" 22 "EU_Portuguese" 21 "Finish" 20 "Norwegian" 19 "Danish" 18 "Swedish" 17 "Hungarian" 16 "Greek" 15 "Czech" 14 "Polish" 13 "Flemish" 12 "Dutch" 11 "Russian" 10 "Turkish" 9 "Mex_Spanish" 8 "EU_Spanish" 7 "Cana_French" 6 "EU_French" 5 "Italian" 4 "German" 3 "NA_English" 2 "UK_English" 1 "Unknown" 0 "Invalid" ;
VAL_ 401 Bezel_Beeps_Rq 0 "Inactive" 2 "Disable" 1 "Enable" ;
VAL_ 401 Disp_VehUntTripCoUsrSel 3 "Inactive" 1 "Imperial" 0 "Metric" ;
VAL_ 401 Disp_VehUnitTempUsrSel 3 "Inactive" 1 "Fahrenheit" 0 "Celsius" ;
VAL_ 401 Disp_LangSel_Rq 31 "Thai" 30 "Slovak" 29 "Arabic" 28 "Taiwanese" 27 "Mandarin_Chinese" 26 "Korean" 25 "AU_English" 24 "Japanese" 23 "Braz_Portuguese" 22 "EU_Portuguese" 21 "Finish" 20 "Norwegian" 19 "Danish" 18 "Swedish" 17 "Hungarian" 16 "Greek" 15 "Czech" 14 "Polish" 13 "Flemish" 12 "Dutch" 11 "Russian" 10 "Turkish" 9 "Mex_Spanish" 8 "EU_Spanish" 7 "Cana_French" 6 "EU_French" 5 "Italian" 4 "German" 3 "NA_English" 2 "UK_English" 1 "Unknown" 0 "Invalid" ;
VAL_ 401 Disp_LangSel2_Rq 33 "Ukrainian" 32 "Indian_English" 31 "Thai" 30 "Slovak" 29 "Arabic" 28 "Taiwanese" 27 "Mandarin_Chinese" 26 "Korean" 25 "AU_English" 24 "Japanese" 23 "Braz_Portuguese" 22 "EU_Portuguese" 21 "Finish" 20 "Norwegian" 19 "Danish" 18 "Swedish" 17 "Hungarian" 16 "Greek" 15 "Czech" 14 "Polish" 13 "Flemish" 12 "Dutch" 11 "Russian" 10 "Turkish" 9 "Mex_Spanish" 8 "EU_Spanish" 7 "Cana_French" 6 "EU_French" 5 "Italian" 4 "German" 3 "NA_English" 2 "UK_English" 1 "Unknown" 0 "Invalid" ;
VAL_ 1143 ConsTipUnitPt_D_Dsply 3 "NotUsed" 2 "FuelEconomy" 1 "Distance" 0 "Percentage" ;
VAL_ 1143 ConsTipTot_Pc_Dsply 1023 "Faulty" 1022 "NoDataExists" ;
VAL_ 1143 ChrgCompltMsgTxt_D_Rq 3 "NotUsed_1" 2 "ChargeToFull" 1 "ChargeToFastChargeLimit" 0 "DefaultLabel" ;
VAL_ 1142 ConsTipV_No_Dsply 1023 "Faulty" 1022 "NoDataExists" ;
VAL_ 1142 ConsTipMsg3_D_Dsply 15 "NotUsed10" 14 "NotUsed9" 13 "NotUsed8" 12 "NotUsed7" 11 "NotUsed6" 10 "NotUsed5" 9 "NotUsed4" 8 "NotUsed3" 7 "NotUsed2" 6 "NotUsed1" 5 "ReduceIdleTime" 4 "ClimateUsage" 3 "VehicleSpeed" 2 "Deceleration" 1 "Acceleration" 0 "NoDisplay" ;
VAL_ 1142 ConsTipMsg2_D_Dsply 15 "NotUsed10" 14 "NotUsed9" 13 "NotUsed8" 12 "NotUsed7" 11 "NotUsed6" 10 "NotUsed5" 9 "NotUsed4" 8 "NotUsed3" 7 "NotUsed2" 6 "NotUsed1" 5 "ReduceIdleTime" 4 "ClimateUsage" 3 "VehicleSpeed" 2 "Deceleration" 1 "Acceleration" 0 "NoDisplay" ;
VAL_ 1142 ConsTipMsg1_D_Dsply 15 "NotUsed10" 14 "NotUsed9" 13 "NotUsed8" 12 "NotUsed7" 11 "NotUsed6" 10 "NotUsed5" 9 "NotUsed4" 8 "NotUsed3" 7 "NotUsed2" 6 "NotUsed1" 5 "ReduceIdleTime" 4 "ClimateUsage" 3 "VehicleSpeed" 2 "Deceleration" 1 "Acceleration" 0 "NoDisplay" ;
VAL_ 1142 ConsTipDecel_No_Dsply 1023 "Faulty" 1022 "NoDataExists" ;
VAL_ 1142 ConsTipA_No_Dsply 1023 "Faulty" 1022 "NoDataExists" ;
VAL_ 973 PersCtaSplitView_D_Stat 3 "EnabledFull" 2 "Enabled_180SwitchOnly" 1 "Disabled" 0 "Null" ;
VAL_ 973 LaSysOffStat_D_Dsply 3 "Level_3" 2 "Level_2" 1 "Level_1" 0 "Level_0" ;
VAL_ 973 TsrVl1RstrcMsgTxt2_D_Rq 7 "NotUsed" 6 "Time" 5 "Trailer" 4 "Snow" 3 "RainWet" 2 "NoRecognizableRestrictn" 1 "NoSpeedLimitRestrictn" 0 "Null" ;
VAL_ 973 TsrVl2RstrcMsgTxt2_D_Rq 7 "NotUsed" 6 "Time" 5 "Trailer" 4 "Snow" 3 "RainWet" 2 "NoRecognizableRestrictn" 1 "NoSpeedLimitRestrictn" 0 "Null" ;
VAL_ 973 TsrVl2PrmntMsgTxt_D_Rq 3 "NotUsed" 2 "ShowPermanentlyWithSupp" 1 "ShowPermanentlyWithoutSupp" 0 "DoNotShowSignPermanent" ;
VAL_ 973 TsrVl1PrmntMsgTxt_D_Rq 3 "NotUsed" 2 "ShowPermanentlyWithSupp" 1 "ShowPermanentlyWithoutSupp" 0 "DoNotShowSignPermanent" ;
VAL_ 973 TsrOvtkMsgTxt2_D_Rq 15 "NotUsed5" 14 "NotUsed4" 13 "NotUsed3" 12 "NotUsed2" 11 "NotUsed1" 10 "LimForTrucksCancelled" 9 "LimForTrucksWoQlfdRstrc" 8 "LimForTrucksWithoutRstrc" 7 "LimAllCancelled" 6 "LimAllWithRstrcTime" 5 "LimAllWithRstrcTrailer" 4 "LimAllWithRstrcSnow" 3 "LimAllWithRstrcRain" 2 "LimAllWithoutQlfdRstrc" 1 "LimAllWithoutRestriction" 0 "OvertakingAllowed" ;
VAL_ 973 WwaWarn_B_Rq 1 "On" 0 "Off" ;
VAL_ 973 RoadSignRgltry_D_Dsply 3 "NoEntry" 2 "Stop" 1 "Yield" 0 "None" ;
VAL_ 973 TsrVlUnitMsgTxt_D_Rq 3 "NoDataExists" 2 "Mph" 1 "Kph" 0 "Null" ;
VAL_ 973 TsrVLim2MsgTxt_D_Rq 255 "NoLimit" 254 "NotUsed2" 253 "NotUsed1" 252 "NotToBeDisplayed" 251 "LimitCancelled" 31 "1F_FA_Message31_250" 30 "Message30" 29 "Message29" 28 "Message28" 27 "Message27" 26 "Message26" 25 "Message25" 24 "Message24" 23 "Message23" 22 "Message22" 21 "Message21" 20 "Message20" 19 "Message19" 18 "Message18" 17 "Message17" 16 "Message16" 15 "Message15" 14 "Message14" 13 "Message13" 12 "Message12" 11 "Message11" 10 "Message10" 9 "Message9" 8 "Message8" 7 "Message7" 6 "Message6" 5 "Message5" 4 "Message4" 3 "Message3" 2 "Message2" 1 "Message1" 0 "Null" ;
VAL_ 973 TsrVLim1MsgTxt_D_Rq 255 "NoLimit" 254 "NotUsed2" 253 "NotUsed1" 252 "NotToBeDisplayed" 251 "LimitCancelled" 31 "1F_FA_Message31_250" 30 "Message30" 29 "Message29" 28 "Message28" 27 "Message27" 26 "Message26" 25 "Message25" 24 "Message24" 23 "Message23" 22 "Message22" 21 "Message21" 20 "Message20" 19 "Message19" 18 "Message18" 17 "Message17" 16 "Message16" 15 "Message15" 14 "Message14" 13 "Message13" 12 "Message12" 11 "Message11" 10 "Message10" 9 "Message9" 8 "Message8" 7 "Message7" 6 "Message6" 5 "Message5" 4 "Message4" 3 "Message3" 2 "Message2" 1 "Message1" 0 "Null" ;
VAL_ 973 TsrVl2StatMsgTxt_D_Rq 3 "LimitOutdated" 2 "LimitReiable" 1 "LimitChanged" 0 "Null" ;
VAL_ 973 TsrVl2RstrcMsgTxt_D_Rq 3 "NotUsed" 2 "NoRecognizableRestriction" 1 "NoSpeedLimitRestriction" 0 "Null" ;
VAL_ 973 TsrVl1StatMsgTxt_D_Rq 3 "LimitOutdated" 2 "LimitReiable" 1 "LimitChanged" 0 "Null" ;
VAL_ 973 TsrVl1RstrcMsgTxt_D_Rq 3 "NotUsed" 2 "NoRecognizableRestriction" 1 "NoSpeedLimitRestriction" 0 "Null" ;
VAL_ 973 TsrStatMsgTxt_D_Rq 7 "NotUsed" 6 "NoDataExists" 5 "TSR_Error" 4 "Available_NavigationOnly" 3 "Available_CameraOnly" 2 "Available_FusionMode" 1 "TSR_Off" 0 "Null" ;
VAL_ 973 TsrOvtkStatMsgTxt_D_Rq 3 "LimitOutdated" 2 "LimitReiable" 1 "LimitChanged" 0 "Null" ;
VAL_ 973 TsrOvtkMsgTxt_D_Rq 7 "LimForTrucksCancelled" 6 "LimForTrucksWoQlfdRstrc" 5 "LimForTrucksWithoutRstrc" 4 "LimAllCancelled" 3 "LimAllWithoutQlfdRstrc" 2 "LimAllWithoutRestriction" 1 "OvertakingAllowed" 0 "Null" ;
VAL_ 973 TsrOswWarnMsgTxt_D_Rq 3 "NotUsed" 2 "True" 1 "False" 0 "Null" ;
VAL_ 973 TsrMsgTxt_D_Rq 15 "NotUsed6" 14 "NotUsed5" 13 "NotUsed4" 12 "NotUsed3" 11 "NotUsed2" 10 "NotUsed1" 9 "RecgnzdSignNotUsblForDsply" 8 "LimitedSystemPerformance" 7 "OffRoad" 6 "RegionNotSupported" 5 "CountryNotSupported" 4 "WrngNavDatIncompDatCarrier" 3 "NoNavDataAvailable" 2 "NoNavAvailableSwitchedOff" 1 "NoInformationAllOK" 0 "Null" ;
VAL_ 756 AdjustableChimeVol2_Rq 15 "NotUsed_3" 14 "NotUsed_2" 13 "NotUsed_1" 12 "LevelPlus6" 11 "LevelPlus5" 10 "LevelPlus4" 9 "LevelPlus3" 8 "LevelPlus2" 7 "LevelPlus1" 6 "LevelMinus1" 5 "LevelMinus2" 4 "LevelMinus3" 3 "LevelMinus4" 2 "LevelMinus5" 1 "LevelMinus6" 0 "DefaultVolume" ;
VAL_ 756 Chime_Time_Criticality2 2 "Low" 1 "High" 0 "Inactive" ;
VAL_ 756 Chime_Occurence2 15 "Continuous" 14 "14Repititions" 13 "13Repititions" 12 "12Repititions" 11 "11Repititions" 10 "10Repititions" 9 "9Repititions" 8 "8Repititions" 7 "7Repititions" 6 "6Repititions" 5 "5Repititions" 4 "4Repititions" 3 "3Repititions" 2 "2Repititions" 1 "PlayOnce" 0 "Inactive" ;
VAL_ 756 Chime_Directionality2 3 "RearSpeakers" 2 "FrontSpeakers" 1 "ALL" 0 "Inactive" ;
VAL_ 756 Chime2Id_No_Rq 255 "Id255" 250 "Id250" 240 "Id240" 220 "Id220" 200 "Id200" 180 "Id180" 160 "Id160" 140 "Id140" 120 "Id120" 100 "Id100" 90 "Id90" 80 "Id80" 70 "Id70" 60 "Id60" 50 "Id50" 40 "Id40" 30 "Id30" 20 "Id20" 10 "Id10" 1 "Id1" 0 "Inactive" ;
VAL_ 544 ChimeId_No_Rq 255 "Id255" 250 "Id250" 240 "Id240" 220 "Id220" 200 "Id200" 180 "Id180" 160 "Id160" 140 "Id140" 120 "Id120" 100 "Id100" 90 "Id90" 80 "Id80" 70 "Id70" 60 "Id60" 50 "Id50" 40 "Id40" 30 "Id30" 20 "Id20" 10 "Id10" 1 "Id1" 0 "Inactive" ;
VAL_ 544 AdjustableChimeVol_Rq 15 "NotUsed_3" 14 "NotUsed_2" 13 "NotUsed_1" 12 "LevelPlus6" 11 "LevelPlus5" 10 "LevelPlus4" 9 "LevelPlus3" 8 "LevelPlus2" 7 "LevelPlus1" 6 "LevelMinus1" 5 "LevelMinus2" 4 "LevelMinus3" 3 "LevelMinus4" 2 "LevelMinus5" 1 "LevelMinus6" 0 "DefaultVolume" ;
VAL_ 544 Chime_Occurence 15 "Continuous" 14 "14Repititions" 13 "13Repititions" 12 "12Repititions" 11 "11Repititions" 10 "10Repititions" 9 "9Repititions" 8 "8Repititions" 7 "7Repititions" 6 "6Repititions" 5 "5Repititions" 4 "4Repititions" 3 "3Repititions" 2 "2Repititions" 1 "PlayOnce" 0 "Inactive" ;
VAL_ 544 Chime_Time_Criticality 2 "Low" 1 "High" 0 "Inactive" ;
VAL_ 544 Chime_Directionality 3 "RearSpeakers" 2 "FrontSpeakers" 1 "ALL" 0 "Inactive" ;
VAL_ 291 LangUpdate_Rsp 2 "Language_Not_Supported" 1 "Language_Updated" 0 "Inactive" ;
VAL_ 400 Mc_SetCurrStatMCCh_Rq 7 "MCChannel7" 6 "MCChannel6" 5 "MCChannel5" 4 "MCChannel4" 3 "MCChannel3" 2 "MCChannel2" 1 "MCChannel1" 0 "Inactive" ;
VAL_ 400 Mc_SetCurrentStatOp_Rq 0 "Inactive" 1 "SetCurrentFrequency" 2 "SetCurrentPiCode" 3 "SetCurrentStation" ;
VAL_ 400 Mc_PerTUPresetArea_Rq 13 "reserved" 12 "GetSAT3PresetData" 11 "GetSAT2PresetData" 15 "reserved_last" 10 "GetSAT1PresetData" 9 "GetDAB2PresetData" 8 "GetDAB1PresetData" 7 "GetDAB3PresetData" 6 "GetAmPresetData" 5 "GetAmAstPresetData" 4 "GetFmAstPresetData" 3 "GetFm3PresetData" 2 "GetFm2PresetData" 1 "GetFm1PresetData" 0 "Inactive" ;
VAL_ 647 HEC_BTIncomingCall_Rq 0 "Inactive" 1 "AcceptIncomingCall" 2 "DeclineIncomingCall" ;
VAL_ 647 HEC_BTEndTelService_Rq 1 "EndOngoingTelephonyCall" 0 "Inactive" ;
VAL_ 359 PrplWhlRgenMn_Tq_Actl 8191 "Faulty" ;
VAL_ 359 ElPw_D_StatStrtStop 15 "NotUsed6" 14 "NotUsed5" 13 "NotUsed4" 12 "NotUsed3" 11 "NotUsed2" 10 "NotUsed1" 9 "Supported_Level_4" 8 "Supported_Level_3" 7 "Supported_Level_2" 6 "Supported_Level_1" 5 "Limited_Support" 4 "Fault_Limited" 3 "LV_Event_in_Progress" 2 "Not_Supported_Imminent" 1 "Supported_All" 0 "Not_Supported" ;
VAL_ 359 PrplWhlTot2_Tq_Actl 65535 "Fault" 65534 "NoDataExists" ;
VAL_ 359 LscmbbDeny_B_ActlPrpl 1 "Denied" 0 "Allowed" ;
VAL_ 359 LscmbbEngTqMn_B_Actl 1 "Engine_Braking_Activated" 0 "Engine_Braking_Off" ;
VAL_ 359 PwPckTq_D_Stat 3 "PwPckOn_TqAvailable" 2 "StartInPrgrss_TqNotAvail" 1 "PwPckOn_TqNotAvailable" 0 "PwPckOff_TqNotAvailable" ;
VAL_ 359 Eng_D_Stat 3 "NotUsed" 2 "EngAutoStopped" 1 "EngOn" 0 "EngOff" ;
VAL_ 359 PlgActvArb_B_Actl 1 "On" 0 "Off" ;
VAL_ 359 ElPw_D_Stat 7 "NotUsed_3" 6 "NotUsed_2" 5 "NotUsed_1" 4 "Fault_Limited" 3 "LV_Event_In_Progress" 2 "Not_Supported_Imminent" 1 "Supported" 0 "Not_Supported" ;
VAL_ 359 TrnAinTq_D_Qf 3 "OK" 2 "Not_Within_Specifications" 1 "No_Data_Exists" 0 "Faulty" ;
VAL_ 990 PersIndexDdm_D_Actl 7 "Unused_3" 6 "Unused_2" 5 "Unused_1" 4 "Vehicle" 3 "PERS_4" 2 "PERS_3" 1 "PERS_2" 0 "PERS_1" ;
VAL_ 1091 WakeAlarm2_B_Typ 1 "CanAndEcuDriveCircuit" 0 "CanOnly" ;
VAL_ 1091 CamraRearOn_D2_Stat2 7 "Faulty" 6 "NotUsed_3" 5 "NotUsed_2" 4 "NotUsed_1" 3 "Decommission" 2 "Activate" 1 "Deactivate" 0 "Null" ;
VAL_ 1091 PoliceAux4Lamp_B_Rq2 1 "On" 0 "Off" ;
VAL_ 1091 PoliceAux3Lamp_B_Rq2 1 "On" 0 "Off" ;
VAL_ 1091 PoliceAux2Lamp_B_Rq2 1 "On" 0 "Off" ;
VAL_ 1091 PoliceAux1Lamp_B_Rq2 1 "On" 0 "Off" ;
VAL_ 1091 TowBarMsgTxt_D_Rq 7 "NotUsed3" 6 "NotUsed2" 5 "NotUsed1" 4 "TowBar_Ext_No_Trlr" 3 "Error_Dealer_Fix" 2 "Start_Engine_Swivel" 1 "Check_Tow_Bar" 0 "Null" ;
VAL_ 1091 ParkLampTrlrOut_B_Stat 1 "Out" 0 "Null" ;
VAL_ 1091 StopLampTrlrOut_B_Stat 1 "Out" 0 "Null" ;
VAL_ 1091 TrlrBattChrg_D_Stat 3 "Reverse" 2 "Normal" 1 "Low" 0 "Null" ;
VAL_ 1091 TrlrLampCtl_D_Stat 3 "NotUsed" 2 "TrlrLampCnnctDrvFailure" 1 "TrlrLampNotCnnctDrvFailure" 0 "Null" ;
VAL_ 1091 TrlrAlarmSpprt_D_Stat 3 "SupportedByBrakesAndLights" 2 "SupportedByLights" 1 "SupportedByBrakes" 0 "NotSupported" ;
VAL_ 1091 TurnLampTrlrRr_B_Stat 1 "Out" 0 "Null" ;
VAL_ 1091 TurnLampTrlrRl_B_Stat 1 "Out" 0 "Null" ;
VAL_ 1091 TrlrLampCnnct_B_Actl 1 "Yes" 0 "No" ;
VAL_ 1045 VehStab_D_Stat 15 "Faulty" 14 "No_Data_Exists" 13 "NotUsed6" 12 "NotUsed5" 11 "NotUsed4" 10 "NotUsed3" 9 "NotUsed2" 8 "Combined_OS_and_US" 7 "High_SSRA_no_OS" 6 "Straight" 5 "Post_Oversteer" 4 "Post_Transition" 3 "Countersteer" 2 "Understeer" 1 "Oversteer" 0 "Linear" ;
VAL_ 1045 BrkFluidLvl_D_Stat 3 "Invalid" 2 "Unknown" 1 "Low" 0 "OK" ;
VAL_ 1045 LsmcBrkDecel_D_Stat 7 "NotUsed_3" 6 "NotUsed_2" 5 "NotUsed_1" 4 "Denied" 3 "FaultDegraded" 2 "FaultExt" 1 "On" 0 "Off" ;
VAL_ 1045 VehYawNonLin_W_Rq 4095 "Fault" 4094 "Unknown" ;
VAL_ 1045 VehYawLin_W_Rq 4095 "Fault" 4094 "Unknown" ;
VAL_ 1045 VehVActlBrk_D_Qf 3 "OK" 2 "Not_Within_Specifications" 1 "No_Data_Exists" 0 "Faulty" ;
VAL_ 261 ChrgStatDsply_D_Rq 3 "NotUsed_2" 2 "NotUsed_1" 1 "On" 0 "Off" ;
VAL_ 261 NextUsageTimeToggle_Rq 0 "Inactive" 2 "Disable" 1 "Enable" ;
VAL_ 261 LongTermParking_Rq 2 "On" 1 "Off" 0 "Inactive" ;
VAL_ 261 ModemReset_D_Rq 15 "NotUsed_11" 14 "NotUsed_10" 13 "NotUsed_9" 12 "NotUsed_8" 11 "NotUsed_7" 10 "NotUsed_6" 9 "NotUsed_5" 8 "NotUsed_4" 7 "NotUsed_3" 6 "BrandConnectReset2" 5 "BrandConnectReset1" 4 "CcsReset" 3 "OnlineTrafficReset" 2 "PaakReset" 1 "WifiHotspotReset" 0 "Null" ;
VAL_ 261 StopStrtDrvMde_B_RqBtn3 1 "Pressed" 0 "Not_Pressed" ;
VAL_ 261 AudioToneTouchY_D_Rq 255 "Value254" 2 "Value1_up_to_0xFE_Value253" 1 "Value0" 0 "Null" ;
VAL_ 261 AudioToneTouchX_D_Rq 255 "Value254" 2 "Value1_up_to_0xFE_Value253" 1 "Value0" 0 "Null" ;
VAL_ 261 TCU_ESN_D_Rq 3 "NotUsed" 2 "TCU_ESN_Request" 1 "NoRequest" 0 "Inactive" ;
VAL_ 261 FactoryReset_Rq 1 "ResetFactoryDefaults" 0 "Inactive" ;
VAL_ 261 OffPeakTimeSetType_Rq 4 "WeekendEnd" 3 "WeekendStart" 2 "WeekdayEnd" 1 "WeekdayStart" 0 "Inactive" ;
VAL_ 261 AudioToneTouch_D_Rq 3 "NotUsed" 2 "Enabled" 1 "Disabled" 0 "Null" ;
VAL_ 995 KeyAssocCmplt_B_Rq 1 "Yes" 0 "No" ;
VAL_ 995 FobAssocChime_B_Rq 1 "On" 0 "Off" ;
VAL_ 995 PersIndexBcm_D_Actl 7 "Unused_3" 6 "Unused_2" 5 "Unused_1" 4 "Vehicle" 3 "PERS_4" 2 "PERS_3" 1 "PERS_2" 0 "PERS_1" ;
VAL_ 995 LightAmbIntsty_No_Actl 0 "Off" ;
VAL_ 1000 AHU_Bezel_Diag_St 15 "Reserved" 6 "SignalStrength" 5 "SDARSESNNumber" 4 "SpeakerWalkAround" 3 "CalibrationPartNumber" 2 "HardwarePartNumber" 1 "SoftwarePartNumber" 0 "Inactive_NOP" ;
VAL_ 1000 ThermalReduction_St 15 "Reserved" 14 "_13dB_AudioReduction" 13 "_12dB_AudioReduction" 12 "_11dB_AudioReduction" 11 "_10dB_AudioReduction" 10 "_9dB_AudioReduction" 9 "_8dB_AudioReduction" 8 "_7dB_AudioReduction" 7 "_6dB_AudioReduction" 6 "_5dB_AudioReduction" 5 "_4dB_AudioReduction" 4 "_3dB_AudioReduction" 3 "_2dB_AudioReduction" 2 "_1dB_AudioReduction" 1 "NoAudioReduction" 0 "Null" ;
VAL_ 1000 AHU_Shaker_St 1 "Active" 0 "Inactive" ;
VAL_ 1000 ACM_BeltminderAudioSt 0 "Invalid" 1 "Off" 2 "On" ;
VAL_ 1000 MyKeyVolumeLimitUp 2 "NotUpdated" 1 "Updated" 0 "Invalid" ;
VAL_ 1000 MyKeyVolumeLimitMode 0 "Invalid" 1 "Off" 2 "On" ;
VAL_ 992 MsgCntrPersIndex_D_Rq 7 "Unused_3" 6 "Unused_2" 5 "Unused_1" 4 "Vehicle" 3 "PERS_4" 2 "PERS_3" 1 "PERS_2" 0 "PERS_1" ;
VAL_ 992 MsgCntrDsplyOp_D_Rq 7 "Unused_2" 6 "Unused_1" 5 "Copy" 4 "Restore" 3 "Upload" 2 "Set" 1 "Query" 0 "Null" ;
VAL_ 991 VehPayloadTireP_B_Stat 1 "Yes" 0 "No" ;
VAL_ 991 VehPayloadStew_B_Stat 1 "Yes" 0 "No" ;
VAL_ 991 VehPayloadScrn_D_Stat 7 "CheckLoadScreenActive" 6 "WeightCarryScreenActive" 5 "GooseneckScreenActive" 4 "FifthWheelScreenActive" 3 "WeightDistScreenActive" 2 "AddMassEstScreenActive" 1 "PayloadEstScreenActive" 0 "ScaleScreenNotActive" ;
VAL_ 991 VehPayloadTare_D_Stat 3 "Faulty" 2 "NotUsed" 1 "Request" 0 "NoRequest" ;
VAL_ 991 VehFalr_D_Stat 7 "Faulty" 6 "NotUsed_3" 5 "NotUsed_2" 4 "NotUsed_1" 3 "HeightCorrectionCompleted" 2 "SecondMeasurementCollected" 1 "FirstMeasurementCollected" 0 "NotActive" ;
VAL_ 991 TrlrTngLoad_D_Stat 7 "Faulty" 6 "NoDataExists" 5 "NotUsed_3" 4 "NotUsed_2" 3 "NotUsed_1" 2 "AboveRange" 1 "InRange" 0 "BelowRange" ;
VAL_ 991 Trlr_M_Actl 2047 "Faulty" 2046 "NoDataExists" ;
VAL_ 991 VehPayloadGear_B_Stat 1 "Yes" 0 "No" ;
VAL_ 991 VehPayloadFlat_B_Stat 1 "Yes" 0 "No" ;
VAL_ 991 PersIndexVdm_D_Actl 7 "Unused_3" 6 "Unused_2" 5 "Unused_1" 4 "Vehicle" 3 "PERS_4" 2 "PERS_3" 1 "PERS_2" 0 "PERS_1" ;
VAL_ 1004 TailLghtLoadMde_D_Stat 7 "Faulty" 6 "NotUsed_2" 5 "NotUsed_1" 4 "TailLightModeOverride" 3 "FalrModeActive" 2 "HitchLoadModeActive" 1 "PayloadModeActive" 0 "NoTailLightActive" ;
VAL_ 1004 PersRecallSrc_D_Actl 7 "NotUsed_3" 6 "NotUsed_2" 5 "NotUsed_1" 4 "MemorySwitch" 3 "RemoteStart" 2 "KeyFob" 1 "CenterStack" 0 "Null" ;
VAL_ 1004 Pers4Key_D_Stat 3 "NotUsed_1" 2 "KeyUnAssociated" 1 "KeyAssociated" 0 "Null" ;
VAL_ 1004 Pers3Key_D_Stat 3 "NotUsed_1" 2 "KeyUnAssociated" 1 "KeyAssociated" 0 "Null" ;
VAL_ 1004 Pers2Key_D_Stat 3 "NotUsed_1" 2 "KeyUnAssociated" 1 "KeyAssociated" 0 "Null" ;
VAL_ 1004 Pers1Key_D_Stat 3 "NotUsed_1" 2 "KeyUnAssociated" 1 "KeyAssociated" 0 "Null" ;
VAL_ 1004 EmPrflKeyAssoc_D_Stat 7 "WrongDevice" 6 "KeyAssociateFailed" 5 "KeyAssociateSuccess" 4 "KeyAlreadyInUse" 3 "KeyDisassociated" 2 "KeyAssociationExited" 1 "KeyAssociationEntered" 0 "Null" ;
VAL_ 1004 VehKeyActv_D_Stat 15 "NotUsed7" 14 "NotUsed6" 13 "NotUsed5" 12 "NotUsed4" 11 "NotUsed3" 10 "NotUsed2" 9 "NotUsed1" 8 "Key8Active" 7 "Key7Active" 6 "Key6Active" 5 "Key5Active" 4 "Key4Active" 3 "Key3Active" 2 "Key2Active" 1 "Key1Active" 0 "NoKeyActive" ;
VAL_ 1004 PersSetupRestr_D_Actl 3 "Non_Moveable_Person" 2 "Moveable_Person" 1 "Vehicle" 0 "Factory" ;
VAL_ 1004 PersSetupAccessCtrl 1 "Limited" 0 "Full" ;
VAL_ 1004 PersConflict_D_Actl 1 "Conflict" 0 "No_Conflict" ;
VAL_ 1004 AssocConfirm_D_Actl 0 "None" 7 "Associate" 6 "Keycode_Rejected" 5 "Keycode_Accepted" 4 "In_Progress" 3 "Erase" 2 "Duplicate" 1 "Disassociate" ;
VAL_ 1004 PersNoPos_D_Actl 7 "Unused_3" 6 "Unused_2" 5 "Unused_1" 4 "Vehicle" 3 "PERS_4" 2 "PERS_3" 1 "PERS_2" 0 "PERS_1" ;
VAL_ 1004 PersNo_D_Actl 7 "Unused_3" 6 "Unused_2" 5 "NotDetermined" 4 "Vehicle" 3 "PERS_4" 2 "PERS_3" 1 "PERS_2" 0 "PERS_1" ;
VAL_ 1004 EmPrflNo_D_Stat 7 "NotUsed_3" 6 "NotUsed_2" 5 "NotUsed_1" 4 "Pers4" 3 "Pers3" 2 "Pers2" 1 "Pers1" 0 "Null" ;
VAL_ 813 TimerTripCurnt_T_Dsply 0 "0 second" ;
VAL_ 807 ElDistTripUnit_D_Stat 3 "NotUsed" 2 "Miles" 1 "Kilometers" 0 "Inactive" ;
VAL_ 807 ElDistTripCur_No_Dsply 0 "0 second" ;
VAL_ 1052 AwdDcnntSlipTrgt_B_Rq 1 "Request" 0 "NoRequest" ;
VAL_ 1052 AwdCnnct_D_Stat 3 "Connecting" 2 "Disconnecting" 1 "Connected" 0 "Disconnected" ;
VAL_ 1052 AwdRight_Tq_Rq 4095 "Fault" 4094 "Unknown" ;
VAL_ 1052 AwdRight_Tq_Est 4095 "Fault" 4094 "Unknown" ;
VAL_ 1052 AwdLeft_Tq_Rq 4095 "Fault" 4094 "Unknown" ;
VAL_ 1052 AwdLeft_Tq_Est 4095 "Fault" 4094 "Unknown" ;
VAL_ 1052 AwdLck_Tq_Actl 4095 "Fault" 4094 "Unknown" ;
VAL_ 1052 AwdLckTqNeg_B_Actl 1 "Active" 0 "Inactive" ;
VAL_ 754 ACU_ActChimeType_St 7 "Reserved4" 6 "Reserved3" 5 "Reserved2" 4 "Reserved1" 3 "Sample" 2 "Sine" 1 "No_Chime" 0 "Invalid" ;
VAL_ 729 ACU_VoiceFBVolume_Up 1 "Update" 0 "NoUpdate" ;
VAL_ 729 ACU_TAVolume_Up 1 "Update" 0 "NoUpdate" ;
VAL_ 729 ACU_Reg_St 0 "Invalid" 1 "Off" 2 "On" ;
VAL_ 729 ACU_PhoneVolume_Up 1 "Update" 0 "NoUpdate" ;
VAL_ 729 ACU_NavCmdVolume_Up 1 "Update" 0 "NoUpdate" ;
VAL_ 729 ACU_DSPProgram_St 7 "Reserved2" 6 "Reserved1" 5 "Voice" 4 "Rock" 0 "Invalid" 1 "Normal" 2 "Pop" 3 "Classical" ;
VAL_ 729 ACU_DSP_St 15 "Reserved" 9 "Convertible" 8 "RearSeats" 7 "FrontSeats" 0 "Invalid" 1 "All" 2 "Driver" 3 "Passenger" 4 "Reserved1" 5 "Reserved2" 6 "Reserved3" ;
VAL_ 727 ACU_LoadEjectMode_St 0 "Invalid" 1 "LoadModeInactiveDiscNumIg" 2 "LoadModeActiveDiscNumIgno" 3 "PreparingToLoad" 4 "Insert" 5 "Loading" 6 "PreparingToEject" 7 "Ejecting" 8 "RemoveDisc" ;
VAL_ 727 ACU_LoadEjectDisc_St 0 "Invalid" 1 "Disc1" 2 "Disc2" 3 "Disc3" 4 "Disc4" 5 "Disc5" 6 "Disc6" 7 "All" ;
VAL_ 726 ACU_TAMode_St 0 "Invalid" 1 "TaLocalOn" 2 "TaDistantOn" 3 "TaOff" ;
VAL_ 726 ACU_NEWSMode_St 0 "Invalid" 1 "NewsOn" 2 "NewsOff" ;
VAL_ 726 ACU_AFJump_St 2 "Enabled" 1 "Inhibited" 0 "NoDataExists" ;
VAL_ 369 CrawlMdeActv_B_Stat 1 "On" 0 "Off" ;
VAL_ 369 DrvPerfMde_D_DsplyPt 3 "Sport" 2 "Normal" 1 "NotUsed" 0 "NoModeSelected" ;
VAL_ 369 SeatWorkSrfc_B_Falt 1 "Active" 0 "Inactive" ;
VAL_ 369 TrnIpcDsplyRng_D_Stat 3 "NotUsed" 2 "Flash" 1 "On" 0 "Blank_No_Display" ;
VAL_ 369 TrnIpcDsplyGear_D_Actl 15 "No_Gear_Selected" 14 "_14th_Gear" 13 "_13th_Gear" 12 "_12th_Gear" 11 "_11th_Gear" 10 "_10th_Gear" 9 "_9th_Gear" 8 "_8th_Gear" 7 "_7th_Gear" 6 "_6th_Gear" 5 "_5th_Gear" 4 "_4th_Gear" 3 "_3rd_Gear" 2 "_2nd_Gear" 1 "_1st_Gear" 0 "Neutral" ;
VAL_ 369 TrnIpcDsplyMde_D_Stat 3 "Reserved_Blank_No_Display" 2 "Flash" 1 "On" 0 "Blank_No_Display" ;
VAL_ 369 TrnIpcDsplyMde_D_Actl 7 "Manual_3" 6 "Manual_2" 5 "Manual_1_Low" 4 "Sport" 3 "Drive" 2 "Neutral" 1 "Reverse" 0 "Park" ;
VAL_ 369 TrnIpcDsplyGear_D_Stat 3 "Reserved_Blank_No_Display" 2 "Flash" 1 "On" 0 "Blank_No_Display" ;
VAL_ 369 TrnIpcDsplyRng2_D_Actl 15 "No_Range_Selected" 14 "Range_14" 13 "Range_13" 12 "Range_12" 11 "Range_11" 10 "Range_10" 9 "Range_9" 8 "Range_8" 7 "Range_7" 6 "Range_6" 5 "Range_5" 4 "Range_4" 3 "Range_3" 2 "Range_2" 1 "Range_1" 0 "NotUsed" ;
VAL_ 1071 CluPdlPosPcMeas_D_Qf 3 "OK" 2 "Not_Within_Specifications" 1 "No_Data_Exists" 0 "Faulty" ;
VAL_ 1071 EngMnfld3_P_Actl 255 "Faulty" 254 "NoDataExists" ;
VAL_ 848 RILStat 3 "Fault" 2 "Plant_Mode" 1 "On" 0 "Off" ;
VAL_ 998 PersIndexSccm_D_Actl 7 "Unused_3" 6 "Unused_2" 5 "Unused_1" 4 "Vehicle" 3 "PERS_4" 2 "PERS_3" 1 "PERS_2" 0 "PERS_1" ;
VAL_ 984 LaActvStats_D2_Dsply 31 "Unused7" 30 "LA_Off" 29 "ECE_OFF_RTT" 28 "Unused4" 27 "Unused3" 26 "Unused2" 25 "Unused1" 24 "InerveneLeft_InterveneRght" 23 "WarnLeft_InterveneRight" 22 "SuppressLeft_InterveneRght" 21 "AvailLeft_InterveneRhtt" 20 "NoLeft_InterveneRight" 19 "InterveneLeft_WarnRight" 18 "WarnLeft_WarnRight" 17 "SuppressLeft_WarnRight" 16 "AvailableLeft_WarnRight" 15 "NoLeft_WarnRight" 14 "InterveneLeft_SuppressRght" 13 "WarnLeft_SuppressRight" 12 "SuppressLeft_SuppressRight" 11 "AvailLeft_SuppressRight" 10 "NoLeft_SuppressRight" 9 "InterveneLeft_AvailRight" 8 "WarnLeft_AvailRight" 7 "SuppressLeft_AvailRight" 6 "AvailableLeft_AvailRight" 5 "NoLeft_AvailableRight" 4 "InterveneLeft_NoRight" 3 "WarnLeft_NoRight" 2 "SuppressLeft_NoRight" 1 "AvailableLeft_NoRight" 0 "NoLeft_NoRight" ;
VAL_ 984 AhbFeat_D_Stat 3 "ADB" 2 "GFHB" 1 "AHBC" 0 "None" ;
VAL_ 984 AhbHiBeam_D_Rq 3 "NotUsed" 2 "HighBeamRecommended" 1 "LowBeamRecommended" 0 "DeactivatedUnavailable" ;
VAL_ 984 DsmcMsgTxt_D_Dsply 3 "Blockage" 2 "DriverNotSeen" 1 "Fault" 0 "NoMessage" ;
VAL_ 984 DasWarn_D_Dsply 3 "Undefined" 2 "Warning_Level_2" 1 "Warning_Level_1" 0 "No_Warning" ;
VAL_ 984 DasStats_D_Dsply 3 "Available" 2 "Unavailable_Other" 1 "Feedback_due_to_Speed" 0 "Off" ;
VAL_ 984 DasAlrtLvl_D_Dsply 5 "Alertness_Level_5" 4 "Alertness_Level_4" 3 "Alertness_Level_3" 2 "Alertness_Level_2" 1 "Alertness_Level_1" 0 "Undefined" ;
VAL_ 984 CamraStats_D_Dsply 3 "FrtCam_TempUnavailOther" 2 "FrtCam_TempUnavailVisibile" 1 "Front_Camera_Service_Reqd" 0 "Front_Camera_OK" ;
VAL_ 984 LaHandsOff_D_Dsply 3 "Suppressed" 2 "Level2" 1 "Level1" 0 "HandsOn" ;
VAL_ 984 LaDenyStats_B_Dsply 1 "Unavailable" 0 "Available" ;
VAL_ 984 AhbcRampingV_D_Rq 3 "Slow" 2 "Medium" 1 "Fast" 0 "Immediately" ;
VAL_ 984 CamraDefog_B_Req 1 "On" 0 "Off" ;
VAL_ 984 PersIndexIpma_D_Actl 7 "Unused_3" 6 "Unused_2" 5 "Unused_1" 4 "Vehicle" 3 "PERS_4" 2 "PERS_3" 1 "PERS_2" 0 "PERS_1" ;
VAL_ 1072 PtDrvMde_D_Rq 15 "Faulty" 14 "NotUsed11" 13 "NotUsed10" 12 "NotUsed9" 11 "NotUsed8" 10 "NotUsed7" 9 "NotUsed6" 8 "Track" 7 "Drag" 6 "Rock" 5 "Baja" 4 "Sand" 3 "TowHaulGradeAssist" 2 "SnowWet" 1 "Sport" 0 "Normal" ;
VAL_ 1072 DrvSlipCtlMde_D_Rq 3 "App_Specific_Off_Mode_3" 2 "App_Specific_Off_Mode_2" 1 "App_Specific_Off_Mode_1" 0 "Default_Mode" ;
VAL_ 1072 EngIdlShutDown_B_RqDrv 1 "Inhibit" 0 "No_Inibit" ;
VAL_ 1072 DrvPerfMde_D_Rq 3 "Sport" 2 "Normal" 1 "NotUsed" 0 "NoModeSelected" ;
VAL_ 1072 HsaMde_D_Rq 3 "Undefined" 2 "Manual" 1 "Automatic" 0 "Off" ;
VAL_ 1072 StopStrtDrvMde_D_RqMnu 3 "NotUsed2" 2 "NotUsed1" 1 "StopStart_Deselected" 0 "StopStart_Selected" ;
VAL_ 1072 NtrlTowMdeEnbl_B_RqDrv 1 "Yes" 0 "No" ;
VAL_ 1072 LscmbbStat_B_Actl 1 "On" 0 "Off" ;
VAL_ 1072 BulbChkActv_B_Stat 1 "Active" 0 "Inactive" ;
VAL_ 1072 ParkDetect_Stat 1 "Park" 0 "Not_Park" ;
VAL_ 1072 ReducedGuard_D_Rq 3 "NotUsed" 2 "On" 1 "Off" 0 "Null" ;
VAL_ 1072 FrostWarn_D_Stat 3 "NotUsed" 2 "On_Amber" 1 "On_Red" 0 "Off" ;
VAL_ 1072 TrlrBrkMde_D_Rq 1 "ElectricOverHydraulic" 0 "Electric" ;
VAL_ 1072 TRLR_SWAY_CONFIG_CMD 1 "On" 0 "Off" ;
VAL_ 1072 TRAILER_BRAKE_CONFIG 1 "Yes" 0 "No" ;
VAL_ 1072 Power_Liftgate_Mode_Cmd 1 "Enable" 0 "Disable" ;
VAL_ 1072 AccEnbl_B_RqDrv 1 "Adaptive_Cruise" 0 "Normal_Cruise" ;
VAL_ 1072 HaDsplyCpblty_B_Stat 1 "Available" 0 "NotAvailable" ;
VAL_ 1072 OdometerMasterValue 16777215 "Invalid" ;
VAL_ 1072 EngOilLife_B_RqReset 1 "Yes" 0 "No" ;
VAL_ 1072 MetricActvTe_B_Actl 1 "Active" 0 "Inactive" ;
VAL_ 1072 AccDeny_B_RqIpc 1 "Yes" 0 "No" ;
VAL_ 1072 ePRNDL_MODE 1 "On" 0 "Off" ;
VAL_ 1072 PrkLckCtlEnbl_D_RqIpc 3 "Rq_Towing" 2 "Rq_Enable" 1 "Rq_Disable" 0 "Null" ;
VAL_ 1072 DrvSlipCtlMde_B_Rq2 1 "Pressed" 0 "Not_Pressed" ;
VAL_ 1072 Fda_B_Stat 1 "On" 0 "Off" ;
VAL_ 1072 MetricActv_B_Actl 1 "Active" 0 "Inactive" ;
VAL_ 1072 KeyTypeChngMykey_D_Rq 3 "Search_PE_BackupSlot" 2 "Clear_All_MyKeys" 1 "Request_New_MyKey" 0 "None" ;
VAL_ 1072 ManRgen_D_Rq 3 "NotUsed2" 2 "NotUsed1" 1 "CustInitManExhFilterClean" 0 "No_Customer_Request" ;
VAL_ 395 SelDrvMdeCnfm_D_Stat 3 "NotUsed" 2 "Accepted" 1 "NotAccepted" 0 "Null" ;
VAL_ 395 HudMde_D_Rq 7 "NotUsed3" 6 "NotUsed2" 5 "NotUsed1" 4 "Manual" 3 "Drag" 2 "RoadCourse" 1 "Tach" 0 "Off" ;
VAL_ 395 HudLedMde_D_Rq 3 "Not_Used" 2 "Flash" 1 "On" 0 "Off" ;
VAL_ 395 HudLed9On_B_Rq 1 "On" 0 "Off" ;
VAL_ 395 HudLed8On_B_Rq 1 "On" 0 "Off" ;
VAL_ 395 HudLed7On_B_Rq 1 "On" 0 "Off" ;
VAL_ 395 HudLed6On_B_Rq 1 "On" 0 "Off" ;
VAL_ 395 HudLed5On_B_Rq 1 "On" 0 "Off" ;
VAL_ 395 HudLed4On_B_Rq 1 "On" 0 "Off" ;
VAL_ 395 HudLed3On_B_Rq 1 "On" 0 "Off" ;
VAL_ 395 HudLed2On_B_Rq 1 "On" 0 "Off" ;
VAL_ 395 HudLed1On_B_Rq 1 "On" 0 "Off" ;
VAL_ 395 HudLed18On_B_Rq 1 "On" 0 "Off" ;
VAL_ 395 HudLed17On_B_Rq 1 "On" 0 "Off" ;
VAL_ 395 HudLed16On_B_Rq 1 "On" 0 "Off" ;
VAL_ 395 HudLed15On_B_Rq 1 "On" 0 "Off" ;
VAL_ 395 HudLed14On_B_Rq 1 "On" 0 "Off" ;
VAL_ 395 HudLed13On_B_Rq 1 "On" 0 "Off" ;
VAL_ 395 HudLed12On_B_Rq 1 "On" 0 "Off" ;
VAL_ 395 HudLed11On_B_Rq 1 "On" 0 "Off" ;
VAL_ 395 HudLed10On_B_Rq 1 "On" 0 "Off" ;
VAL_ 76 AirbagDrv_D_Actv 3 "Faulty" 2 "On" 1 "Off" 0 "NotAvailable" ;
VAL_ 76 RstrnPsngrOn_D_Stat 15 "Faulty" 14 "NotUsed_11" 13 "NotUsed_10" 12 "ConfiguredOff" 11 "NotUsed_9" 10 "On" 9 "NotUsed_8" 8 "NotUsed_7" 7 "NotUsed_6" 6 "NotUsed_5" 5 "Off" 4 "NotUsed_4" 3 "NotUsed_3" 2 "NotUsed_2" 1 "NotUsed_1" 0 "NoAction" ;
VAL_ 76 PsngrFmidDetct_D_Actl 3 "Unknown" 2 "Empty" 1 "Occupied" 0 "Fault" ;
VAL_ 76 FirstRowBuckleMid 3 "Unknown" 2 "Unbelted" 1 "Belted" 0 "Faulty" ;
VAL_ 76 ThirdRowBucklePsngr 3 "Unknown" 2 "Unbelted" 1 "Belted" 0 "Faulty" ;
VAL_ 76 ThirdRowBuckleMid 3 "Unknown" 2 "Unbelted" 1 "Belted" 0 "Faulty" ;
VAL_ 76 ThirdRowBuckleDriver 3 "Unknown" 2 "Unbelted" 1 "Belted" 0 "Faulty" ;
VAL_ 76 SecondRowBucklePsngr 3 "Unknown" 2 "Unbelted" 1 "Belted" 0 "Faulty" ;
VAL_ 76 SecondRowBuckleMid 3 "Unknown" 2 "Unbelted" 1 "Belted" 0 "Faulty" ;
VAL_ 76 SecondRowBuckleDriver 3 "Unknown" 2 "Unbelted" 1 "Belted" 0 "Faulty" ;
VAL_ 76 FirstRowBuckleDriver 3 "Unknown" 2 "Unbelted" 1 "Belted" 0 "Faulty" ;
VAL_ 76 RILReq 3 "Not_Used" 2 "Plant_Mode" 1 "On" 0 "Off" ;
VAL_ 76 FirstRowBucklePsngr 3 "Unknown" 2 "Unbelted" 1 "Belted" 0 "Faulty" ;
VAL_ 76 RstrnImpactEvntStatus 7 "Invalid" 6 "Not_Used_4" 5 "Threshold_2_Exceeded" 4 "Not_Used_3" 3 "Threshold_1_Exceeded" 2 "Not_Used_2" 1 "Not_Used_1" 0 "Normal" ;
VAL_ 76 PsngrFrntDetct_D_Actl 3 "Unknown" 2 "Empty" 0 "Faulty" 1 "Occupied" ;
VAL_ 76 PassRstrnInd_Req 3 "ABOnNotIllum_OffNotIllum" 2 "AirbagOnNot_Illum_OffIllum" 1 "AirbagOn_Illum_OffNotIllum" 0 "AirbagOn_Illum_Off_Illum" ;
VAL_ 76 EDRTriggerEvntSync 1 "Threshold_Exceeded" 0 "Normal" ;
VAL_ 1069 IsaOffst_D_Stat 15 "Faulty" 14 "Null" 13 "Thirteen" 12 "Twelve" 11 "Eleven" 10 "Ten" 9 "Nine" 8 "Eight" 7 "Seven" 6 "Six" 5 "Five" 4 "Four" 3 "Three" 2 "Two" 1 "One" 0 "Zero" ;
VAL_ 1069 EngOilMaint_B_Stat 1 "On" 0 "Off" ;
VAL_ 1069 ReFuelSysStat_D_Dsply 7 "NotUsed3" 6 "NotUsed2" 5 "NotUsed1" 4 "Refuel_Err" 3 "Close_Fuel_Door" 2 "Refuel_Ready" 1 "Wait_To_Fuel" 0 "Null" ;
VAL_ 1069 SlMde_D_Stat 3 "IsaNotConfigured" 2 "Manual_Mode" 1 "Auto_Mode" 0 "Null" ;
VAL_ 1069 SlMde_D_RqDsply 3 "NotUsed" 2 "ManualSpeed_LimiterSymbol" 1 "AutoSpeed_LimiterSymbol" 0 "NoSpeed_LimiterSymbol" ;
VAL_ 1069 ULoSrcOnPlg_B_Cmd 1 "Activate" 0 "Deactivate" ;
VAL_ 1069 EngAirIn_Te_Actl 1023 "Fault" 1022 "Unknown" ;
VAL_ 1069 GrllShtrPos_B_Falt 1 "Fault" 0 "No_Fault" ;
VAL_ 1069 EngMsgTxt_D_Rq 3 "Undefined_2" 2 "Undefined_1" 1 "Power_Reduced_to_LowerTemp" 0 "No_Message" ;
VAL_ 1069 TracKeyMdeEnbl_B_Stat 1 "On" 0 "Off" ;
VAL_ 1069 ObdWarmUp_B_Complt 1 "Yes" 0 "No" ;
VAL_ 1069 GrllShtrPos_D_Cmd 15 "Fully_Open" 14 "Position14" 13 "Position13" 12 "Position12" 11 "Position11" 10 "Position10" 9 "Position9" 8 "Position8" 7 "Position7" 6 "Position6" 5 "Position5" 4 "Position4" 3 "Position3" 2 "Position2" 1 "Position1" 0 "Fully_Closed" ;
VAL_ 1057 FohEng_D_Rq 3 "AutoEnable_ParkEnable" 2 "AutoDisable_ParkEnable" 1 "AutoEnable_ParkDisable" 0 "Disable_Stop" ;
VAL_ 1057 EngIdlShutDwnTxt_D_Rq 3 "NotUsed" 2 "EngineShutdownOnPrevDrive" 1 "FeatureDisabledDueToFault" 0 "NoMessage" ;
VAL_ 1057 EngIdlShutDown_D_Stat 3 "Not_used" 2 "Engine_Shutdown" 1 "Initiated_Countdown" 0 "Normal_Operation" ;
VAL_ 1057 FUEL_ALCOHOL_PERCNT 255 "Invalid" ;
VAL_ 1057 TrnTotTq_Rt_Est 65535 "Fault" 65534 "Unknown" ;
VAL_ 1057 TrnTotLss_Tq_Est 255 "Fault" 254 "Unknown" ;
VAL_ 1057 ECMMILRequest 3 "Not_Used" 2 "Flash" 1 "On" 0 "Off" ;
VAL_ 1057 AirCondFluidHi_P_Actl 255 "Fault" 254 "Unknown" ;
VAL_ 1057 OilPressureWarning 1 "Low_Pressure_Lamp_On" 0 "Normal_Pressure_Lamp_Off" ;
VAL_ 1057 VehVLimStat_D_Actl 7 "Undefined_3" 6 "Undefined_2" 5 "Undefined_1" 4 "ASL_Fault_Condition" 3 "Active_and_Limiting" 2 "Active_but_Not_Limiting" 1 "Standby" 0 "Off" ;
VAL_ 1057 VehVLimActv_B_Actl 1 "Active" 0 "Inactive" ;
VAL_ 1057 CoolantFanStepAct 31 "Unused7" 30 "Unused6" 29 "Unused5" 28 "Unused4" 27 "Unused3" 26 "Unused2" 25 "Unused1" 23 "Step23" 22 "Step22" 21 "Step21" 20 "Step20" 19 "Step19" 18 "Step18" 17 "Step17" 16 "Step16" 15 "Step15" 14 "Step14" 13 "Step13" 12 "Step12" 11 "Step11" 10 "Step10" 9 "Step9" 8 "Step8" 7 "Step7" 6 "Step6" 5 "Step5" 4 "Step4" 3 "Step3" 2 "Step2" 1 "Step1" 24 "Max_Fan_Speed_Req" 0 "Fan_Cmd_Off" ;
